[part 2 of 3: package /RB/PT/PCT_TopLvlComposition/SwComponentTypes]
AUTOSAR XML (schema 4-0-3)
package /RB/PT/PCT_TopLvlComposition/SwComponentTypes  (continued)
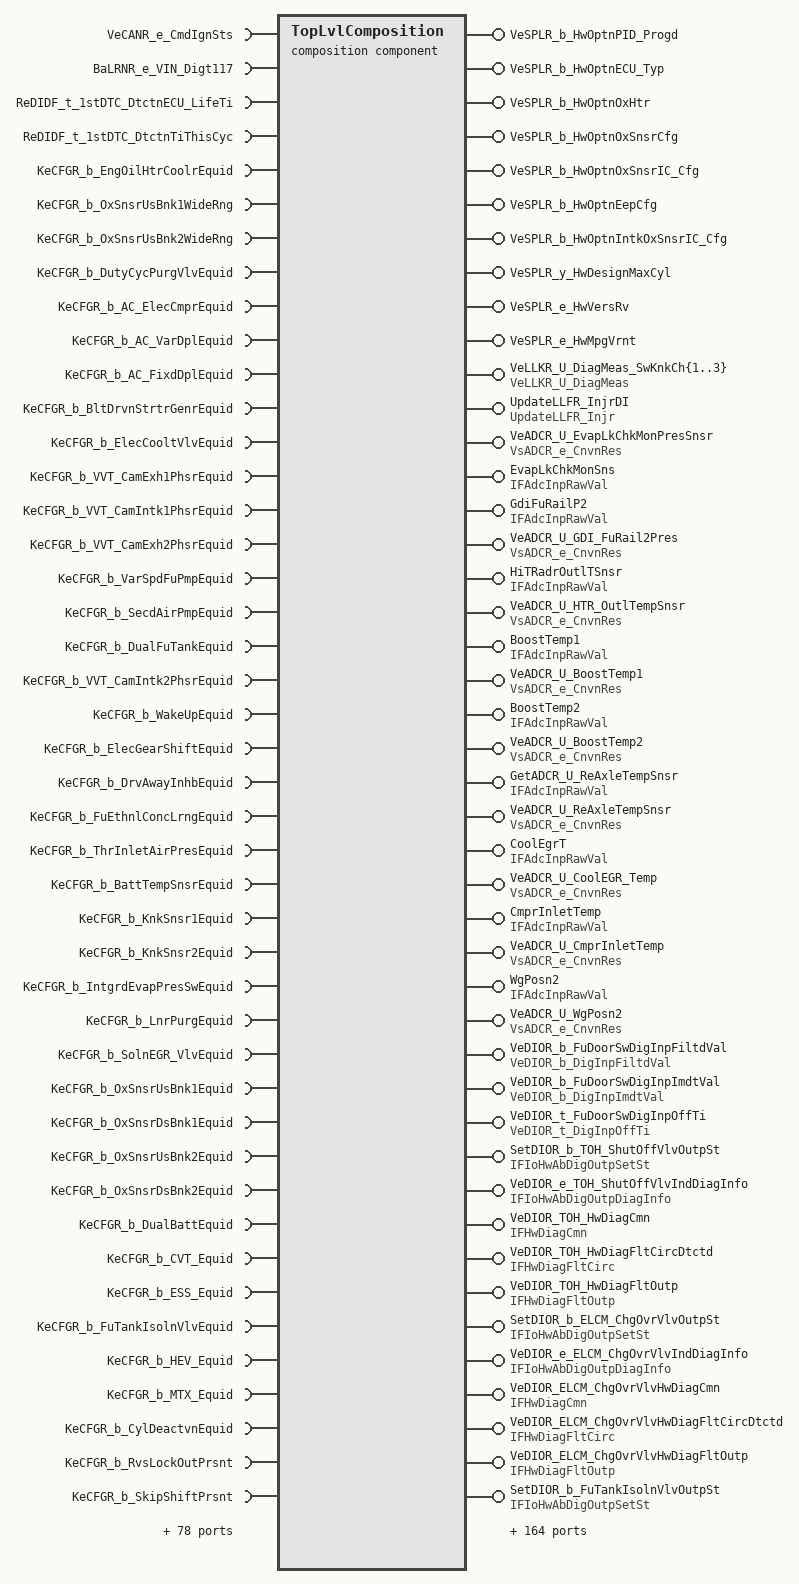
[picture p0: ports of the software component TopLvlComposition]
  composition sw component type TopLvlComposition  (continued)
    66 x require port:
      VeCANR_e_CmdIgnSts: required-interface=VeCANR_e_CmdIgnSts
      BaLRNR_e_VIN_Digt117: required-interface=BaLRNR_e_VIN_Digt117
      ReDIDF_t_1stDTC_DtctnECU_LifeTi: required-interface=ReDIDF_t_1stDTC_DtctnECU_LifeTi
      ReDIDF_t_1stDTC_DtctnTiThisCyc: required-interface=ReDIDF_t_1stDTC_DtctnTiThisCyc
      KeCFGR_b_EngOilHtrCoolrEquid: required-interface=KeCFGR_b_EngOilHtrCoolrEquid
      KeCFGR_b_OxSnsrUsBnk1WideRng: required-interface=KeCFGR_b_OxSnsrUsBnk1WideRng
      KeCFGR_b_OxSnsrUsBnk2WideRng: required-interface=KeCFGR_b_OxSnsrUsBnk2WideRng
      KeCFGR_b_DutyCycPurgVlvEquid: required-interface=KeCFGR_b_DutyCycPurgVlvEquid
      KeCFGR_b_AC_ElecCmprEquid: required-interface=KeCFGR_b_AC_ElecCmprEquid
      KeCFGR_b_AC_VarDplEquid: required-interface=KeCFGR_b_AC_VarDplEquid
      KeCFGR_b_AC_FixdDplEquid: required-interface=KeCFGR_b_AC_FixdDplEquid
      KeCFGR_b_BltDrvnStrtrGenrEquid: required-interface=KeCFGR_b_BltDrvnStrtrGenrEquid
      KeCFGR_b_ElecCooltVlvEquid: required-interface=KeCFGR_b_ElecCooltVlvEquid
      KeCFGR_b_VVT_CamExh1PhsrEquid: required-interface=KeCFGR_b_VVT_CamExh1PhsrEquid
      KeCFGR_b_VVT_CamIntk1PhsrEquid: required-interface=KeCFGR_b_VVT_CamIntk1PhsrEquid
      KeCFGR_b_VVT_CamExh2PhsrEquid: required-interface=KeCFGR_b_VVT_CamExh2PhsrEquid
      KeCFGR_b_VarSpdFuPmpEquid: required-interface=KeCFGR_b_VarSpdFuPmpEquid
      KeCFGR_b_SecdAirPmpEquid: required-interface=KeCFGR_b_SecdAirPmpEquid
      KeCFGR_b_DualFuTankEquid: required-interface=KeCFGR_b_DualFuTankEquid
      KeCFGR_b_VVT_CamIntk2PhsrEquid: required-interface=KeCFGR_b_VVT_CamIntk2PhsrEquid
      KeCFGR_b_WakeUpEquid: required-interface=KeCFGR_b_WakeUpEquid
      KeCFGR_b_ElecGearShiftEquid: required-interface=KeCFGR_b_ElecGearShiftEquid
      KeCFGR_b_DrvAwayInhbEquid: required-interface=KeCFGR_b_DrvAwayInhbEquid
      KeCFGR_b_FuEthnlConcLrngEquid: required-interface=KeCFGR_b_FuEthnlConcLrngEquid
      KeCFGR_b_ThrInletAirPresEquid: required-interface=KeCFGR_b_ThrInletAirPresEquid
      KeCFGR_b_BattTempSnsrEquid: required-interface=KeCFGR_b_BattTempSnsrEquid
      KeCFGR_b_KnkSnsr1Equid: required-interface=KeCFGR_b_KnkSnsr1Equid
      KeCFGR_b_KnkSnsr2Equid: required-interface=KeCFGR_b_KnkSnsr2Equid
      KeCFGR_b_IntgrdEvapPresSwEquid: required-interface=KeCFGR_b_IntgrdEvapPresSwEquid
      KeCFGR_b_LnrPurgEquid: required-interface=KeCFGR_b_LnrPurgEquid
      KeCFGR_b_SolnEGR_VlvEquid: required-interface=KeCFGR_b_SolnEGR_VlvEquid
      KeCFGR_b_OxSnsrUsBnk1Equid: required-interface=KeCFGR_b_OxSnsrUsBnk1Equid
      KeCFGR_b_OxSnsrDsBnk1Equid: required-interface=KeCFGR_b_OxSnsrDsBnk1Equid
      KeCFGR_b_OxSnsrUsBnk2Equid: required-interface=KeCFGR_b_OxSnsrUsBnk2Equid
      KeCFGR_b_OxSnsrDsBnk2Equid: required-interface=KeCFGR_b_OxSnsrDsBnk2Equid
      KeCFGR_b_DualBattEquid: required-interface=KeCFGR_b_DualBattEquid
      KeCFGR_b_CVT_Equid: required-interface=KeCFGR_b_CVT_Equid
      KeCFGR_b_ESS_Equid: required-interface=KeCFGR_b_ESS_Equid
      KeCFGR_b_FuTankIsolnVlvEquid: required-interface=KeCFGR_b_FuTankIsolnVlvEquid
      KeCFGR_b_HEV_Equid: required-interface=KeCFGR_b_HEV_Equid
      KeCFGR_b_MTX_Equid: required-interface=KeCFGR_b_MTX_Equid
      KeCFGR_b_CylDeactvnEquid: required-interface=KeCFGR_b_CylDeactvnEquid
      KeCFGR_b_RvsLockOutPrsnt: required-interface=KeCFGR_b_RvsLockOutPrsnt
      KeCFGR_b_SkipShiftPrsnt: required-interface=KeCFGR_b_SkipShiftPrsnt
      KeCFGR_b_DualLiftEquid: required-interface=KeCFGR_b_DualLiftEquid
      KeCFGR_b_VVT_Equid: required-interface=KeCFGR_b_VVT_Equid
      KeCFGR_b_ImobEquid: required-interface=KeCFGR_b_ImobEquid
      KeCFGR_b_ImobKeyLock: required-interface=KeCFGR_b_ImobKeyLock
      KeCFGR_b_ElecVacPmpEquid: required-interface=KeCFGR_b_ElecVacPmpEquid
      KeCFGR_b_DualVarSpdFuPmpEquid: required-interface=KeCFGR_b_DualVarSpdFuPmpEquid
      KeCFGR_b_CNG_Equid: required-interface=KeCFGR_b_CNG_Equid
      KeCFGR_b_DirectInjSysEquid: required-interface=KeCFGR_b_DirectInjSysEquid
      KeCFGR_b_ElectcATX_Equid: required-interface=KeCFGR_b_ElectcATX_Equid
      KeCFGR_e_FanTypEquid: required-interface=KeCFGR_e_FanTypEquid
      KeCFGR_b_FuTankHiPresSnsrEquid: required-interface=KeCFGR_b_FuTankHiPresSnsrEquid
      KeCFGR_b_HTR_MeclCooltPmpEquid: required-interface=KeCFGR_b_HTR_MeclCooltPmpEquid
      KeCFGR_b_IBS_Equid: required-interface=KeCFGR_b_IBS_Equid
      KeCFGR_b_IBS_3Equid: required-interface=KeCFGR_b_IBS_3Equid
      KeCFGR_b_VVA_Equid: required-interface=KeCFGR_b_VVA_Equid
      KeCFGR_e_EngOilPmpEquid: required-interface=KeCFGR_e_EngOilPmpEquid
      KeCFGR_b_EngOilPresSnsrAnEquid: required-interface=KeCFGR_b_EngOilPresSnsrAnEquid
      KeCFGR_b_ShoRunrVlvEquid: required-interface=KeCFGR_b_ShoRunrVlvEquid
      KeCFGR_b_SupChrgrEquid: required-interface=KeCFGR_b_SupChrgrEquid
      KeCFGR_b_TrboChrgrEquid: required-interface=KeCFGR_b_TrboChrgrEquid
      KeCFGR_e_VehCAN_CfgArch: required-interface=KeCFGR_e_VehCAN_CfgArch
      KeECFR_Cnt_NrOfCyl: required-interface=KeECFR_Cnt_NrOfCyl
    10 x provide port:
      VeSPLR_b_HwOptnPID_Progd: provided-interface=VeSPLR_b_HwOptnPID_Progd
      VeSPLR_b_HwOptnECU_Typ: provided-interface=VeSPLR_b_HwOptnECU_Typ
      VeSPLR_b_HwOptnOxHtr: provided-interface=VeSPLR_b_HwOptnOxHtr
      VeSPLR_b_HwOptnOxSnsrCfg: provided-interface=VeSPLR_b_HwOptnOxSnsrCfg
      VeSPLR_b_HwOptnOxSnsrIC_Cfg: provided-interface=VeSPLR_b_HwOptnOxSnsrIC_Cfg
      VeSPLR_b_HwOptnEepCfg: provided-interface=VeSPLR_b_HwOptnEepCfg
      VeSPLR_b_HwOptnIntkOxSnsrIC_Cfg: provided-interface=VeSPLR_b_HwOptnIntkOxSnsrIC_Cfg
      VeSPLR_y_HwDesignMaxCyl: provided-interface=VeSPLR_y_HwDesignMaxCyl
      VeSPLR_e_HwVersRv: provided-interface=VeSPLR_e_HwVersRv
      VeSPLR_e_HwMpgVrnt: provided-interface=VeSPLR_e_HwMpgVrnt
    require port VsSSKR_h_MIL_Req: required-interface=VsSSKR_h_MIL_Req
    provide port VeLLKR_U_DiagMeas_SwKnkCh{1..3}: provided-interface=VeLLKR_U_DiagMeas
    require port VeCLUR_b_UsPID_EnbldBnk1: required-interface=VeCLUR_b_UsPID_EnbldBnk1
    require port VeFPCR_b_InjrLrnLimpFlg: required-interface=VeFPCR_b_InjrLrnLimpFlg
    provide port UpdateLLFR_InjrDI: provided-interface=UpdateLLFR_Injr
    provide port VeADCR_U_EvapLkChkMonPresSnsr: provided-interface=VsADCR_e_CnvnRes
    provide port EvapLkChkMonSns: provided-interface=IFAdcInpRawVal
    require port KeCFGR_b_EvapLkChkMonSnsAdcInpEquid: required-interface=IO_ChEquid
    require port KeCFGR_b_GdiFuRailP2AdcInpEquid: required-interface=IO_ChEquid
    4 x provide port:
      GdiFuRailP2: provided-interface=IFAdcInpRawVal
      VeADCR_U_GDI_FuRail2Pres: provided-interface=VsADCR_e_CnvnRes
      HiTRadrOutlTSnsr: provided-interface=IFAdcInpRawVal
      VeADCR_U_HTR_OutlTempSnsr: provided-interface=VsADCR_e_CnvnRes
    require port KeCFGR_b_HiTRadrOutlTSnsrAdcInpEquid: required-interface=IO_ChEquid
    require port KeCFGR_b_BoostTemp1AdcInpEquid: required-interface=IO_ChEquid
    provide port BoostTemp1: provided-interface=IFAdcInpRawVal
    provide port VeADCR_U_BoostTemp1: provided-interface=VsADCR_e_CnvnRes
    require port KeCFGR_b_BoostTemp2AdcInpEquid: required-interface=IO_ChEquid
    4 x provide port:
      BoostTemp2: provided-interface=IFAdcInpRawVal
      VeADCR_U_BoostTemp2: provided-interface=VsADCR_e_CnvnRes
      GetADCR_U_ReAxleTempSnsr: provided-interface=IFAdcInpRawVal
      VeADCR_U_ReAxleTempSnsr: provided-interface=VsADCR_e_CnvnRes
    require port KeCFGR_b_ReAxleTempSnsrAdcInpEquid: required-interface=IO_ChEquid
    provide port CoolEgrT: provided-interface=IFAdcInpRawVal
    provide port VeADCR_U_CoolEGR_Temp: provided-interface=VsADCR_e_CnvnRes
    require port KeCFGR_b_CoolEgrTAdcInpEquid: required-interface=IO_ChEquid
    provide port CmprInletTemp: provided-interface=IFAdcInpRawVal
    provide port VeADCR_U_CmprInletTemp: provided-interface=VsADCR_e_CnvnRes
    require port KeCFGR_b_CmprInletTempAdcInpEquid: required-interface=IO_ChEquid
    provide port WgPosn2: provided-interface=IFAdcInpRawVal
    provide port VeADCR_U_WgPosn2: provided-interface=VsADCR_e_CnvnRes
    require port KeCFGR_b_WgPosn2AdcInpEquid: required-interface=IO_ChEquid
    provide port VeDIOR_b_FuDoorSwDigInpFiltdVal: provided-interface=VeDIOR_b_DigInpFiltdVal
    provide port VeDIOR_b_FuDoorSwDigInpImdtVal: provided-interface=VeDIOR_b_DigInpImdtVal
    provide port VeDIOR_t_FuDoorSwDigInpOffTi: provided-interface=VeDIOR_t_DigInpOffTi
    require port KeCFGR_b_FuDoorDigInpEquid: required-interface=IO_ChEquid
    5 x provide port:
      SetDIOR_b_TOH_ShutOffVlvOutpSt: provided-interface=IFIoHwAbDigOutpSetSt
      VeDIOR_e_TOH_ShutOffVlvIndDiagInfo: provided-interface=IFIoHwAbDigOutpDiagInfo
      VeDIOR_TOH_HwDiagCmn: provided-interface=IFHwDiagCmn
      VeDIOR_TOH_HwDiagFltCircDtctd: provided-interface=IFHwDiagFltCirc
      VeDIOR_TOH_HwDiagFltOutp: provided-interface=IFHwDiagFltOutp
    require port KeCFGR_b_TOH_ChEquid: required-interface=IO_ChEquid
    5 x provide port:
      SetDIOR_b_ELCM_ChgOvrVlvOutpSt: provided-interface=IFIoHwAbDigOutpSetSt
      VeDIOR_e_ELCM_ChgOvrVlvIndDiagInfo: provided-interface=IFIoHwAbDigOutpDiagInfo
      VeDIOR_ELCM_ChgOvrVlvHwDiagCmn: provided-interface=IFHwDiagCmn
      VeDIOR_ELCM_ChgOvrVlvHwDiagFltCircDtctd: provided-interface=IFHwDiagFltCirc
      VeDIOR_ELCM_ChgOvrVlvHwDiagFltOutp: provided-interface=IFHwDiagFltOutp
    require port KeCFGR_b_ELCM_ChgOvrVlv_ChEquid: required-interface=IO_ChEquid
    5 x provide port:
      SetDIOR_b_FuTankIsolnVlvOutpSt: provided-interface=IFIoHwAbDigOutpSetSt
      VeDIOR_e_FuTankIsolnVlvIndDiagInfo: provided-interface=IFIoHwAbDigOutpDiagInfo
      VeDIOR_FuTankIsolnVlvHwDiagCmn: provided-interface=IFHwDiagCmn
      VeDIOR_FuTankIsolnVlvHwDiagFltCircDtctd: provided-interface=IFHwDiagFltCirc
      VeDIOR_FuTankIsolnVlvHwDiagFltOutp: provided-interface=IFHwDiagFltOutp
    require port KeCFGR_b_FuTankIsolnVlv_ChEquid: required-interface=IO_ChEquid
    5 x provide port:
      SetDIOR_b_FuDoorOutpSt: provided-interface=IFIoHwAbDigOutpSetSt
      VeDIOR_e_FuDoorIndDiagInfo: provided-interface=IFIoHwAbDigOutpDiagInfo
      VeDIOR_FuDoor_HwDiagCmn: provided-interface=IFHwDiagCmn
      VeDIOR_FuDoor_HwDiagFltCircDtctd: provided-interface=IFHwDiagFltCirc
      VeDIOR_FuDoor_HwDiagFltOutp: provided-interface=IFHwDiagFltOutp
    require port KeCFGR_b_FuDoor_ChEquid: required-interface=IO_ChEquid
    5 x provide port:
      SetDIOR_b_SrgSoln2OutpSt: provided-interface=IFIoHwAbDigOutpSetSt
      VeDIOR_e_SrgSoln2IndDiagInfo: provided-interface=IFIoHwAbDigOutpDiagInfo
      VeDIOR_SrgSoln2_HwDiagCmn: provided-interface=IFHwDiagCmn
      VeDIOR_SrgSoln2_HwDiagFltCircDtctd: provided-interface=IFHwDiagFltCirc
      VeDIOR_SrgSoln2_HwDiagFltOutp: provided-interface=IFHwDiagFltOutp
    require port KeCFGR_b_SrgSoln2_ChEquid: required-interface=IO_ChEquid
    5 x provide port:
      SetDIOR_b_DualFuTankEnblRlyOutpSt: provided-interface=IFIoHwAbDigOutpSetSt
      VeDIOR_e_DualFuTankEnblRlyIndDiagInfo: provided-interface=IFIoHwAbDigOutpDiagInfo
      VeDIOR_DualFuTankEnblRly_HwDiagCmn: provided-interface=IFHwDiagCmn
      VeDIOR_DualFuTankEnblRly_HwDiagFltCircDtctd: provided-interface=IFHwDiagFltCirc
      VeDIOR_DualFuTankEnblRly_HwDiagFltOutp: provided-interface=IFHwDiagFltOutp
    require port KeCFGR_b_DualFuTankEnblRly_ChEquid: required-interface=IO_ChEquid
    provide port GetSNTR_e_CEGR_PosnSns: provided-interface=GetSNTR_MsgData
    provide port GetSNTR_e_GPF_DeltAbsPresSnsr1: provided-interface=GetSNTR_MsgData
    provide port GetSNTR_e_GPF_DeltAbsPresSnsr2: provided-interface=GetSNTR_MsgData
    6 x require port:
      KeCFGR_b_CEGR_PosnSnsChEquid: required-interface=IO_ChEquid
      KsSNTR_h_DeltAbsPresSnsr1_SENTCfg: required-interface=SENTIfCfg
      KsSNTR_h_DeltAbsPresSnsr2_SENTCfg: required-interface=SENTIfCfg
      KeCFGR_b_GPF_DeltAbsPresSnsr2Equid: required-interface=IO_ChEquid
      KeCFGR_b_GPF_DeltAbsPresSnsr1Equid: required-interface=IO_ChEquid
      KsSNTR_h_CEGR_PosnSns_SENTCfg: required-interface=SENTIfCfg
    25 x provide port:
      SetDIOR_e_PurgSoln2_OutpOps: provided-interface=IFIoHwAbPWMOutpSet
      VeDIOR_e_PurgSoln2_IndDiagInfo: provided-interface=IFIoHwAbPwmOutpDiagInfo
      SetDIOR_e_ELCM_VacPmpOutpOps: provided-interface=IFIoHwAbPWMOutpSet
      SetDIOR_e_WgSolnOutpOps: provided-interface=IFIoHwAbPWMOutpSet
      SetDIOR_e_FuPmpCtlMdul2CmdOutpOps: provided-interface=IFIoHwAbPWMOutpSet
      SetDIOR_e_HTR_TempCtrlVlvSolnOutpOps: provided-interface=IFIoHwAbPWMOutpSet
      VeDIOR_e_ELCM_VacPmpIndDiagInfo: provided-interface=IFIoHwAbPwmOutpDiagInfo
      VeDIOR_e_WgSolnIndDiagInfo: provided-interface=IFIoHwAbPwmOutpDiagInfo
      VeDIOR_e_FuPmpCtlMdul2CmdIndDiagInfo: provided-interface=IFIoHwAbPwmOutpDiagInfo
      VeDIOR_e_HTR_TempCtrlVlvSolnIndDiagInfo: provided-interface=IFIoHwAbPwmOutpDiagInfo
      VeDIOR_PurgSoln2_HwDiagFltOutp: provided-interface=IFHwDiagFltOutp
      VeDIOR_ELCM_VacPmp_HwDiagFltOutp: provided-interface=IFHwDiagFltOutp
      VeDIOR_WgSoln_HwDiagFltOutp: provided-interface=IFHwDiagFltOutp
      VeDIOR_FuPmpCtlMdul2Cmd_HwDiagFltOutp: provided-interface=IFHwDiagFltOutp
      VeDIOR_HTR_TempCtrlVlvSoln_HwDiagFltOutp: provided-interface=IFHwDiagFltOutp
      VeDIOR_PurgSoln2_HwDiagCmn: provided-interface=IFHwDiagCmn
      VeDIOR_ELCM_VacPmp_HwDiagCmn: provided-interface=IFHwDiagCmn
      VeDIOR_WgSoln_HwDiagCmn: provided-interface=IFHwDiagCmn
      VeDIOR_FuPmpCtlMdul2Cmd_HwDiagCmn: provided-interface=IFHwDiagCmn
      VeDIOR_HTR_TempCtrlVlvSoln_HwDiagCmn: provided-interface=IFHwDiagCmn
      VeDIOR_PurgSoln2_HwDiagFltCircDtctd: provided-interface=IFHwDiagFltCirc
      VeDIOR_ELCM_VacPmp_HwDiagFltCircDtctd: provided-interface=IFHwDiagFltCirc
      VeDIOR_WgSoln_HwDiagFltCircDtctd: provided-interface=IFHwDiagFltCirc
      VeDIOR_FuPmpCtlMdul2Cmd_HwDiagFltCircDtctd: provided-interface=IFHwDiagFltCirc
      VeDIOR_HTR_TempCtrlVlvSoln_HwDiagFltCircDtctd: provided-interface=IFHwDiagFltCirc
    5 x require port, all with required-interface=IO_ChEquid:
      KeCFGR_b_PurgSoln2_ChEquid
      KeCFGR_b_ELCM_VacPmp_ChEquid
      KeCFGR_b_WgSoln_ChEquid
      KeCFGR_b_FuPmpCtlMdul2Cmd_ChEquid
      KeCFGR_b_HTR_TempCtrlVlvSoln_ChEquid
    provide port VeEVIR_t_EvapSysPresSwExclPrd: provided-interface=VeEVIR_t_EvapSysPresSwExclPrd
    provide port VeLLTR_t_ShutDwnTmr: provided-interface=VeLLTR_t_ShutDwnTmr
    4 x require port:
      RP_MilHndlr_InPlaModeActvSts: required-interface=VeIPMR_b_EOL_InPlaMode
      RP_MilHndlr_InPlaModeMILReqSts: required-interface=VeIPMR_b_EOL_MIL_Req
      RP_MilHndlr_ExternalMilReq: required-interface=VsSSKR_h_MIL_Req
      RP_MilHndlr_CatDmgingMilReq: required-interface=VeMFDR_b_CatFls_MIL
    6 x provide port:
      VeLINR_b_LTR_RespErrLTR_Pmp: provided-interface=VeLINR_b_LTR_RespErrLTR_Pmp
      SendLINR_LCVM_CalRqrd: provided-interface=SendLINR_LCVM_CalRqrd
      VeLINR_Pct_LCVM_PosnActr: provided-interface=VeLINR_Pct_LCVM_PosnActr
      VeLINR_e_PCPM_DryRunErr: provided-interface=VeLINR_e_PCPM_DryRunErr
      VeLINR_e_LTR_PmpDryRunErr: provided-interface=VeLINR_e_LTR_PmpDryRunErr
      SendLINR_PLA_ReqData: provided-interface=SendLINR_PLA_ReqData
    6 x require port:
      SendCANR_HoursOilLifeRst_FD3Vld: required-interface=SendCANR_HoursOilLifeRst_FD3Vld
      VeSSFR_b_LvlInitMdulRstReq: required-interface=IF_VeSSFR_b_LvlInitMdulRstReq
      VeSSRR_b_L2_MdulRstReqEngSpdLimChk: required-interface=IF_VeSSRR_b_L2_MdulRstReqEngSpdLimChk
      VeSSRR_b_L2_MdulRstReqFailClrChk: required-interface=IF_VeSSRR_b_L2_MdulRstReqFailClrChk
      VeSSRR_b_L2_MdulRstReqInjrMtrTest: required-interface=IF_VeSSRR_b_L2_MdulRstReqInjrMtrTest
      VeSSRR_b_L2_MdulRstReqPFChk: required-interface=IF_VeSSRR_b_L2_MdulRstReqPFChk
    80 x provide port:
      VaLLSR_b_DisPthTstRslt: provided-interface=IF_VaLLSR_b_DisPthTstRslt
      SendLINR_PLA_RgtrPrm: provided-interface=SendLINR_PLA_RgtrPrm
      SendLINR_PLA_RmpCutOffSpd: provided-interface=SendLINR_PLA_RmpCutOffSpd
      SendLINR_PLA_ThermProtn: provided-interface=SendLINR_PLA_ThermProtn
      VeLINR_Pct_PLA_ExctDC: provided-interface=VeLINR_Pct_PLA_ExctDC
      VeLINR_b_PLA_FltHt: provided-interface=VeLINR_b_PLA_FltHt
      VeLINR_b_PLA_FltElec: provided-interface=VeLINR_b_PLA_FltElec
      VeLINR_b_PLA_FltMec: provided-interface=VeLINR_b_PLA_FltMec
      VeLINR_y_PLA_ReqdRespData: provided-interface=VeLINR_y_PLA_ReqdRespData
      VeLINR_e_PLA_ReqDataResp: provided-interface=VeLINR_e_PLA_ReqDataResp
      SendLINR_PLA_SetVolt: provided-interface=SendLINR_PLA_SetVolt
      SendLINR_PLA_ExctLim: provided-interface=SendLINR_PLA_ExctLim
      SendLINR_PLA_RmpTi: provided-interface=SendLINR_PLA_RmpTi
      VeLINR_b_PLA_RespErr: provided-interface=VeLINR_b_PLA_RespErr
      VeLINR_b_PLA_FltTO: provided-interface=VeLINR_b_PLA_FltTO
      VeLINR_y_AGS_ErrLIN: provided-interface=VeLINR_y_AGS_ErrLIN
      VeLINR_U_LTR_PmpVolt: provided-interface=VeLINR_U_LTR_PmpVolt
      VeLINR_b_PCPM_RespErr: provided-interface=VeLINR_b_PCPM_RespErr
      VeLINR_e_PCPM_OvrCurrErr: provided-interface=VeLINR_e_PCPM_OvrCurrErr
      VeLINR_e_PCPM_UnblkgActv: provided-interface=VeLINR_e_PCPM_UnblkgActv
      VeLINR_Pct_LTR_PmpRPM_Act: provided-interface=VeLINR_Pct_LTR_PmpRPM_Act
      SendLINR_LTR_PmpRPM_Req: provided-interface=SendLINR_LTR_PmpRPM_Req
      SendLINR_PCPM_RPM_Req: provided-interface=SendLINR_PCPM_RPM_Req
      SendLINR_HAPM_RPM_Req: provided-interface=SendLINR_HAPM_RPM_Req
      VeLINR_Pct_PCPM_RPM_Act: provided-interface=VeLINR_Pct_PCPM_RPM_Act
      VeLINR_Pct_HAPM_RPM_Act: provided-interface=VeLINR_Pct_HAPM_RPM_Act
      VeLINR_e_HAPM_UnblkgActv: provided-interface=VeLINR_e_HAPM_UnblkgActv
      VeLINR_e_HAPM_DryRunErr: provided-interface=VeLINR_e_HAPM_DryRunErr
      VeLINR_b_HAPM_RespErr: provided-interface=VeLINR_b_HAPM_RespErr
      VeLINR_e_HAPM_OvrCurrErr: provided-interface=VeLINR_e_HAPM_OvrCurrErr
      VeLINR_b_AGS_CalActv: provided-interface=VeLINR_b_AGS_CalActv
      VeLINR_b_AGS_CalSts: provided-interface=VeLINR_b_AGS_CalSts
      VeLINR_e_AGS_CurrentPosn: provided-interface=VeLINR_e_AGS_CurrentPosn
      VeLINR_b_AGS_ErrMeclBreakDtctd: provided-interface=VeLINR_b_AGS_ErrMeclBreakDtctd
      VeLINR_b_AGS_ErrMeclStkDtctd: provided-interface=VeLINR_b_AGS_ErrMeclStkDtctd
      VeLINR_b_AGS_ErrOvrTemp: provided-interface=VeLINR_b_AGS_ErrOvrTemp
      VeLINR_b_AGS_ErrOvrVolt: provided-interface=VeLINR_b_AGS_ErrOvrVolt
      VeLINR_b_AGS_ErrUndrVolt: provided-interface=VeLINR_b_AGS_ErrUndrVolt
      VeLINR_b_AGS_RespErr: provided-interface=VeLINR_b_AGS_RespErr
      SendLINR_AGS_CalReq: provided-interface=SendLINR_AGS_CalReq
      SendLINR_AGS_PosnReq: provided-interface=SendLINR_AGS_PosnReq
      SendLINR_LTR_PmpPostRunReq: provided-interface=SendLINR_LTR_PmpPostRunReq
      VeLINR_e_LTR_PmpNodErr: provided-interface=VeLINR_e_LTR_PmpNodErr
      VeLINR_e_LTR_PmpOvrCurrErr: provided-interface=VeLINR_e_LTR_PmpOvrCurrErr
      VeLINR_e_LTR_PmpOvrTempErr: provided-interface=VeLINR_e_LTR_PmpOvrTempErr
      VeLINR_e_LTR_PmpPostRunSts: provided-interface=VeLINR_e_LTR_PmpPostRunSts
      VeLINR_Pct_LTR_PmpRPM_Tar: provided-interface=VeLINR_Pct_LTR_PmpRPM_Tar
      VeLINR_y_LCVM_CalSts: provided-interface=VeLINR_y_LCVM_CalSts
      SendLINR_LCVM_PosnReq: provided-interface=SendLINR_LCVM_PosnReq
      VeLINR_b_LCVM_RespErr: provided-interface=VeLINR_b_LCVM_RespErr
      VeLINR_e_LCVM_Err: provided-interface=VeLINR_e_LCVM_Err
      SendLINR_AGS_BoostReq: provided-interface=SendLINR_AGS_BoostReq
      VeLINR_Pct_HAPM_RPM_Tar: provided-interface=VeLINR_Pct_HAPM_RPM_Tar
      SendLINR_HAPM_PostRunReq: provided-interface=SendLINR_HAPM_PostRunReq
      VeLINR_e_HAPM_PostRunSts: provided-interface=VeLINR_e_HAPM_PostRunSts
      VeLINR_e_HAPM_OvrTempErr: provided-interface=VeLINR_e_HAPM_OvrTempErr
      VeLINR_e_HAPM_NodErr: provided-interface=VeLINR_e_HAPM_NodErr
      VeLINR_e_LTR_PmpAirPresErr: provided-interface=VeLINR_e_LTR_PmpAirPresErr
      SendLINR_PCPM_PostRunReq: provided-interface=SendLINR_PCPM_PostRunReq
      VeLINR_e_PCPM_PostRunSts: provided-interface=VeLINR_e_PCPM_PostRunSts
      VeLINR_e_PCPM_OvrTempErr: provided-interface=VeLINR_e_PCPM_OvrTempErr
      VeLINR_e_PCPM_NodErr: provided-interface=VeLINR_e_PCPM_NodErr
      VeLINR_e_LTR_PmpVoltErr: provided-interface=VeLINR_e_LTR_PmpVoltErr
      SendLINR_LCVM_PosnSaved: provided-interface=SendLINR_LCVM_PosnSaved
      SendLINR_AGS2_BoostReq: provided-interface=SendLINR_AGS2_BoostReq
      SendLINR_AGS2_CalReq: provided-interface=SendLINR_AGS2_CalReq
      SendLINR_AGS2_PosnReq: provided-interface=SendLINR_AGS2_PosnReq
      VeLINR_b_AGS2_CalActv: provided-interface=VeLINR_b_AGS2_CalActv
      VeLINR_b_AGS2_CalSts: provided-interface=VeLINR_b_AGS2_CalSts
      VeLINR_b_AGS2_ErrMeclBreakDtctd: provided-interface=VeLINR_b_AGS2_ErrMeclBreakDtctd
      VeLINR_b_AGS2_ErrMeclStkDtctd: provided-interface=VeLINR_b_AGS2_ErrMeclStkDtctd
      VeLINR_b_AGS2_ErrOvrTemp: provided-interface=VeLINR_b_AGS2_ErrOvrTemp
      VeLINR_b_AGS2_ErrOvrVolt: provided-interface=VeLINR_b_AGS2_ErrOvrVolt
      VeLINR_b_AGS2_ErrUndrVolt: provided-interface=VeLINR_b_AGS2_ErrUndrVolt
      VeLINR_b_AGS2_RespErr: provided-interface=VeLINR_b_AGS2_RespErr
      VeLINR_e_AGS2_CurrentPosn: provided-interface=VeLINR_e_AGS2_CurrentPosn
      VeLINR_y_AGS2_ErrLIN: provided-interface=VeLINR_y_AGS2_ErrLIN
      VeLINR_e_PCPM_VoltErr: provided-interface=VeLINR_e_PCPM_VoltErr
      VeLINR_e_HAPM_VoltErr: provided-interface=VeLINR_e_HAPM_VoltErr
      VeLINR_Pct_PCPM_RPM_Tar: provided-interface=VeLINR_Pct_PCPM_RPM_Tar
    15 x require port:
      SignalLINR_AAD_RdyForSleep: required-interface=SignalLINR_AAD_RdyForSleep
      SignalLINR_AGS_RdyForSleep: required-interface=SignalLINR_AGS_RdyForSleep
      SignalLINR_AGS2_RdyForSleep: required-interface=SignalLINR_AGS2_RdyForSleep
      SignalLINR_EEV1_RdyForSleep: required-interface=SignalLINR_EEV1_RdyForSleep
      SignalLINR_EEV2_RdyForSleep: required-interface=SignalLINR_EEV2_RdyForSleep
      SignalLINR_GEN1_RdyForSleep: required-interface=SignalLINR_GEN1_RdyForSleep
      SignalLINR_HAPM_RdyForSleep: required-interface=SignalLINR_HAPM_RdyForSleep
      SignalLINR_LCVM_RdyForSleep: required-interface=SignalLINR_LCVM_RdyForSleep
      SignalLINR_LCVM2_RdyForSleep: required-interface=SignalLINR_LCVM2_RdyForSleep
      SignalLINR_LTR_RdyForSleep: required-interface=SignalLINR_LTR_RdyForSleep
      SignalLINR_PCPM_RdyForSleep: required-interface=SignalLINR_PCPM_RdyForSleep
      SignalLINR_PLA_RdyForSleep: required-interface=SignalLINR_PLA_RdyForSleep
      SignalLINR_RATVM_RdyForSleep: required-interface=SignalLINR_RATVM_RdyForSleep
      SendCANR_ImobCodReq: required-interface=SendCANR_ImobCodReq
      SendCANR_ImobCodReqVld: required-interface=SendCANR_ImobCodReqVld
    29 x provide port:
      VeRbBSW_b_AC_CluRlyPwrDwnRqrdMaiRly: provided-interface=IFIoHwPwrDwnRqrdMaiRly
      VeRbBSW_b_DMTLLkPmpPwrDwnRqrdMaiRly: provided-interface=IFIoHwPwrDwnRqrdMaiRly
      VeRbBSW_b_InrushCircRlyPwrDwnRqrdMaiRly: provided-interface=IFIoHwPwrDwnRqrdMaiRly
      VeRbBSW_b_LoPresFuPmpRlyPwrDwnRqrdMaiRly: provided-interface=IFIoHwPwrDwnRqrdMaiRly
      VeRbBSW_b_MakeUpAirVlvPwrDwnRqrdMaiRly: provided-interface=IFIoHwPwrDwnRqrdMaiRly
      VeRbBSW_b_OBD_PurgVentVlvPwrDwnRqrdMaiRly: provided-interface=IFIoHwPwrDwnRqrdMaiRly
      VeRbBSW_b_TOH_ShutOffVlvPwrDwnRqrdMaiRly: provided-interface=IFIoHwPwrDwnRqrdMaiRly
      VeRbBSW_b_RadrFanRlyHiSpdPwrDwnRqrdMaiRly: provided-interface=IFIoHwPwrDwnRqrdMaiRly
      VeRbBSW_b_SrgSoln1PwrDwnRqrdMaiRly: provided-interface=IFIoHwPwrDwnRqrdMaiRly
      VeRbBSW_b_StrtrRlyPwrDwnRqrdMaiRly: provided-interface=IFIoHwPwrDwnRqrdMaiRly
      VeRbBSW_b_SwilEngMnt1PwrDwnRqrdMaiRly: provided-interface=IFIoHwPwrDwnRqrdMaiRly
      VeRbBSW_b_SwilEngMnt2PwrDwnRqrdMaiRly: provided-interface=IFIoHwPwrDwnRqrdMaiRly
      VeRbBSW_b_OilShutOffVlvPwrDwnRqrdMaiRly: provided-interface=IFIoHwPwrDwnRqrdMaiRly
      VeRbBSW_b_SecdAirShutOffSoln1PwrDwnRqrdMaiRly: provided-interface=IFIoHwPwrDwnRqrdMaiRly
      VeRbBSW_b_SecdAirPmpRlyPwrDwnRqrdMaiRly: provided-interface=IFIoHwPwrDwnRqrdMaiRly
      VeRbBSW_b_VapBlockingVlvPwrDwnRqrdMaiRly: provided-interface=IFIoHwPwrDwnRqrdMaiRly
      VeRbBSW_b_ElectcVacPmpRlyPwrDwnRqrdMaiRly: provided-interface=IFIoHwPwrDwnRqrdMaiRly
      VeRbBSW_b_MaiRlyPwrDwnRqrdMaiRly: provided-interface=IFIoHwPwrDwnRqrdMaiRly
      VeRbBSW_b_ELCM_ChgOvrVlvPwrDwnRqrdMaiRly: provided-interface=IFIoHwPwrDwnRqrdMaiRly
      VeRbBSW_b_FuTankIsolnVlvPwrDwnRqrdMaiRly: provided-interface=IFIoHwPwrDwnRqrdMaiRly
      VeRbBSW_b_FuDoorPwrDwnRqrdMaiRly: provided-interface=IFIoHwPwrDwnRqrdMaiRly
      VeRbBSW_b_SrgSoln2PwrDwnRqrdMaiRly: provided-interface=IFIoHwPwrDwnRqrdMaiRly
      VeRbBSW_b_DualFuTankEnblRlyPwrDwnRqrdMaiRly: provided-interface=IFIoHwPwrDwnRqrdMaiRly
      VeDIOR_e_MaiRlyIndDiagInfo: provided-interface=IFIoHwAbDigOutpDiagInfo
      VeDIOR_VvtIntk1_HwDiagFltOutp: provided-interface=IFHwDiagFltOutp
      VeDIOR_VvtIntk1_HwDiagCmn: provided-interface=IFHwDiagCmn
      SetDIOR_e_VvtIntk1OutpOps: provided-interface=IFIoHwAbPWMOutpSet
      VeDIOR_e_VvtIntk1IndDiagInfo: provided-interface=IFIoHwAbPwmOutpDiagInfo
      VeDIOR_VvtIntk1_HwDiagFltCircDtctd: provided-interface=IFHwDiagFltCirc
    require port KeCFGR_b_VvtIntk1_ChEquid: required-interface=IO_ChEquid
    66 x component:
      CPT_BswM: type=BswM
      CPT_Dem: type=Dem
      CPT_FiM: type=FiM
      CPT_rba_SyC_States: type=rba_SyC_States
      CPT_EcuM: type=EcuM
      CPT_NvM: type=NvM
      CPT_rba_IoSigDio: type=rba_IoSigDio
      CPT_rba_IoSigAdc: type=rba_IoSigAdc
      CPT_rba_IoSigPwm: type=rba_IoSigPwm
      CPT_rba_IoSigPwr: type=rba_IoSigPwr
      CPT_rba_IoSigRtc: type=rba_IoSigRtc
      CPT_rba_IoDiagPwr: type=rba_IoDiagPwr
      CPT_rba_IoSigObs: type=rba_IoSigObs
      CPT_WdgM: type=WdgM
      CPT_rba_IoSigIcu: type=rba_IoSigIcu
      CPT_rba_IoDiagPs: type=rba_IoDiagPs
      CPT_Dcm: type=Dcm
      CPT_ComDia_Dcm_Rte_Adapter: type=ComDia_Dcm_Rte_Adapter
      CPT_ComM: type=ComM
      CPT_Det: type=Det
      CPT_Csm: type=Csm
      CPT_SecOC: type=SecOC
      CPT_rba_IoSigHlfBr: type=rba_IoSigHlfBr
      CPT_rba_IoDiagHlfBr: type=rba_IoDiagHlfBr
      CPT_rba_IoDiagHbr: type=rba_IoDiagHbr
      CPT_rba_DiagLib: type=rba_DiagLib
      CPT_rba_OsArSchedExtn_OS: type=rba_OsArSchedExtn_OS
      CPT_rba_OsShell: type=rba_OsShell
      CPT_SysC_Ladp: type=SysC_Ladp
      CPT_esc_stack: type=esc_stack
      CPT_Epm_Ladp: type=Epm_Ladp
      CPT_ESC_Ladp: type=ESC_Ladp
      CPT_esc_tasklink: type=esc_tasklink
      CPT_KeyM: type=KeyM
      CPT_ESC_HwIntrptEveGen: type=ESC_HwIntrptEveGen
      CPT_ESC_OsTskActvnHndlr: type=ESC_OsTskActvnHndlr
      CPT_ESC_EveCfg: type=ESC_EveCfg
      CPT_ComVeh: type=ComVeh
      CPT_ComCIL_Adapt: type=SWC_ComCIL_Adapt
      CPT_Cdd_Composition: type=Cdd_Composition
      CPT_IoSigAdc_SwSStellantisCmpstn: type=IoSigAdc_SwSStellantisCmpstn
      CPT_IoSigAdc_SwSStellantisParm: type=IoSigAdc_SwSStellantisParm
      CPT_IoSigDioInp_SwSStellantisParam: type=IoSigDioInp_SwSStellantisParam
      CPT_IoSigDioInp_SwSStellantisCmpstn: type=IoSigDioInp_SwSStellantisCmpstn
      CPT_IoSigDioOutp_SwSStellantisCmpstn: type=IoSigDioOutp_SwSStellantisCmpstn
      CPT_IoSigDioOutp_SwSStellantisParam: type=IoSigDioOutp_SwSStellantisParam
      CPT_IoSigHbrdg_SwSStellantisCmpstn: type=IoSigHbrdg_SwSStellantisCmpstn
      CPT_IoSigIfAdapt_SwSStellantisCmpstn: type=IoSigIfAdapt_SwSStellantisCmpstn
      CPT_IoSigPwmInp_SwSStellantisCmpstn: type=IoSigPwmInp_SwSStellantisCmpstn
      CPT_IoSigPwmInp_SwSStellantisParm: type=IoSigPwmInp_SwSStellantisParm
      CPT_IoSigPwmOutp_SwSStellantisCmpstn: type=IoSigPwmOutp_SwSStellantisCmpstn
      CPT_IoSigPwmOutp_SwSStellantisParm: type=IoSigPwmOutp_SwSStellantisParm
      CPT_IoSigPwr_SwSStellantisCmpstn: type=IoSigPwr_SwSStellantisCmpstn
      CPT_SentStack_SwSStellantisCmpstn: type=SentStack_SwSStellantisCmpstn
      CPT_SentStack_SwSStellantisParm: type=SentStack_SwSStellantisParm
      CPT_SWC_VcodProxi: type=SWC_VcodProxi
      CPT_rbm_DSM_Conf: type=rbm_DSM_Conf
      CPT_rba_SyC_States_Cfg_2_Q_1: type=rba_SyC_States_Cfg_2_Q_1
      CPT_rba_SyC_States_Cfg_0_Q_1: type=rba_SyC_States_Cfg_0_Q_1
      CPT_rba_SyC_States_Cfg_3_Q_1: type=rba_SyC_States_Cfg_3_Q_1
      CPT_rba_SyC_States_Cfg_1_B_1: type=rba_SyC_States_Cfg_1_B_1
      CPT_rba_SyC_States_Cfg_1_Q_1: type=rba_SyC_States_Cfg_1_Q_1
      CPT_rbf_SftyHw_ErrMngtModl: type=rbf_SftyHw_ErrMngtModl
      CPT_rbf_SftyHw_ShtOffPahPwrStg: type=rbf_SftyHw_ShtOffPahPwrStg
      CPT_rbf_SftyHw_ProgFlowChk: type=rbf_SftyHw_ProgFlowChk
      CPT_rbm_MilHndlr: type=rbm_MilHndlr
    connect CPT_ComDia_Dcm_Rte_Adapter.PP_CallbackDCMRequestServices -> CPT_Dcm.CallbackDCMRequestServices_Rq0
    connect CPT_esc_stack.PP_ESC_PushSampTime -> CPT_esc_stack.RP_ESC_PushSampTime, variation-point={short-label=VP_ASC_CPT_esc_stack_PP_ESC_PushSampTime_CPT_esc_stack_RP_ESC_PushSampTime, sw-syscond=( ( /RB/PT/Common/SwSystemconsts/Adjustables/ESC_SYNCTASK_SC != 1) )&&( ( /RB/PT/Common/SwSystemconsts/Adjustables/ESC_SYNCTASK_SC != 1) )}
    connect CPT_Epm_Ladp.PP_EpmSeq_numInt -> CPT_esc_tasklink.RP_EpmSeq_numInt
    connect CPT_esc_tasklink.PP_ESC_Tasklink_SyncS1_TRIGSRC -> CPT_esc_stack.RP_ESC_Tasklink_SyncS1_TRIGSRC, variation-point={short-label=VP_ASC_CPT_esc_tasklink_PP_ESC_Tasklink_SyncS1_TRIGSRC_CPT_esc_stack_RP_ESC_Tasklink_SyncS1_TRIGSRC, sw-syscond=( ( /RB/PT/Common/SwSystemconsts/Adjustables/ESC_SYNCTASK_SC != 1) )}
    connect CPT_esc_tasklink.PP_ESC_Tasklink_EpmNoSync_TRIGSRC -> CPT_esc_tasklink.RP_ESC_Tasklink_EpmNoSync_TRIGSRC
    connect CPT_SysC_Ladp.PP_SyC_tiDrv -> CPT_esc_tasklink.RP_SyC_tiDrv
    connect CPT_esc_stack.PP_rbm_ESC_tiSampling_s -> CPT_ESC_Ladp.RP_rbm_ESC_tiSampling_s
    connect CPT_esc_tasklink.PP_ESC_Tasklink_Mo_SyncS0_TRIGSRC -> CPT_esc_tasklink.RP_ESC_Tasklink_Mo_SyncS0_TRIGSRC
    connect CPT_Epm_Ladp.PP_EpmCrS_tiSegCurr -> CPT_esc_stack.RP_EpmCrS_tiSegCurr, variation-point={short-label=VP_ASC_CPT_Epm_Ladp_PP_EpmCrS_tiSegCurr_CPT_esc_stack_RP_EpmCrS_tiSegCurr, sw-syscond=( ( /RB/PT/Common/SwSystemconsts/Adjustables/ESC_SYNCTASK_SC != 1) )&&( ( /RB/PT/Common/SwSystemconsts/Adjustables/ESC_SYNCTASK_SC != 1) )}
    connect CPT_esc_tasklink.PP_ESC_Tasklink_Mo_SyncS1_TRIGSRC -> CPT_esc_tasklink.RP_ESC_Tasklink_Mo_SyncS1_TRIGSRC
    connect CPT_esc_tasklink.PP_ESC_Tasklink_SyncIni_TRIGSRC -> CPT_esc_tasklink.RP_ESC_Tasklink_SyncIni_TRIGSRC
    connect CPT_esc_tasklink.PP_ESC_Tasklink_Mo_SyncFirst_TRIGSRC -> CPT_esc_tasklink.RP_ESC_Tasklink_Mo_SyncFirst_TRIGSRC
    connect CPT_esc_tasklink.PP_ESC_Tasklink_SyncS0H_TRIGSRC -> CPT_esc_stack.RP_ESC_Tasklink_SyncS0H_TRIGSRC, variation-point={short-label=VP_ASC_CPT_esc_tasklink_PP_ESC_Tasklink_SyncS0H_TRIGSRC_CPT_esc_stack_RP_ESC_Tasklink_SyncS0H_TRIGSRC, sw-syscond=( (( /RB/PT/Common/SwSystemconsts/Adjustables/ESC_SAMPLETICALCN_SC ==1) && ( /RB/PT/Common/SwSystemconsts/Adjustables/ESC_SYNCTASK_SC != 1)) )}
    connect CPT_SysC_Ladp.PP_SyC_stSub -> CPT_esc_tasklink.RP_SyC_stSub
    connect CPT_ESC_Ladp.PP_Eep_EnvRamInvld -> CPT_esc_tasklink.RP_Eep_EnvRamInvld, variation-point={short-label=VP_ASC_CPT_ESC_Ladp_PP_Eep_EnvRamInvld_CPT_esc_tasklink_RP_Eep_EnvRamInvld, sw-syscond=( ( /RB/PT/Common/SwSystemconsts/Adjustables/ESC_SWTSYNRTMEASMT_SC ==1) )&&( ( /RB/PT/Common/SwSystemconsts/Adjustables/ESC_SWTSYNRTMEASMT_SC ==1) )}
    connect CPT_esc_tasklink.PP_ESC_Tasklink_SyncS0_TRIGSRC -> CPT_esc_tasklink.RP_ESC_Tasklink_SyncS0_TRIGSRC
    connect CPT_esc_tasklink.PP_ESC_Tasklink_Mo_SyncIni_TRIGSRC -> CPT_esc_tasklink.RP_ESC_Tasklink_Mo_SyncIni_TRIGSRC
    connect CPT_esc_stack.PP_ESC_Stack -> CPT_esc_stack.RP_ESC_Stack, variation-point={short-label=VP_ASC_CPT_esc_stack_PP_ESC_Stack_CPT_esc_stack_RP_ESC_Stack, sw-syscond=( ( /RB/PT/Common/SwSystemconsts/Adjustables/ESC_SYNCTASK_SC != 1) )&&( ( /RB/PT/Common/SwSystemconsts/Adjustables/ESC_SYNCTASK_SC != 1) )}
    connect CPT_esc_tasklink.PP_ESC_Tasklink_SyncS0H_TRIGSRC -> CPT_esc_tasklink.RP_ESC_Tasklink_SyncS0H_TRIGSRC, variation-point={short-label=VP_ASC_CPT_esc_tasklink_PP_ESC_Tasklink_SyncS0H_TRIGSRC_CPT_esc_tasklink_RP_ESC_Tasklink_SyncS0H_TRIGSRC, sw-syscond=( ( /RB/PT/Common/SwSystemconsts/Adjustables/EPM_TDCDSTCLB_SC ==1) )}
    connect CPT_esc_tasklink.PP_ESC_Tasklink_SyncPre_TRIGSRC -> CPT_esc_tasklink.RP_ESC_Tasklink_SyncPre_TRIGSRC
    connect CPT_esc_tasklink.PP_ESC_Tasklink_SyncPre_TRIGSRC -> CPT_Epm_Ladp.RP_ESC_Tasklink_SyncPre_TRIGSRC
    connect CPT_esc_stack.PP_rbm_ESC_tiSampling -> CPT_ESC_Ladp.RP_rbm_ESC_tiSampling
    connect CPT_esc_tasklink.PP_ESC_Tasklink_SyncS1_TRIGSRC -> CPT_esc_tasklink.RP_ESC_Tasklink_SyncS1_TRIGSRC
    connect CPT_esc_tasklink.PP_ESC_Tasklink -> CPT_esc_tasklink.RP_ESC_Tasklink, variation-point={short-label=VP_ASC_CPT_esc_tasklink_PP_ESC_Tasklink_CPT_esc_tasklink_RP_ESC_Tasklink, sw-syscond=( ( /RB/PT/Common/SwSystemconsts/Adjustables/ESC_SWTSYNRTMEASMT_SC ==1) )&&( ( /RB/PT/Common/SwSystemconsts/Adjustables/ESC_SWTSYNRTMEASMT_SC ==1) )}
    connect CPT_esc_tasklink.PP_ESC_Tasklink_SyncIni_TRIGSRC -> CPT_esc_stack.RP_ESC_Tasklink_SyncIni_TRIGSRC, variation-point={short-label=VP_ASC_CPT_esc_tasklink_PP_ESC_Tasklink_SyncIni_TRIGSRC_CPT_esc_stack_RP_ESC_Tasklink_SyncIni_TRIGSRC, sw-syscond=( ( /RB/PT/Common/SwSystemconsts/Adjustables/ESC_SYNCTASK_SC != 1) )}
    connect CPT_esc_tasklink.PP_ESC_Tasklink_SyncIni_TRIGSRC -> CPT_Epm_Ladp.RP_ESC_Tasklink_SyncIni_TRIGSRC
    connect CPT_esc_tasklink.PP_ESC_Tasklink_SyncFirst_TRIGSRC -> CPT_Epm_Ladp.RP_ESC_Tasklink_SyncFirst_TRIGSRC
    connect CPT_esc_tasklink.PP_ESC_Tasklink_SyncPre_TRIGSRC -> CPT_SysC_Ladp.RP_ESC_Tasklink_SyncPre_TRIGSRC
    connect CPT_Epm_Ladp.PP_EpmSyn_phiInt -> CPT_esc_tasklink.RP_EpmSyn_phiInt, variation-point={short-label=VP_ASC_CPT_Epm_Ladp_PP_EpmSyn_phiInt_CPT_esc_tasklink_RP_EpmSyn_phiInt, sw-syscond=( ( /RB/PT/Common/SwSystemconsts/Adjustables/ESC_SWTSYNRTMEASMT_SC ==1) )&&( ( /RB/PT/Common/SwSystemconsts/Adjustables/ESC_SWTSYNRTMEASMT_SC ==1) )}
    connect CPT_Epm_Ladp.PP_Epm_phiCyl -> CPT_esc_tasklink.RP_Epm_phiCyl, variation-point={short-label=VP_ASC_CPT_Epm_Ladp_PP_Epm_phiCyl_CPT_esc_tasklink_RP_Epm_phiCyl, sw-syscond=( ( /RB/PT/Common/SwSystemconsts/Adjustables/ESC_SWTSYNRTMEASMT_SC ==1) )&&( (( /RB/PT/Common/SwSystemconsts/Adjustables/ESC_SWTSYNRTMEASMT_SC ==1) && ( /RB/PT/Common/SwSystemconsts/Adjustables/CMBTYP_SY == /RB/PT/esc_tasklink/SwSystemconsts/CMBTYP_DS )) )}
    connect CPT_esc_tasklink.PP_ESC_Tasklink_SyncPre_TRIGSRC -> CPT_esc_stack.RP_ESC_Tasklink_SyncPre_TRIGSRC, variation-point={short-label=VP_ASC_CPT_esc_tasklink_PP_ESC_Tasklink_SyncPre_TRIGSRC_CPT_esc_stack_RP_ESC_Tasklink_SyncPre_TRIGSRC, sw-syscond=( ( /RB/PT/Common/SwSystemconsts/Adjustables/ESC_SYNCTASK_SC != 1) )}
    connect CPT_esc_tasklink.PP_ESC_Tasklink_SyncFirst_TRIGSRC -> CPT_esc_tasklink.RP_ESC_Tasklink_SyncFirst_TRIGSRC
    connect CPT_esc_tasklink.PP_ESC_Tasklink_SyncS0_TRIGSRC -> CPT_Epm_Ladp.RP_ESC_Tasklink_SyncS0_TRIGSRC, variation-point={short-label=VP_ASC_CPT_esc_tasklink_PP_ESC_Tasklink_SyncS0_TRIGSRC_CPT_Epm_Ladp_RP_ESC_Tasklink_SyncS0_TRIGSRC, sw-syscond=( (( /RB/PT/Common/SwSystemconsts/Adjustables/ESC_SWTSYNRTMEASMT_SC ==1) && ( /RB/PT/Common/SwSystemconsts/Adjustables/CMBTYP_SY == /RB/PT/esc_tasklink/SwSystemconsts/CMBTYP_DS )) )}
    connect CPT_Epm_Ladp.PP_EpmCrS_tiSeg -> CPT_esc_stack.RP_EpmCrS_tiSeg, variation-point={short-label=VP_ASC_CPT_Epm_Ladp_PP_EpmCrS_tiSeg_CPT_esc_stack_RP_EpmCrS_tiSeg, sw-syscond=( ( /RB/PT/Common/SwSystemconsts/Adjustables/ESC_SYNCTASK_SC != 1) )&&( ( /RB/PT/Common/SwSystemconsts/Adjustables/ESC_SYNCTASK_SC != 1) )}
    connect CPT_esc_tasklink.PP_ESC_Tasklink_SyncS0_TRIGSRC -> CPT_esc_stack.RP_ESC_Tasklink_SyncS0_TRIGSRC, variation-point={short-label=VP_ASC_CPT_esc_tasklink_PP_ESC_Tasklink_SyncS0_TRIGSRC_CPT_esc_stack_RP_ESC_Tasklink_SyncS0_TRIGSRC, sw-syscond=( ( /RB/PT/Common/SwSystemconsts/Adjustables/ESC_SYNCTASK_SC != 1) )}
    connect CPT_ESC_EveCfg.PP_ESC_EveCfg -> CPT_ESC_EveCfg.RP_ESC_EveCfg
    connect CPT_ESC_EveCfg.PP_stMinSyncAgEveGen -> CPT_ESC_OsTskActvnHndlr.RP_stMinSyncAgEveGen, variation-point={short-label=VP_AssemblySwConnector, sw-syscond=( /RB/PT/Common/SwSystemconsts/Adjustables/ESC_NRAGEVEWCYC_SC !=0&& /RB/PT/Common/SwSystemconsts/Adjustables/ESC_NRTSKAGEVE_SC !=0 )}
    connect CPT_ESC_HwIntrptEveGen.PP_ESC_HwIntrptEveGen -> CPT_ESC_EveCfg.RP_ESC_HwIntrptEveGen
    connect CPT_ESC_OsTskActvnHndlr.PP_ESC_OsTskActvnHndlr -> CPT_ESC_EveCfg.RP_ESC_OsTskActvnHndlr
    connect CPT_ESC_OsTskActvnHndlr.PP_ESC_OsTskActvnHndlr -> CPT_ESC_OsTskActvnHndlr.RP_ESC_OsTskActvnHndlr
    connect CPT_ESC_OsTskActvnHndlr.PP_ESC_OsTskActvnHndlr_AgEveE0_TRIGSRC -> CPT_ESC_OsTskActvnHndlr.RP_ESC_OsTskActvnHndlr_AgEveE0_TRIGSRC, variation-point={short-label=VP_AssemblySwConnector, sw-syscond=( /RB/PT/Common/SwSystemconsts/Adjustables/ESC_NRAGEVEWCYC_SC !=0&& /RB/PT/Common/SwSystemconsts/Adjustables/ESC_NRTSKAGEVE_SC !=0 )&&( /RB/PT/Common/SwSystemconsts/Adjustables/ESC_NRAGEVEWCYC_SC !=0&& /RB/PT/Common/SwSystemconsts/Adjustables/ESC_NRTSKAGEVE_SC !=0 )}
    connect CPT_ESC_OsTskActvnHndlr.PP_ESC_OsTskActvnHndlr_AgEveE1_TRIGSRC -> CPT_ESC_OsTskActvnHndlr.RP_ESC_OsTskActvnHndlr_AgEveE1_TRIGSRC, variation-point={short-label=VP_AssemblySwConnector, sw-syscond=( /RB/PT/Common/SwSystemconsts/Adjustables/ESC_NRAGEVEWCYC_SC !=0&& /RB/PT/Common/SwSystemconsts/Adjustables/ESC_NRTSKAGEVE_SC >=2 )&&( /RB/PT/Common/SwSystemconsts/Adjustables/ESC_NRAGEVEWCYC_SC !=0&& /RB/PT/Common/SwSystemconsts/Adjustables/ESC_NRTSKAGEVE_SC >=2 )}
    connect CPT_Epm_Ladp.PP_EpmCaS_numSegSerLst -> CPT_ESC_OsTskActvnHndlr.RP_EpmCaS_numSegSerLst, variation-point={short-label=VP_AssemblySwConnector, sw-syscond=( /RB/PT/Common/SwSystemconsts/Adjustables/ESC_SELNCAMSFTTSKACTVN_SC ==1&& /RB/PT/Common/SwSystemconsts/Adjustables/ESC_SELNCAMSFTSYNCN_SC !=255 )}
    connect CPT_Epm_Ladp.PP_Epm_nEng -> CPT_ESC_OsTskActvnHndlr.RP_Epm_nEng, variation-point={short-label=VP_AssemblySwConnector, sw-syscond=( ((( /RB/PT/Common/SwSystemconsts/Adjustables/ESC_SELNCAMSFTTSKACTVN_SC ==1) && ( /RB/PT/Common/SwSystemconsts/Adjustables/ESC_SELNCAMSFTSYNCN_SC != 255))||( /RB/PT/Common/SwSystemconsts/Adjustables/ESC_NRTSKAGEVE_SC !=0)) )&&( /RB/PT/Common/SwSystemconsts/Adjustables/ESC_SELNCAMSFTTSKACTVN_SC ==1&& /RB/PT/Common/SwSystemconsts/Adjustables/ESC_SELNCAMSFTSYNCN_SC !=255 )}
    connect CPT_Epm_Ladp.PP_Epm_nEng -> CPT_ESC_EveCfg.RP_Epm_nEng, variation-point={short-label=VP_AssemblySwConnector, sw-syscond=( ((( /RB/PT/Common/SwSystemconsts/Adjustables/ESC_SELNCAMSFTTSKACTVN_SC ==1) && ( /RB/PT/Common/SwSystemconsts/Adjustables/ESC_SELNCAMSFTSYNCN_SC != 255))||( /RB/PT/Common/SwSystemconsts/Adjustables/ESC_NRTSKAGEVE_SC !=0)) )}
    connect CPT_Epm_Ladp.PP_EpmSeq_numInt -> CPT_ESC_EveCfg.RP_EpmSeq_numInt
    connect CPT_Epm_Ladp.PP_Epm_stSync -> CPT_ESC_EveCfg.RP_Epm_stSync, variation-point={short-label=VP_AssemblySwConnector, sw-syscond=( (( /RB/PT/Common/SwSystemconsts/Adjustables/ESC_SELNCAMSFTTSKACTVN_SC ==1)||( /RB/PT/Common/SwSystemconsts/Adjustables/ESC_NRTSKAGEVE_SC !=0)) )}
    connect CPT_Epm_Ladp.PP_EpmSyn_phiInt -> CPT_ESC_EveCfg.RP_EpmSyn_phiInt, variation-point={short-label=VP_AssemblySwConnector, sw-syscond=( /RB/PT/Common/SwSystemconsts/Adjustables/ESC_SWTSYNRTMEASMT_SC ==1|| /RB/PT/Common/SwSystemconsts/Adjustables/ESC_NRTSKAGEVE_SC !=0 )}
    connect CPT_esc_tasklink.PP_ESC_Tasklink_SyncPre_TRIGSRC -> CPT_ESC_EveCfg.RP_ESC_Tasklink_SyncPre_TRIGSRC
    connect CPT_esc_tasklink.PP_ESC_Tasklink_SyncIni_TRIGSRC -> CPT_ESC_EveCfg.RP_ESC_Tasklink_SyncIni_TRIGSRC
    connect CPT_esc_tasklink.PP_ESC_Tasklink_SyncIni_TRIGSRC -> CPT_ESC_OsTskActvnHndlr.RP_ESC_Tasklink_SyncIni_TRIGSRC
    connect CPT_esc_stack.PP_ESC_tiAgEveE0TskStrt -> CPT_ESC_OsTskActvnHndlr.RP_tiAgEveE0TskStrt, mapping=PIM_IF_tiAgEveE0TskStrt_IF_ESC_tiAgEveE0TskStrt, variation-point={short-label=VP_AssemblySwConnector, sw-syscond=( (( /RB/PT/Common/SwSystemconsts/Adjustables/ESC_NRAGEVEWCYC_SC !=0) && ( /RB/PT/Common/SwSystemconsts/Adjustables/ESC_NRTSKAGEVE_SC !=0)) )&&( /RB/PT/Common/SwSystemconsts/Adjustables/ESC_NRAGEVEWCYC_SC !=0&& /RB/PT/Common/SwSystemconsts/Adjustables/ESC_NRTSKAGEVE_SC !=0 )}
    connect CPT_esc_stack.PP_ESC_tiAgEveE1TskStrt -> CPT_ESC_OsTskActvnHndlr.RP_tiAgEveE1TskStrt, mapping=PIM_IF_tiAgEveE1TskStrt_IF_ESC_tiAgEveE1TskStrt, variation-point={short-label=VP_AssemblySwConnector, sw-syscond=( (( /RB/PT/Common/SwSystemconsts/Adjustables/ESC_NRAGEVEWCYC_SC !=0) && ( /RB/PT/Common/SwSystemconsts/Adjustables/ESC_NRTSKAGEVE_SC >=2)) )&&( /RB/PT/Common/SwSystemconsts/Adjustables/ESC_NRAGEVEWCYC_SC !=0&& /RB/PT/Common/SwSystemconsts/Adjustables/ESC_NRTSKAGEVE_SC >=2 )}
    connect CPT_esc_stack.PP_ESC_agEveE1TskStrt -> CPT_ESC_OsTskActvnHndlr.RP_agEveE1TskStrt, mapping=PIM_IF_agEveE1TskStrt_IF_ESC_agEveE1TskStrt, variation-point={short-label=VP_AssemblySwConnector, sw-syscond=( (( /RB/PT/Common/SwSystemconsts/Adjustables/ESC_NRAGEVEWCYC_SC !=0) && ( /RB/PT/Common/SwSystemconsts/Adjustables/ESC_NRTSKAGEVE_SC >=2)) )&&( /RB/PT/Common/SwSystemconsts/Adjustables/ESC_NRAGEVEWCYC_SC !=0&& /RB/PT/Common/SwSystemconsts/Adjustables/ESC_NRTSKAGEVE_SC >=2 )}
    connect CPT_esc_stack.PP_ESC_agEveE0TskStrt -> CPT_ESC_OsTskActvnHndlr.RP_agEveE0TskStrt, mapping=PIM_IF_agEveE0TskStrt_IF_ESC_agEveE0TskStrt, variation-point={short-label=VP_AssemblySwConnector, sw-syscond=( (( /RB/PT/Common/SwSystemconsts/Adjustables/ESC_NRAGEVEWCYC_SC !=0) && ( /RB/PT/Common/SwSystemconsts/Adjustables/ESC_NRTSKAGEVE_SC !=0)) )&&( /RB/PT/Common/SwSystemconsts/Adjustables/ESC_NRAGEVEWCYC_SC !=0&& /RB/PT/Common/SwSystemconsts/Adjustables/ESC_NRTSKAGEVE_SC !=0 )}
    connect CPT_esc_stack.PP_ESC_idCurrRunngAgEveTsk -> CPT_ESC_OsTskActvnHndlr.RP_idCurrRunngAgEveTsk, mapping=PIM_IF_idCurrRunngAgEveTsk_IF_ESC_idCurrRunngAgEveTsk, variation-point={short-label=VP_AssemblySwConnector, sw-syscond=( (( /RB/PT/Common/SwSystemconsts/Adjustables/ESC_NRAGEVEWCYC_SC !=0) && ( /RB/PT/Common/SwSystemconsts/Adjustables/ESC_NRTSKAGEVE_SC !=0)) )&&( /RB/PT/Common/SwSystemconsts/Adjustables/ESC_NRAGEVEWCYC_SC !=0&& /RB/PT/Common/SwSystemconsts/Adjustables/ESC_NRTSKAGEVE_SC !=0 )}
    connect CPT_esc_stack.PP_ESC_agEveE2TskStrt -> CPT_ESC_OsTskActvnHndlr.RP_agEveE2TskStrt, mapping=PIM_IF_agEveE2TskStrt_IF_ESC_agEveE2TskStrt, variation-point={short-label=VP_AssemblySwConnector, sw-syscond=( (( /RB/PT/Common/SwSystemconsts/Adjustables/ESC_NRAGEVEWCYC_SC !=0) && ( /RB/PT/Common/SwSystemconsts/Adjustables/ESC_NRTSKAGEVE_SC ==3)) )&&( /RB/PT/Common/SwSystemconsts/Adjustables/ESC_NRAGEVEWCYC_SC !=0&& /RB/PT/Common/SwSystemconsts/Adjustables/ESC_NRTSKAGEVE_SC ==3 )}
    connect CPT_esc_stack.PP_ESC_tiAgEveE2TskStrt -> CPT_ESC_OsTskActvnHndlr.RP_tiAgEveE2TskStrt, mapping=PIM_IF_tiAgEveE2TskStrt_IF_ESC_tiAgEveE2TskStrt, variation-point={short-label=VP_AssemblySwConnector, sw-syscond=( (( /RB/PT/Common/SwSystemconsts/Adjustables/ESC_NRAGEVEWCYC_SC !=0) && ( /RB/PT/Common/SwSystemconsts/Adjustables/ESC_NRTSKAGEVE_SC ==3)) )&&( /RB/PT/Common/SwSystemconsts/Adjustables/ESC_NRAGEVEWCYC_SC !=0&& /RB/PT/Common/SwSystemconsts/Adjustables/ESC_NRTSKAGEVE_SC ==3 )}
    connect CPT_ESC_OsTskActvnHndlr.PP_ESC_OsTskActvnHndlr_AgEveE2_TRIGSRC -> CPT_ESC_OsTskActvnHndlr.RP_ESC_OsTskActvnHndlr_AgEveE2_TRIGSRC, variation-point={short-label=VP_AssemblySwConnector, sw-syscond=( /RB/PT/Common/SwSystemconsts/Adjustables/ESC_NRAGEVEWCYC_SC !=0&& /RB/PT/Common/SwSystemconsts/Adjustables/ESC_NRTSKAGEVE_SC ==3 )&&( /RB/PT/Common/SwSystemconsts/Adjustables/ESC_NRAGEVEWCYC_SC !=0&& /RB/PT/Common/SwSystemconsts/Adjustables/ESC_NRTSKAGEVE_SC ==3 )}
    delegate CPT_Cdd_Composition.VeLBPR_p_BaroPress <-> outer port VeLBPR_p_BaroPress
    delegate CPT_Cdd_Composition.GetEPSR_i_BDCC_FgSeqAtAng <-> outer port GetEPSR_i_BDCC_FgSeqAtAng
    delegate CPT_Cdd_Composition.VeCAMR_phi_Exh1CCLPosn <-> outer port VeCAMR_phi_Exh1CCLPosn
    delegate CPT_Cdd_Composition.VeCAMR_phi_Intk1CCLPosn <-> outer port VeCAMR_phi_Intk1CCLPosn
    delegate CPT_Cdd_Composition.VeEPSR_b_EngRvsRotActv <-> outer port VeEPSR_b_EngRvsRotActv
    delegate CPT_Cdd_Composition.VeRPMR_n_EngSpdFastRate <-> outer port VeRPMR_n_EngSpdFastRate
    delegate CPT_Cdd_Composition.VeEPSR_t_MisfWin1_EngRotPrd <-> outer port VeEPSR_t_MisfWin1_EngRotPrd
    delegate CPT_Cdd_Composition.VeRPMR_dn_EngAcceltn <-> outer port VeRPMR_dn_EngAcceltn
    delegate CPT_Cdd_Composition.VeCRKR_b_CrksftUnlckdInRun <-> outer port VeCRKR_b_CrksftUnlckdInRun
    delegate CPT_Cdd_Composition.GetEPSR_i_CylInFgSeq <-> outer port GetEPSR_i_CylInFgSeq
    delegate CPT_Cdd_Composition.GetEPSR_i_TDCP_CylAtAng <-> outer port GetEPSR_i_TDCP_CylAtAng
    delegate CPT_Cdd_Composition.VeRPMR_dn_EngAcceltnNotFiltd <-> outer port VeRPMR_dn_EngAcceltnNotFiltd
    delegate CPT_Cdd_Composition.GetEPSR_phi_BDCE_AngOfCyl <-> outer port GetEPSR_phi_BDCE_AngOfCyl
    delegate CPT_Cdd_Composition.VeVVTR_b_Intk1CamDrvnToLockPin <-> outer port VeVVTR_b_Intk1CamDrvnToLockPin
    delegate CPT_Cdd_Composition.VeEPSR_Cnt_TDCP_Eve <-> outer port VeEPSR_Cnt_TDCP_Eve
    delegate CPT_Cdd_Composition.VeCRKR_t_EPP_Prd <-> outer port VeCRKR_t_EPP_Prd
    delegate CPT_Cdd_Composition.VeEPSR_Cnt_TDCI_Eve <-> outer port VeEPSR_Cnt_TDCI_Eve
    delegate CPT_Cdd_Composition.GetEPSR_phi_BDCC_AngOfCyl <-> outer port GetEPSR_phi_BDCC_AngOfCyl
    delegate CPT_Cdd_Composition.GetCRKR_t_EPP_Prd <-> outer port GetCRKR_t_EPP_Prd
    delegate CPT_Cdd_Composition.GetEPSR_i_BDCE_FgSeqAtAng <-> outer port GetEPSR_i_BDCE_FgSeqAtAng
    delegate CPT_Cdd_Composition.VeCAMR_phi_Exh1CCLAdjdLkpn <-> outer port VeCAMR_phi_Exh1CCLAdjdLkpn
    delegate CPT_Cdd_Composition.GetCRKR_Cnt_CrksftToothCnt <-> outer port GetCRKR_Cnt_CrksftToothCnt
    delegate CPT_Cdd_Composition.VeRPMR_n_EngSpdResl1 <-> outer port VeRPMR_n_EngSpdResl1
    delegate CPT_Cdd_Composition.VeEPSR_t_EngPwrPlsPrd <-> outer port VeEPSR_t_EngPwrPlsPrd
    delegate CPT_Cdd_Composition.GetCRKR_b_CrksftFltPrsnt <-> outer port GetCRKR_b_CrksftFltPrsnt
    delegate CPT_Cdd_Composition.VeEPSR_Cnt_BDCE_Eve <-> outer port VeEPSR_Cnt_BDCE_Eve
    delegate CPT_Cdd_Composition.GetCRKR_b_CrksftIntmLimpIn <-> outer port GetCRKR_b_CrksftIntmLimpIn
    delegate CPT_Cdd_Composition.VeEPSR_Cnt_FastPahTrqCalcn_Eve <-> outer port VeEPSR_Cnt_FastPahTrqCalcn_Eve
    delegate CPT_Cdd_Composition.VeEPSR_Cnt_EngStopdEve <-> outer port VeEPSR_Cnt_EngStopdEve
    delegate CPT_Cdd_Composition.VeCAMR_b_IsExh1CamLockd <-> outer port VeCAMR_b_IsExh1CamLockd
    delegate CPT_Cdd_Composition.VeEPSR_Cnt_TDCP_1_Eve <-> outer port VeEPSR_Cnt_TDCP_1_Eve
    delegate CPT_Cdd_Composition.GetEPSR_i_FgSeqAtAng <-> outer port GetEPSR_i_FgSeqAtAng
    delegate CPT_Cdd_Composition.VeEPSR_b_ESS_SyncStopNotAllwd <-> outer port VeEPSR_b_ESS_SyncStopNotAllwd
    delegate CPT_Cdd_Composition.GetEPSR_b_EngPosnIsFullySyncd <-> outer port GetEPSR_b_EngPosnIsFullySyncd
    delegate CPT_Cdd_Composition.GetEPSR_i_NextCyl <-> outer port GetEPSR_i_NextCyl
    delegate CPT_Cdd_Composition.VeEPSR_Cnt_AirPrdtnFuCalcn_Eve <-> outer port VeEPSR_Cnt_AirPrdtnFuCalcn_Eve
    delegate CPT_Cdd_Composition.GetCAMR_b_IsExh1CamLockd <-> outer port GetCAMR_b_IsExh1CamLockd
    delegate CPT_Cdd_Composition.WrCamCrksftDifIntk1 <-> outer port WrCamCrksftDifIntk1
    delegate CPT_Cdd_Composition.GetEPSR_phi_FastPahTrqCalcn_AngOfCyl <-> outer port GetEPSR_phi_FastPahTrqCalcn_AngOfCyl
    delegate CPT_Cdd_Composition.WrCamCrksftDifExh1 <-> outer port WrCamCrksftDifExh1
    delegate CPT_Cdd_Composition.VeEPSR_Cnt_SyncnEve <-> outer port VeEPSR_Cnt_SyncnEve
    delegate CPT_Cdd_Composition.CamCrksftDifCmnCS <-> outer port CamCrksftDifCmnCS
    delegate CPT_Cdd_Composition.GetEPSR_i_PrevInFgSeq <-> outer port GetEPSR_i_PrevInFgSeq
    delegate CPT_Cdd_Composition.VeCAMR_b_Intk1CamInLimpIn <-> outer port VeCAMR_b_Intk1CamInLimpIn
    delegate CPT_Cdd_Composition.GetEPSR_t_EngPwrPlsPrd <-> outer port GetEPSR_t_EngPwrPlsPrd
    delegate CPT_Cdd_Composition.VeCRKR_b_IsCrksftLockd <-> outer port VeCRKR_b_IsCrksftLockd
    delegate CPT_Cdd_Composition.GetEPSR_i_TDCP_FgSeqAtAng <-> outer port GetEPSR_i_TDCP_FgSeqAtAng
    delegate CPT_Cdd_Composition.VeEPSR_Cnt_FwdRotDtctdEve <-> outer port VeEPSR_Cnt_FwdRotDtctdEve
    delegate CPT_Cdd_Composition.GetEPSR_i_NextInFgSeq <-> outer port GetEPSR_i_NextInFgSeq
    delegate CPT_Cdd_Composition.VeEPSR_t_DynFuCtrlWin_EngRotPrd <-> outer port VeEPSR_t_DynFuCtrlWin_EngRotPrd
    delegate CPT_Cdd_Composition.GetCAMR_b_Exh1CamInLimpIn <-> outer port GetCAMR_b_Exh1CamInLimpIn
    delegate CPT_Cdd_Composition.VeEPSR_Cnt_MidEngPwrPlsEve <-> outer port VeEPSR_Cnt_MidEngPwrPlsEve
    delegate CPT_Cdd_Composition.VeRPMR_n_EngSpd <-> outer port VeRPMR_n_EngSpd
    delegate CPT_Cdd_Composition.VeCAMR_phi_Intk1CCLAdjdLkpn <-> outer port VeCAMR_phi_Intk1CCLAdjdLkpn
    delegate CPT_Cdd_Composition.GetCAMR_i_Exh1CamEdgeIdx <-> outer port GetCAMR_i_Exh1CamEdgeIdx
    delegate CPT_Cdd_Composition.VeEPSR_Cnt_BDCC_Eve <-> outer port VeEPSR_Cnt_BDCC_Eve
    delegate CPT_Cdd_Composition.KeCRKR_b_BidrnlPosnSnsrEquid <-> outer port KeCRKR_b_BidrnlPosnSnsrEquid
    delegate CPT_Cdd_Composition.VeCAMR_b_IsIntk1CamLockd <-> outer port VeCAMR_b_IsIntk1CamLockd
    delegate CPT_Cdd_Composition.VeVVTR_b_Exh1CamDrvnToLockPin <-> outer port VeVVTR_b_Exh1CamDrvnToLockPin
    delegate CPT_Cdd_Composition.GetEPSR_phi_EngPosn <-> outer port GetEPSR_phi_EngPosn
    delegate CPT_Cdd_Composition.VeEPSR_t_MisfWin3_EngRotPrd <-> outer port VeEPSR_t_MisfWin3_EngRotPrd
    delegate CPT_Cdd_Composition.GetCAMR_b_IsIntk1CamLockd <-> outer port GetCAMR_b_IsIntk1CamLockd
    delegate CPT_Cdd_Composition.GetEPSR_b_EngSynchronousEveEnbld <-> outer port GetEPSR_b_EngSynchronousEveEnbld
    delegate CPT_Cdd_Composition.VeEPSR_t_MisfWin2_EngRotPrd <-> outer port VeEPSR_t_MisfWin2_EngRotPrd
    delegate CPT_Cdd_Composition.VeCAMR_b_Exh1CamInLimpIn <-> outer port VeCAMR_b_Exh1CamInLimpIn
    delegate CPT_Cdd_Composition.VeEPSR_b_EngPosnIsFullySyncd <-> outer port VeEPSR_b_EngPosnIsFullySyncd
    delegate CPT_Cdd_Composition.GetCRKR_b_IsCrksftMtnDtctd <-> outer port GetCRKR_b_IsCrksftMtnDtctd
    delegate CPT_Cdd_Composition.GetCRKR_b_IsCrksftFwdRotDtctd <-> outer port GetCRKR_b_IsCrksftFwdRotDtctd
    delegate CPT_Cdd_Composition.GetLLSR_t_IgnMaxDwell <-> outer port GetLLSR_t_IgnMaxDwell
    delegate CPT_Cdd_Composition.VeLTAR_b_EngAtIdle <-> outer port VeLTAR_b_EngAtIdle
    delegate CPT_Cdd_Composition.SetLLFR_InjAngDelt <-> outer port SetLLFR_InjAngDelt
    delegate CPT_Cdd_Composition.GetLLFR_b_FuDlvdCylDI <-> outer port GetLLFR_b_FuDlvdCylDI
    delegate CPT_Cdd_Composition.SetLLFR_ImdtDsblAllInjr <-> outer port SetLLFR_ImdtDsblAllInjr
    delegate CPT_Cdd_Composition.SetLLFR_ImdtEnblInjrDI <-> outer port SetLLFR_ImdtEnblInjrDI
    delegate CPT_Cdd_Composition.GetLLFR_b_InjrConjRstrDoNotApply <-> outer port GetLLFR_b_InjrConjRstrDoNotApply
    delegate CPT_Cdd_Composition.GetLLFR_b_InjrConjRstrApply <-> outer port GetLLFR_b_InjrConjRstrApply
    delegate CPT_Cdd_Composition.SetLLFR_InjAngEndCfg <-> outer port SetLLFR_InjAngEndCfg
    delegate CPT_Cdd_Composition.SetLLFR_InjrDsblDI <-> outer port SetLLFR_InjrDsblDI
    delegate CPT_Cdd_Composition.VeSSCR_t_EngRunngTmr <-> outer port VeSSCR_t_EngRunngTmr
    delegate CPT_Cdd_Composition.SetLLFR_InjrDsbl <-> outer port SetLLFR_InjrDsbl
    delegate CPT_Cdd_Composition.SetLLFR_InjrAllw0PlsWidthCmd <-> outer port SetLLFR_InjrAllw0PlsWidthCmd
    delegate CPT_Cdd_Composition.GetLLFR_phi_InjAngDI <-> outer port GetLLFR_phi_InjAngDI
    delegate CPT_Cdd_Composition.SetLLFR_InjrDeltLimCfg <-> outer port SetLLFR_InjrDeltLimCfg
    delegate CPT_Cdd_Composition.SetLLFR_InjrMinAng <-> outer port SetLLFR_InjrMinAng
    delegate CPT_Cdd_Composition.GetLLFR_b_InjrDsbld <-> outer port GetLLFR_b_InjrDsbld
    delegate CPT_Cdd_Composition.GetLLFR_b_InjrEnbldDI <-> outer port GetLLFR_b_InjrEnbldDI
    delegate CPT_Cdd_Composition.VeIATR_T_IAT <-> outer port VeIATR_T_IAT
    delegate CPT_Cdd_Composition.VeTAFR_Pct_FanSpdCmd <-> outer port VeTAFR_Pct_FanSpdCmd
    delegate CPT_Cdd_Composition.VeHCTR_T_ECT_ShtDwn <-> outer port VeHCTR_T_ECT_ShtDwn
    delegate CPT_Cdd_Composition.VeFPCR_b_IBM_DesPressInRng <-> outer port VeFPCR_b_IBM_DesPressInRng
    delegate CPT_Cdd_Composition.VeINJR_t_EngRunngTmr <-> outer port VeINJR_t_EngRunngTmr
    delegate CPT_Cdd_Composition.VeIBMR_p_FuRailPresSetPt <-> outer port VeIBMR_p_FuRailPresSetPt
    delegate CPT_Cdd_Composition.VeINJR_b_CatHeatgReq <-> outer port VeINJR_b_CatHeatgReq
    delegate CPT_Cdd_Composition.SetLLSR_IgnMultiStrike <-> outer port SetLLSR_IgnMultiStrike
    delegate CPT_Cdd_Composition.SetLLFR_InjAng <-> outer port SetLLFR_InjAng
    delegate CPT_Cdd_Composition.VaINJR_p_Pres <-> outer port VaINJR_p_Pres
    delegate CPT_Cdd_Composition.GetLLFR_b_InjAngEndCfgDI <-> outer port GetLLFR_b_InjAngEndCfgDI
    delegate CPT_Cdd_Composition.SetLLFR_InjrPlsWidth <-> outer port SetLLFR_InjrPlsWidth
    delegate CPT_Cdd_Composition.VeHCTR_T_ECT <-> outer port VeHCTR_T_ECT
    delegate CPT_Cdd_Composition.GetLLFR_phi_InjrHardMinAng <-> outer port GetLLFR_phi_InjrHardMinAng
    delegate CPT_Cdd_Composition.VeFENR_y_StsReg <-> outer port VeFENR_y_StsReg
    delegate CPT_Cdd_Composition.SetLLFR_ImdtEnblInjr <-> outer port SetLLFR_ImdtEnblInjr
    delegate CPT_Cdd_Composition.GetLLFR_b_InjrEnbld <-> outer port GetLLFR_b_InjrEnbld
    delegate CPT_Cdd_Composition.SetLLFR_InjAngEndCfgDI <-> outer port SetLLFR_InjAngEndCfgDI
    delegate CPT_Cdd_Composition.GetVCMR_b_VVA_ActWrkgModCod <-> outer port GetVCMR_b_VVA_ActWrkgModCod
    delegate CPT_Cdd_Composition.SetLLFR_InjrPlsSeprnDly <-> outer port SetLLFR_InjrPlsSeprnDly
    delegate CPT_Cdd_Composition.SetLLFR_InjrMaxAngDI <-> outer port SetLLFR_InjrMaxAngDI
    delegate CPT_Cdd_Composition.VeFUTR_b_FuTempValVld <-> outer port VeFUTR_b_FuTempValVld
    delegate CPT_Cdd_Composition.VeINJR_e_DI_NrOfPulsesDes <-> outer port VeINJR_e_DI_NrOfPulsesDes
    delegate CPT_Cdd_Composition.GetLLFR_b_FuDlvdCyl <-> outer port GetLLFR_b_FuDlvdCyl
    delegate CPT_Cdd_Composition.GetLLFR_phi_InjrHardMaxAng <-> outer port GetLLFR_phi_InjrHardMaxAng
    delegate CPT_Cdd_Composition.VeINJR_dm_DI_InjrMassFlowFiltd <-> outer port VeINJR_dm_DI_InjrMassFlowFiltd
    delegate CPT_Cdd_Composition.GetLLFR_Cnt_InjrMaxNumPulses <-> outer port GetLLFR_Cnt_InjrMaxNumPulses
    delegate CPT_Cdd_Composition.VeATSR_T_AmbTemp <-> outer port VeATSR_T_AmbTemp
    delegate CPT_Cdd_Composition.GetLLFR_phi_InjAng <-> outer port GetLLFR_phi_InjAng
    delegate CPT_Cdd_Composition.GetLLFR_b_AreAnyInjrEnbld <-> outer port GetLLFR_b_AreAnyInjrEnbld
    delegate CPT_Cdd_Composition.VeINJR_K_2ndPlsFrac <-> outer port VeINJR_K_2ndPlsFrac
    delegate CPT_Cdd_Composition.GetLLFR_t_InjrPlsWidthDlvdDI <-> outer port GetLLFR_t_InjrPlsWidthDlvdDI
    delegate CPT_Cdd_Composition.GetLLFR_b_InjrEnblReqdForCylDI <-> outer port GetLLFR_b_InjrEnblReqdForCylDI
    delegate CPT_Cdd_Composition.SetLLFR_InjrPlsOffs <-> outer port SetLLFR_InjrPlsOffs
    delegate CPT_Cdd_Composition.SetLLFR_InjrMinAngDI <-> outer port SetLLFR_InjrMinAngDI
    delegate CPT_Cdd_Composition.VeINJR_b_EngStrt <-> outer port VeINJR_b_EngStrt
    delegate CPT_Cdd_Composition.VeIBMR_b_CVO_RailSpReqEnbl <-> outer port VeIBMR_b_CVO_RailSpReqEnbl
    delegate CPT_Cdd_Composition.GetLLFR_b_AreAnyInjrOn <-> outer port GetLLFR_b_AreAnyInjrOn
    delegate CPT_Cdd_Composition.SetLLSR_IgnAng <-> outer port SetLLSR_IgnAng
    delegate CPT_Cdd_Composition.GetLLFR_phi_InjrHardMaxAngDI <-> outer port GetLLFR_phi_InjrHardMaxAngDI
    delegate CPT_Cdd_Composition.SetLLFR_InjrMinPlsWidth <-> outer port SetLLFR_InjrMinPlsWidth
    delegate CPT_Cdd_Composition.GetLLFR_b_AllInjrEnbld <-> outer port GetLLFR_b_AllInjrEnbld
    delegate CPT_Cdd_Composition.VeFPCR_p_FuRailPres <-> outer port VeFPCR_p_FuRailPres
    delegate CPT_Cdd_Composition.VeFUTR_T_Temp <-> outer port VeFUTR_T_Temp
    delegate CPT_Cdd_Composition.VeVVTR_phi_IntkVlvClsAngBnk1 <-> outer port VeVVTR_phi_IntkVlvClsAngBnk1
    delegate CPT_Cdd_Composition.VeFUTR_T_DI_Temp <-> outer port VeFUTR_T_DI_Temp
    delegate CPT_Cdd_Composition.GetLLFR_phi_InjrHardMinAngDI <-> outer port GetLLFR_phi_InjrHardMinAngDI
    delegate CPT_Cdd_Composition.VeINJR_K_1stPlsFrac <-> outer port VeINJR_K_1stPlsFrac
    delegate CPT_Cdd_Composition.SetLLFR_InjrMinTiBtwnPls <-> outer port SetLLFR_InjrMinTiBtwnPls
    delegate CPT_Cdd_Composition.GetLLFR_b_InjrEnblReqdForCyl <-> outer port GetLLFR_b_InjrEnblReqdForCyl
    delegate CPT_Cdd_Composition.VaFUMR_m_DI_InjrFuTar <-> outer port VaFUMR_m_DI_InjrFuTar
    delegate CPT_Cdd_Composition.SetLLFR_InjrSubPlsCmd <-> outer port SetLLFR_InjrSubPlsCmd
    delegate CPT_Cdd_Composition.ActuateLLFR_InjrAsyncPls <-> outer port ActuateLLFR_InjrAsyncPls
    delegate CPT_Cdd_Composition.SetLLSR_IgnDwell <-> outer port SetLLSR_IgnDwell
    delegate CPT_Cdd_Composition.SetLLFR_InjrMaxAng <-> outer port SetLLFR_InjrMaxAng
    delegate CPT_Cdd_Composition.GetLLFR_t_InjrPlsWidthDlvd <-> outer port GetLLFR_t_InjrPlsWidthDlvd
    delegate CPT_Cdd_Composition.VeINJR_i_EngRstrt <-> outer port VeINJR_i_EngRstrt
    delegate CPT_Cdd_Composition.SetLLFR_InjAngDI <-> outer port SetLLFR_InjAngDI
    delegate CPT_Cdd_Composition.SetLLFR_InjrPlsMd <-> outer port SetLLFR_InjrPlsMd
    delegate CPT_Cdd_Composition.VeINJR_b_EndOfEngStrt <-> outer port VeINJR_b_EndOfEngStrt
    delegate CPT_Cdd_Composition.GetLLFR_b_InjAngEndCfg <-> outer port GetLLFR_b_InjAngEndCfg
    delegate CPT_IoSigAdc_SwSStellantisCmpstn.VeADCR_U_ThrIntkPresSns <-> outer port VeADCR_U_ThrIntkPresSns
    delegate CPT_IoSigAdc_SwSStellantisCmpstn.PedlValSnsr1 <-> outer port PedlValSnsr1
    delegate CPT_IoSigAdc_SwSStellantisCmpstn.VeADCR_U_PdlValSnsr2Aux <-> outer port VeADCR_U_PdlValSnsr2Aux
    delegate CPT_IoSigAdc_SwSStellantisCmpstn.VeADCR_U_WgPosn1 <-> outer port VeADCR_U_WgPosn1
    delegate CPT_IoSigAdc_SwSStellantisCmpstn.VeADCR_U_OilShutOffValveFb <-> outer port VeADCR_U_OilShutOffValveFb
    delegate CPT_IoSigAdc_SwSStellantisCmpstn.VeADCR_U_BrkPdlPosnSnsr <-> outer port VeADCR_U_BrkPdlPosnSnsr
    delegate CPT_IoSigAdc_SwSStellantisCmpstn.OilPSnsr <-> outer port OilPSnsr
    delegate CPT_IoSigAdc_SwSStellantisCmpstn.VeADCR_U_EngSwtBatt <-> outer port VeADCR_U_EngSwtBatt
    delegate CPT_IoSigAdc_SwSStellantisCmpstn.ColdCrkCasePSnsr <-> outer port ColdCrkCasePSnsr
    delegate CPT_IoSigAdc_SwSStellantisCmpstn.VeADCR_U_TPS1 <-> outer port VeADCR_U_TPS1
    delegate CPT_IoSigAdc_SwSStellantisCmpstn.ThrIntkGasT <-> outer port ThrIntkGasT
    delegate CPT_IoSigAdc_SwSStellantisCmpstn.VeADCR_U_LTR_TempSnsr <-> outer port VeADCR_U_LTR_TempSnsr
    delegate CPT_IoSigAdc_SwSStellantisCmpstn.ThrPosnSnsr2 <-> outer port ThrPosnSnsr2
    delegate CPT_IoSigAdc_SwSStellantisCmpstn.VeADCR_U_CluSns <-> outer port VeADCR_U_CluSns
    delegate CPT_IoSigAdc_SwSStellantisCmpstn.PedlValSnsr2Aux <-> outer port PedlValSnsr2Aux
    delegate CPT_IoSigAdc_SwSStellantisCmpstn.CooltInletTemp <-> outer port CooltInletTemp
    delegate CPT_IoSigAdc_SwSStellantisCmpstn.VeADCR_U_OilPresSnsr <-> outer port VeADCR_U_OilPresSnsr
    delegate CPT_IoSigAdc_SwSStellantisCmpstn.PedlValSnsr2 <-> outer port PedlValSnsr2
    delegate CPT_IoSigAdc_SwSStellantisCmpstn.GetADCR_U_PFIFuRailTempAdcInp <-> outer port GetADCR_U_PFIFuRailTempAdcInp
    delegate CPT_IoSigAdc_SwSStellantisCmpstn.AirCdngPSnsr <-> outer port AirCdngPSnsr
    delegate CPT_IoSigAdc_SwSStellantisCmpstn.LoPFuSnsr <-> outer port LoPFuSnsr
    delegate CPT_IoSigAdc_SwSStellantisCmpstn.VeADCR_U_CldCrkCasePresSnsr <-> outer port VeADCR_U_CldCrkCasePresSnsr
    delegate CPT_IoSigAdc_SwSStellantisCmpstn.VeADCR_U_GDI_FuRail1Pres <-> outer port VeADCR_U_GDI_FuRail1Pres
    delegate CPT_IoSigAdc_SwSStellantisCmpstn.GdiFuRailP1 <-> outer port GdiFuRailP1
    delegate CPT_IoSigAdc_SwSStellantisCmpstn.EngCooltT <-> outer port EngCooltT
    delegate CPT_IoSigAdc_SwSStellantisCmpstn.VeADCR_U_IntkAirTemp <-> outer port VeADCR_U_IntkAirTemp
    delegate CPT_IoSigAdc_SwSStellantisCmpstn.VeADCR_U_EngCooltTemp <-> outer port VeADCR_U_EngCooltTemp
    delegate CPT_IoSigAdc_SwSStellantisCmpstn.CalInp2 <-> outer port CalInp2
    delegate CPT_IoSigAdc_SwSStellantisCmpstn.VeADCR_U_MnfdAirPres <-> outer port VeADCR_U_MnfdAirPres
    delegate CPT_IoSigAdc_SwSStellantisCmpstn.VeADCR_U_ThrIntkGasTempSns <-> outer port VeADCR_U_ThrIntkGasTempSns
    delegate CPT_IoSigAdc_SwSStellantisCmpstn.VeADCR_U_TPS2 <-> outer port VeADCR_U_TPS2
    delegate CPT_IoSigAdc_SwSStellantisCmpstn.VsADCR_U_CalInp1 <-> outer port VsADCR_U_CalInp1
    delegate CPT_IoSigAdc_SwSStellantisCmpstn.MnfldAirP <-> outer port MnfldAirP
    delegate CPT_IoSigAdc_SwSStellantisCmpstn.CalInp1 <-> outer port CalInp1
    delegate CPT_IoSigAdc_SwSStellantisCmpstn.HoodAjar <-> outer port HoodAjar
    delegate CPT_IoSigAdc_SwSStellantisCmpstn.VeADCR_U_C3WV <-> outer port VeADCR_U_C3WV
    delegate CPT_IoSigAdc_SwSStellantisCmpstn.GetADCR_U_OilShutOffValveFbAdcInp <-> outer port GetADCR_U_OilShutOffValveFbAdcInp
    delegate CPT_IoSigAdc_SwSStellantisCmpstn.VeADCR_U_PFIFuRailPress <-> outer port VeADCR_U_PFIFuRailPress
    delegate CPT_IoSigAdc_SwSStellantisCmpstn.CrkBattMonr <-> outer port CrkBattMonr
    delegate CPT_IoSigAdc_SwSStellantisCmpstn.FuTankPSnsr <-> outer port FuTankPSnsr
    delegate CPT_IoSigAdc_SwSStellantisCmpstn.VeADCR_U_PFIFuRailTemp <-> outer port VeADCR_U_PFIFuRailTemp
    delegate CPT_IoSigAdc_SwSStellantisCmpstn.IntkAirT <-> outer port IntkAirT
    delegate CPT_IoSigAdc_SwSStellantisCmpstn.VeADCR_U_PdlValSnsr1 <-> outer port VeADCR_U_PdlValSnsr1
    delegate CPT_IoSigAdc_SwSStellantisCmpstn.VeADCR_U_PdlValSnsr2 <-> outer port VeADCR_U_PdlValSnsr2
    delegate CPT_IoSigAdc_SwSStellantisCmpstn.SysU12Volt <-> outer port SysU12Volt
    delegate CPT_IoSigAdc_SwSStellantisCmpstn.ThrIntkP <-> outer port ThrIntkP
    delegate CPT_IoSigAdc_SwSStellantisCmpstn.VeADCR_U_MnfdGasTemp <-> outer port VeADCR_U_MnfdGasTemp
    delegate CPT_IoSigAdc_SwSStellantisCmpstn.VeADCR_U_OilTempSnsr <-> outer port VeADCR_U_OilTempSnsr
    delegate CPT_IoSigAdc_SwSStellantisCmpstn.VeADCR_U_AirCdngPresSnsr <-> outer port VeADCR_U_AirCdngPresSnsr
    delegate CPT_IoSigAdc_SwSStellantisCmpstn.ThrPosnSnsr1 <-> outer port ThrPosnSnsr1
    delegate CPT_IoSigAdc_SwSStellantisCmpstn.VeADCR_U_SysVolt12Volt <-> outer port VeADCR_U_SysVolt12Volt
    delegate CPT_IoSigAdc_SwSStellantisCmpstn.MnfldGasT <-> outer port MnfldGasT
    delegate CPT_IoSigAdc_SwSStellantisCmpstn.GetADCR_U_PFIFuRailPressAdcInp <-> outer port GetADCR_U_PFIFuRailPressAdcInp
    delegate CPT_IoSigAdc_SwSStellantisCmpstn.Coolt3WayVlv <-> outer port Coolt3WayVlv
    delegate CPT_IoSigAdc_SwSStellantisCmpstn.WgPosn1 <-> outer port WgPosn1
    delegate CPT_IoSigAdc_SwSStellantisCmpstn.VeADCR_U_LoPresFuSnsr <-> outer port VeADCR_U_LoPresFuSnsr
    delegate CPT_IoSigAdc_SwSStellantisCmpstn.BrkPdlPosnSnsr <-> outer port BrkPdlPosnSnsr
    delegate CPT_IoSigAdc_SwSStellantisCmpstn.GetADCR_U_CluSnsAdcInp <-> outer port GetADCR_U_CluSnsAdcInp
    delegate CPT_IoSigAdc_SwSStellantisCmpstn.VsADCR_U_CalInp2 <-> outer port VsADCR_U_CalInp2
    delegate CPT_IoSigAdc_SwSStellantisCmpstn.VeADCR_U_CrkBattMonr <-> outer port VeADCR_U_CrkBattMonr
    delegate CPT_IoSigAdc_SwSStellantisCmpstn.OilTSnsr <-> outer port OilTSnsr
    delegate CPT_IoSigAdc_SwSStellantisCmpstn.VeADCR_U_HoodAjar <-> outer port VeADCR_U_HoodAjar
    delegate CPT_IoSigAdc_SwSStellantisCmpstn.VeADCR_U_FuTankPresSnsr <-> outer port VeADCR_U_FuTankPresSnsr
    delegate CPT_IoSigAdc_SwSStellantisCmpstn.EngSwtBatt <-> outer port EngSwtBatt
    delegate CPT_Cdd_Composition.VeLWRR_I_PmpCellUsMidEPP_Bnk1 <-> outer port VeLWRR_I_PmpCellUsMidEPP_Bnk1
    delegate CPT_Cdd_Composition.VeFPCR_t_IfLowrCurrPullInTi <-> outer port VeFPCR_t_IfLowrCurrPullInTi
    delegate CPT_Cdd_Composition.VeLWRR_I_PmpCellUsTDC_Bnk1 <-> outer port VeLWRR_I_PmpCellUsTDC_Bnk1
    delegate CPT_Cdd_Composition.VeFPCR_I_IfLowrCurrHysPullIn <-> outer port VeFPCR_I_IfLowrCurrHysPullIn
    delegate CPT_Cdd_Composition.VeFPCR_b_RglnActv <-> outer port VeFPCR_b_RglnActv
    delegate CPT_Cdd_Composition.VeFPCR_I_IfLowrCurrHysHld <-> outer port VeFPCR_I_IfLowrCurrHysHld
    delegate CPT_Cdd_Composition.UpdateLLKR_FiltCoeff_SwKnkCh1 <-> outer port UpdateLLKR_FiltCoeff_SwKnkCh1
    delegate CPT_Cdd_Composition.VeLWRR_I_PmpCellUs10MsBnk2 <-> outer port VeLWRR_I_PmpCellUs10MsBnk2
    delegate CPT_Cdd_Composition.VeFPCR_I_IfLowrCurrHld <-> outer port VeFPCR_I_IfLowrCurrHld
    delegate CPT_Cdd_Composition.VeFPCR_I_IfLowrCurrPullIn <-> outer port VeFPCR_I_IfLowrCurrPullIn
    delegate CPT_Cdd_Composition.VeLLKR_Cnt_MeasmtWin1_SwKnkCh2 <-> outer port VeLLKR_Cnt_MeasmtWin1_SwKnkCh2
    delegate CPT_Cdd_Composition.UpdateLLKR_MeasmtWinData_SwKnkCh2 <-> outer port UpdateLLKR_MeasmtWinData_SwKnkCh2
    delegate CPT_Cdd_Composition.VeLWRR_I_PmpCellUs10MsBnk1 <-> outer port VeLWRR_I_PmpCellUs10MsBnk1
    delegate CPT_Cdd_Composition.UpdateLLKR_MeasmtWinData_SwKnkCh3 <-> outer port UpdateLLKR_MeasmtWinData_SwKnkCh3
    delegate CPT_Cdd_Composition.VeLLKR_Cnt_MeasmtWin1_SwKnkCh3 <-> outer port VeLLKR_Cnt_MeasmtWin1_SwKnkCh3
    delegate CPT_Cdd_Composition.UpdateLLKR_MeasmtWinData_SwKnkCh1 <-> outer port UpdateLLKR_MeasmtWinData_SwKnkCh1
    delegate CPT_Cdd_Composition.VeLWRR_R_WRO2_CellResistUsBnk2 <-> outer port VeLWRR_R_WRO2_CellResistUsBnk2
    delegate CPT_Cdd_Composition.VeLLKR_Cnt_MeasmtWin2_SwKnkCh2 <-> outer port VeLLKR_Cnt_MeasmtWin2_SwKnkCh2
    delegate CPT_Cdd_Composition.VeLLKR_Cnt_MeasmtWin2_SwKnkCh3 <-> outer port VeLLKR_Cnt_MeasmtWin2_SwKnkCh3
    delegate CPT_Cdd_Composition.VeFPCR_Cnt_HiPresPmpDrvCamLobe <-> outer port VeFPCR_Cnt_HiPresPmpDrvCamLobe
    delegate CPT_Cdd_Composition.VeFPCR_phi_IfHldCrkAng <-> outer port VeFPCR_phi_IfHldCrkAng
    delegate CPT_Cdd_Composition.RequestLLKR_Measmt_SwKnkCh2 <-> outer port RequestLLKR_Measmt_SwKnkCh2
    delegate CPT_Cdd_Composition.UpdateLLKR_FiltCoeff_SwKnkCh3 <-> outer port UpdateLLKR_FiltCoeff_SwKnkCh3
    delegate CPT_Cdd_Composition.VeFPCR_phi_IfCrkAng <-> outer port VeFPCR_phi_IfCrkAng
    delegate CPT_Cdd_Composition.UpdateLLKR_FiltCoeff_SwKnkCh2 <-> outer port UpdateLLKR_FiltCoeff_SwKnkCh2
    delegate CPT_Cdd_Composition.VeLWRR_R_WRO2_CellResistUsBnk1 <-> outer port VeLWRR_R_WRO2_CellResistUsBnk1
    delegate CPT_Cdd_Composition.VeFPCR_phi_IfCrkAngOffs <-> outer port VeFPCR_phi_IfCrkAngOffs
    delegate CPT_Cdd_Composition.VeLLKR_Cnt_MeasmtWin2_SwKnkCh1 <-> outer port VeLLKR_Cnt_MeasmtWin2_SwKnkCh1
    delegate CPT_Cdd_Composition.VeLWRR_I_PmpCellUsTDC_Bnk2 <-> outer port VeLWRR_I_PmpCellUsTDC_Bnk2
    delegate CPT_Cdd_Composition.VeLLKR_Cnt_MeasmtWin1_SwKnkCh1 <-> outer port VeLLKR_Cnt_MeasmtWin1_SwKnkCh1
    delegate CPT_Cdd_Composition.VeFPCR_b_CrkAngOvrdActv <-> outer port VeFPCR_b_CrkAngOvrdActv
    delegate CPT_Cdd_Composition.RequestLLKR_Measmt_SwKnkCh3 <-> outer port RequestLLKR_Measmt_SwKnkCh3
    delegate CPT_Cdd_Composition.RequestLLKR_Measmt_SwKnkCh1 <-> outer port RequestLLKR_Measmt_SwKnkCh1
    delegate CPT_IoSigDioOutp_SwSStellantisCmpstn.VeDIOR_OBD_PurgVentVlvHwDiagCmn <-> outer port VeDIOR_OBD_PurgVentVlvHwDiagCmn
    delegate CPT_IoSigIfAdapt_SwSStellantisCmpstn.VeDEVR_b_DevlpmtToolEnbld <-> outer port VeDEVR_b_DevlpmtToolEnbld
    delegate CPT_IoSigDioOutp_SwSStellantisCmpstn.VeDIOR_InrushCircRlyHwDiagFltOutp <-> outer port VeDIOR_InrushCircRlyHwDiagFltOutp
    delegate CPT_rbm_DSM_Conf.PP_rbm_Dsm_Conf_FcmClrCntr <-> outer port VeDIDR_Cnt_Mode4Rst
    delegate CPT_IoSigDioOutp_SwSStellantisCmpstn.VeDIOR_LoPresFuPmpRlyHwDiagCmn <-> outer port VeDIOR_LoPresFuPmpRlyHwDiagCmn
    delegate CPT_IoSigDioOutp_SwSStellantisCmpstn.VeDIOR_AC_CluRlyHwDiagFltCircDtctd <-> outer port VeDIOR_AC_CluRlyHwDiagFltCircDtctd
    delegate CPT_IoSigIfAdapt_SwSStellantisCmpstn.VeSPLR_b_BattBackedRAM_Init <-> outer port VeSPLR_b_BattBackedRAM_Init
    delegate CPT_IoSigPwmOutp_SwSStellantisCmpstn.SetDIOR_e_VvtExh1OutpOps <-> outer port SetDIOR_e_VvtExh1OutpOps
    delegate CPT_IoSigHbrdg_SwSStellantisCmpstn.VeDIOR_b_Hbrdg_Coold_EGR_DiagFltCircDtctd <-> outer port VeDIOR_b_Hbrdg_Coold_EGR_DiagFltCircDtctd
    delegate CPT_IoSigPwmOutp_SwSStellantisCmpstn.VeDIOR_VvtExh1_HwDiagFltCircDtctd <-> outer port VeDIOR_VvtExh1_HwDiagFltCircDtctd
    delegate CPT_IoSigDioOutp_SwSStellantisCmpstn.SetDIOR_b_DMTLLkPmpOutpSt <-> outer port SetDIOR_b_DMTLLkPmpOutpSt
    delegate CPT_IoSigDioOutp_SwSStellantisCmpstn.VeDIOR_e_RadrFanRlyHiSpdIndDiagInfo <-> outer port VeDIOR_e_RadrFanRlyHiSpdIndDiagInfo
    delegate CPT_IoSigPwmOutp_SwSStellantisCmpstn.VeDIOR_e_ElecPhsrMtrCmdOutpIndDiagInfo <-> outer port VeDIOR_e_ElecPhsrMtrCmdOutpIndDiagInfo
    delegate CPT_IoSigDioOutp_SwSStellantisCmpstn.VeDIOR_e_SrgSoln1IndDiagInfo <-> outer port VeDIOR_e_SrgSoln1IndDiagInfo
    delegate CPT_IoSigDioOutp_SwSStellantisCmpstn.VeDIOR_AC_CluRlyHwDiagFltOutp <-> outer port VeDIOR_AC_CluRlyHwDiagFltOutp
    delegate CPT_IoSigHbrdg_SwSStellantisCmpstn.VeDIOR_h_Hbrdg_ETC_Motor_Sts <-> outer port VeDIOR_h_Hbrdg_ETC_Motor_Sts
    delegate CPT_IoSigPwmOutp_SwSStellantisCmpstn.VeDIOR_VarOilSoln_HwDiagFltCircDtctd <-> outer port VeDIOR_VarOilSoln_HwDiagFltCircDtctd
    delegate CPT_IoSigDioOutp_SwSStellantisCmpstn.VeDIOR_LoPresFuPmpRlyHwDiagFltOutp <-> outer port VeDIOR_LoPresFuPmpRlyHwDiagFltOutp
    delegate CPT_IoSigDioOutp_SwSStellantisCmpstn.VeDIOR_e_SwilEngMnt1IndDiagInfo <-> outer port VeDIOR_e_SwilEngMnt1IndDiagInfo
    delegate CPT_IoSigDioInp_SwSStellantisCmpstn.VeDIOR_b_ECM_WakeUpDigInpImdtVal <-> outer port VeDIOR_b_ECM_WakeUpDigInpImdtVal
    delegate CPT_IoSigDioOutp_SwSStellantisCmpstn.VeDIOR_e_LoPresFuPmpRlyIndDiagInfo <-> outer port VeDIOR_e_LoPresFuPmpRlyIndDiagInfo
    delegate CPT_IoSigDioOutp_SwSStellantisCmpstn.SetDIOR_b_SwilEngMnt2OutpSt <-> outer port SetDIOR_b_SwilEngMnt2OutpSt
    delegate CPT_IoSigPwmOutp_SwSStellantisCmpstn.VeDIOR_VarOilSoln_HwDiagCmn <-> outer port VeDIOR_VarOilSoln_HwDiagCmn
    delegate CPT_IoSigHbrdg_SwSStellantisCmpstn.ServDIOR_Hbrdg_DP <-> outer port ServDIOR_Hbrdg_DP
    delegate CPT_IoSigHbrdg_SwSStellantisCmpstn.VeDIOR_h_Hbrdg_Coold_EGR_Sts <-> outer port VeDIOR_h_Hbrdg_Coold_EGR_Sts
    delegate CPT_IoSigPwr_SwSStellantisCmpstn.VeSPLR_g_PwrSplyInfo <-> outer port VeSPLR_g_PwrSplyInfo
    delegate CPT_IoSigPwmOutp_SwSStellantisCmpstn.VeDIOR_VarOilSoln_HwDiagFltOutp <-> outer port VeDIOR_VarOilSoln_HwDiagFltOutp
    delegate CPT_IoSigDioOutp_SwSStellantisCmpstn.VeDIOR_e_OBD_PurgVentVlvIndDiagInfo <-> outer port VeDIOR_e_OBD_PurgVentVlvIndDiagInfo
    delegate CPT_IoSigDioInp_SwSStellantisCmpstn.VeDIOR_b_BrkSwDigInpImdtVal <-> outer port VeDIOR_b_BrkSwDigInpImdtVal
    delegate CPT_IoSigDioOutp_SwSStellantisCmpstn.VeDIOR_StrtrRlyHwDiagFltOutp <-> outer port VeDIOR_StrtrRlyHwDiagFltOutp
    delegate CPT_IoSigDioOutp_SwSStellantisCmpstn.VeDIOR_InrushCircRlyHwDiagCmn <-> outer port VeDIOR_InrushCircRlyHwDiagCmn
    delegate CPT_IoSigPwmOutp_SwSStellantisCmpstn.SetDIOR_e_PurgSolnOutpOps <-> outer port SetDIOR_e_PurgSolnOutpOps
    delegate CPT_IoSigPwmOutp_SwSStellantisCmpstn.VeDIOR_ElecPhsrMtrCmd_HwDiagFltOutp <-> outer port VeDIOR_ElecPhsrMtrCmd_HwDiagFltOutp
    delegate CPT_IoSigPwmOutp_SwSStellantisCmpstn.SetDIOR_e_FuPmpCtlMdulCmdOutpOps <-> outer port SetDIOR_e_FuPmpCtlMdulCmdOutpOps
    delegate CPT_IoSigDioOutp_SwSStellantisCmpstn.VeDIOR_OBD_PurgVentVlvHwDiagFltCircDtctd <-> outer port VeDIOR_OBD_PurgVentVlvHwDiagFltCircDtctd
    delegate CPT_IoSigDioOutp_SwSStellantisCmpstn.SetDIOR_b_LoPresFuPmpRlyOutpSt <-> outer port SetDIOR_b_LoPresFuPmpRlyOutpSt
    delegate CPT_IoSigHbrdg_SwSStellantisCmpstn.VeDIOR_b_Hbrdg_DP_DiagFltCircDtctd <-> outer port VeDIOR_b_Hbrdg_DP_DiagFltCircDtctd
    delegate CPT_IoSigPwr_SwSStellantisCmpstn.VeSPLR_b_PwrSplyDiagInfo <-> outer port VeSPLR_b_PwrSplyDiagInfo
    delegate CPT_IoSigPwmOutp_SwSStellantisCmpstn.VeDIOR_FuPmpCtlMdulCmd_HwDiagFltCircDtctd <-> outer port VeDIOR_FuPmpCtlMdulCmd_HwDiagFltCircDtctd
    delegate CPT_IoSigDioOutp_SwSStellantisCmpstn.VeDIOR_AC_CluRlyHwDiagCmn <-> outer port VeDIOR_AC_CluRlyHwDiagCmn
    delegate CPT_IoSigDioOutp_SwSStellantisCmpstn.VeDIOR_RadrFanRlyHiSpdHwDiagCmn <-> outer port VeDIOR_RadrFanRlyHiSpdHwDiagCmn
    delegate CPT_IoSigHbrdg_SwSStellantisCmpstn.VeDIOR_b_Hbrdg_Wg1_DiagFltCircDtctd <-> outer port VeDIOR_b_Hbrdg_Wg1_DiagFltCircDtctd
    delegate CPT_IoSigPwmOutp_SwSStellantisCmpstn.SetDIOR_e_VarOilSolnOutpOps <-> outer port SetDIOR_e_VarOilSolnOutpOps
    delegate CPT_IoSigHbrdg_SwSStellantisCmpstn.ServDIOR_Hbrdg_Coold_EGR <-> outer port ServDIOR_Hbrdg_Coold_EGR
    delegate CPT_IoSigPwmInp_SwSStellantisCmpstn.VeDIOR_Pct_FPCM_Fb1_PWM_Inp_DC <-> outer port VeDIOR_Pct_FPCM_Fb1_PWM_Inp_DC
    delegate CPT_IoSigDioOutp_SwSStellantisCmpstn.SetDIOR_b_SwilEngMnt1OutpSt <-> outer port SetDIOR_b_SwilEngMnt1OutpSt
    delegate CPT_IoSigHbrdg_SwSStellantisCmpstn.VeDIOR_h_Hbrdg_Wg1_Sts <-> outer port VeDIOR_h_Hbrdg_Wg1_Sts
    delegate CPT_IoSigHbrdg_SwSStellantisCmpstn.VeDIOR_b_Hbrdg_ETC_Motor_DiagFltCircDtctd <-> outer port VeDIOR_b_Hbrdg_ETC_Motor_DiagFltCircDtctd
    delegate CPT_IoSigDioInp_SwSStellantisCmpstn.VeDIOR_b_NVLD_SwDigInpFiltdVal <-> outer port VeDIOR_b_NVLD_SwDigInpFiltdVal
    delegate CPT_IoSigHbrdg_SwSStellantisCmpstn.ServDIOR_Hbrdg_ETC_Motor <-> outer port ServDIOR_Hbrdg_ETC_Motor
    delegate CPT_IoSigPwmOutp_SwSStellantisCmpstn.VeDIOR_e_VarOilSolnIndDiagInfo <-> outer port VeDIOR_e_VarOilSolnIndDiagInfo
    delegate CPT_IoSigDioInp_SwSStellantisCmpstn.VeDIOR_b_DynoFuDsblReqSwDigInpFiltdVal <-> outer port VeDIOR_b_DynoFuDsblReqSwDigInpFiltdVal
    delegate CPT_IoSigDioOutp_SwSStellantisCmpstn.VeDIOR_e_MakeUpAirVlvIndDiagInfo <-> outer port VeDIOR_e_MakeUpAirVlvIndDiagInfo
    delegate CPT_IoSigPwmOutp_SwSStellantisCmpstn.VeDIOR_ElecPhsrMtrCmd_HwDiagCmn <-> outer port VeDIOR_ElecPhsrMtrCmd_HwDiagCmn
    delegate CPT_IoSigPwr_SwSStellantisCmpstn.VeSPLR_b_BattDiscnctSts <-> outer port VeSPLR_b_BattDiscnctSts
    delegate CPT_IoSigDioOutp_SwSStellantisCmpstn.VeDIOR_SrgSoln1HwDiagCmn <-> outer port VeDIOR_SrgSoln1HwDiagCmn
    delegate CPT_IoSigDioOutp_SwSStellantisCmpstn.VeDIOR_e_StrtrRlyIndDiagInfo <-> outer port VeDIOR_e_StrtrRlyIndDiagInfo
    delegate CPT_IoSigPwmOutp_SwSStellantisCmpstn.VeDIOR_VvtExh1_HwDiagCmn <-> outer port VeDIOR_VvtExh1_HwDiagCmn
    delegate CPT_IoSigDioOutp_SwSStellantisCmpstn.SetDIOR_b_SrgSoln1OutpSt <-> outer port SetDIOR_b_SrgSoln1OutpSt
    delegate CPT_IoSigPwmOutp_SwSStellantisCmpstn.VeDIOR_RadrFanCtrlPwm_HwDiagCmn <-> outer port VeDIOR_RadrFanCtrlPwm_HwDiagCmn
    delegate CPT_IoSigPwmOutp_SwSStellantisCmpstn.VeDIOR_e_FuPmpCtlMdulCmdIndDiagInfo <-> outer port VeDIOR_e_FuPmpCtlMdulCmdIndDiagInfo
    delegate CPT_IoSigDioOutp_SwSStellantisCmpstn.VeDIOR_StrtrRlyHwDiagFltCircDtctd <-> outer port VeDIOR_StrtrRlyHwDiagFltCircDtctd
    delegate CPT_IoSigDioOutp_SwSStellantisCmpstn.SetDIOR_b_AC_CluRlyOutpSt <-> outer port SetDIOR_b_AC_CluRlyOutpSt
    delegate CPT_IoSigPwmOutp_SwSStellantisCmpstn.VeDIOR_ElecPhsrMtrCmd_HwDiagFltCircDtctd <-> outer port VeDIOR_ElecPhsrMtrCmd_HwDiagFltCircDtctd
    delegate CPT_IoSigDioOutp_SwSStellantisCmpstn.VeDIOR_StrtrRlyHwDiagCmn <-> outer port VeDIOR_StrtrRlyHwDiagCmn
    delegate CPT_IoSigPwmOutp_SwSStellantisCmpstn.SetDIOR_e_ElecPhsrMtrCmdOutpOutpOps <-> outer port SetDIOR_e_ElecPhsrMtrCmdOutpOutpOps
    delegate CPT_IoSigDioOutp_SwSStellantisCmpstn.VeDIOR_LoPresFuPmpRlyHwDiagFltCircDtctd <-> outer port VeDIOR_LoPresFuPmpRlyHwDiagFltCircDtctd
    delegate CPT_IoSigHbrdg_SwSStellantisCmpstn.VeDIOR_h_Hbrdg_DP_Sts <-> outer port VeDIOR_h_Hbrdg_DP_Sts
    delegate CPT_IoSigPwmOutp_SwSStellantisCmpstn.SetDIOR_e_RadrFanCtrlPwmOutpOps <-> outer port SetDIOR_e_RadrFanCtrlPwmOutpOps
    delegate CPT_IoSigPwmOutp_SwSStellantisCmpstn.VeDIOR_PurgSoln_HwDiagCmn <-> outer port VeDIOR_PurgSoln_HwDiagCmn
    delegate CPT_IoSigDioOutp_SwSStellantisCmpstn.VeDIOR_SwilEngMnt1HwDiagFltOutp <-> outer port VeDIOR_SwilEngMnt1HwDiagFltOutp
    delegate CPT_IoSigDioInp_SwSStellantisCmpstn.VeDIOR_b_ECM_WakeUpDigInpFiltdVal <-> outer port VeDIOR_b_ECM_WakeUpDigInpFiltdVal
    delegate CPT_IoSigPwmInp_SwSStellantisCmpstn.VeDIOR_b_FPCM_Fb1_PWM_Inp_TO_Sts <-> outer port VeDIOR_b_FPCM_Fb1_PWM_Inp_TO_Sts
    delegate CPT_IoSigDioOutp_SwSStellantisCmpstn.VeDIOR_SrgSoln1HwDiagFltOutp <-> outer port VeDIOR_SrgSoln1HwDiagFltOutp
    delegate CPT_IoSigPwmOutp_SwSStellantisCmpstn.VeDIOR_RadrFanCtrlPwm_HwDiagFltOutp <-> outer port VeDIOR_RadrFanCtrlPwm_HwDiagFltOutp
    delegate CPT_IoSigPwmOutp_SwSStellantisCmpstn.VeDIOR_e_PurgSolnIndDiagInfo <-> outer port VeDIOR_e_PurgSolnIndDiagInfo
    delegate CPT_IoSigPwmInp_SwSStellantisCmpstn.VeDIOR_h_FPCMFb1_PwmInp <-> outer port VeDIOR_h_FPCMFb1_PwmInp
    delegate CPT_IoSigPwr_SwSStellantisCmpstn.PwrSplyOps <-> outer port PwrSplyOps
    delegate CPT_IoSigDioOutp_SwSStellantisCmpstn.VeDIOR_e_InrushCircRlyIndDiagInfo <-> outer port VeDIOR_e_InrushCircRlyIndDiagInfo
    delegate CPT_IoSigPwmOutp_SwSStellantisCmpstn.VeDIOR_PurgSoln_HwDiagFltCircDtctd <-> outer port VeDIOR_PurgSoln_HwDiagFltCircDtctd
    delegate CPT_IoSigDioInp_SwSStellantisCmpstn.VeDIOR_b_StrtrRlyFbDigInpFiltdVal <-> outer port VeDIOR_b_StrtrRlyFbDigInpFiltdVal
    delegate CPT_IoSigPwmOutp_SwSStellantisCmpstn.VeDIOR_e_VvtExh1IndDiagInfo <-> outer port VeDIOR_e_VvtExh1IndDiagInfo
    delegate CPT_IoSigPwmOutp_SwSStellantisCmpstn.VeDIOR_PurgSoln_HwDiagFltOutp <-> outer port VeDIOR_PurgSoln_HwDiagFltOutp
    delegate CPT_IoSigDioOutp_SwSStellantisCmpstn.VeDIOR_InrushCircRlyHwDiagFltCircDtctd <-> outer port VeDIOR_InrushCircRlyHwDiagFltCircDtctd
    delegate CPT_IoSigDioOutp_SwSStellantisCmpstn.SetDIOR_b_InrushCircRlyOutpSt <-> outer port SetDIOR_b_InrushCircRlyOutpSt
    delegate CPT_IoSigDioOutp_SwSStellantisCmpstn.VeDIOR_RadrFanRlyHiSpdHwDiagFltCircDtctd <-> outer port VeDIOR_RadrFanRlyHiSpdHwDiagFltCircDtctd
    delegate CPT_IoSigDioOutp_SwSStellantisCmpstn.SetDIOR_b_OBD_PurgVentVlvOutpSt <-> outer port SetDIOR_b_OBD_PurgVentVlvOutpSt
    delegate CPT_IoSigDioOutp_SwSStellantisCmpstn.VeDIOR_RadrFanRlyHiSpdHwDiagFltOutp <-> outer port VeDIOR_RadrFanRlyHiSpdHwDiagFltOutp
    delegate CPT_IoSigPwmOutp_SwSStellantisCmpstn.VeDIOR_FuPmpCtlMdulCmd_HwDiagFltOutp <-> outer port VeDIOR_FuPmpCtlMdulCmd_HwDiagFltOutp
    delegate CPT_IoSigDioInp_SwSStellantisCmpstn.VeDIOR_b_IgnRunStrtSwDigInpImdtVal <-> outer port VeDIOR_b_IgnRunStrtSwDigInpImdtVal
    delegate CPT_IoSigHbrdg_SwSStellantisCmpstn.ServDIOR_Hbrdg_Wg1 <-> outer port ServDIOR_Hbrdg_Wg1
    delegate CPT_IoSigDioOutp_SwSStellantisCmpstn.SetDIOR_b_MakeUpAirVlvOutpSt <-> outer port SetDIOR_b_MakeUpAirVlvOutpSt
    delegate CPT_IoSigDioInp_SwSStellantisCmpstn.VeDIOR_b_BrkSwDigInpFiltdVal <-> outer port VeDIOR_b_BrkSwDigInpFiltdVal
    delegate CPT_IoSigDioInp_SwSStellantisCmpstn.VeDIOR_b_IgnRunStrtSwDigInpFiltdVal <-> outer port VeDIOR_b_IgnRunStrtSwDigInpFiltdVal
    delegate CPT_IoSigDioOutp_SwSStellantisCmpstn.VeDIOR_SwilEngMnt1HwDiagCmn <-> outer port VeDIOR_SwilEngMnt1HwDiagCmn
    delegate CPT_IoSigDioOutp_SwSStellantisCmpstn.VeDIOR_e_AC_CluRlyIndDiagInfo <-> outer port VeDIOR_e_AC_CluRlyIndDiagInfo
    delegate CPT_IoSigIfAdapt_SwSStellantisCmpstn.VeMAPR_p_IntkMnfdPres <-> outer port VeMAPR_p_IntkMnfdPres
    delegate CPT_IoSigPwmOutp_SwSStellantisCmpstn.VeDIOR_e_RadrFanCtrlPwmIndDiagInfo <-> outer port VeDIOR_e_RadrFanCtrlPwmIndDiagInfo
    delegate CPT_IoSigPwmOutp_SwSStellantisCmpstn.VeDIOR_FuPmpCtlMdulCmd_HwDiagCmn <-> outer port VeDIOR_FuPmpCtlMdulCmd_HwDiagCmn
    delegate CPT_IoSigDioOutp_SwSStellantisCmpstn.SetDIOR_b_StrtrRlyOutpSt <-> outer port SetDIOR_b_StrtrRlyOutpSt
    delegate CPT_IoSigPwmOutp_SwSStellantisCmpstn.VeDIOR_RadrFanCtrlPwm_HwDiagFltCircDtctd <-> outer port VeDIOR_RadrFanCtrlPwm_HwDiagFltCircDtctd
    delegate CPT_IoSigDioInp_SwSStellantisCmpstn.VeDIOR_b_StrtrRlyFbDigInpImdtVal <-> outer port VeDIOR_b_StrtrRlyFbDigInpImdtVal
    delegate CPT_IoSigDioOutp_SwSStellantisCmpstn.VeDIOR_OBD_PurgVentVlvHwDiagFltOutp <-> outer port VeDIOR_OBD_PurgVentVlvHwDiagFltOutp
    delegate CPT_IoSigDioOutp_SwSStellantisCmpstn.VeDIOR_SwilEngMnt1HwDiagFltCircDtctd <-> outer port VeDIOR_SwilEngMnt1HwDiagFltCircDtctd
    delegate CPT_IoSigDioOutp_SwSStellantisCmpstn.SetDIOR_b_RadrFanRlyHiSpdOutpSt <-> outer port SetDIOR_b_RadrFanRlyHiSpdOutpSt
    delegate CPT_IoSigIfAdapt_SwSStellantisCmpstn.VeFPCR_p_AbsValFiltd <-> outer port VeFPCR_p_AbsValFiltd
    delegate CPT_IoSigPwmOutp_SwSStellantisCmpstn.VeDIOR_VvtExh1_HwDiagFltOutp <-> outer port VeDIOR_VvtExh1_HwDiagFltOutp
    delegate CPT_IoSigDioInp_SwSStellantisCmpstn.VeDIOR_b_DynoFuDsblReqSwDigInpImdtVal <-> outer port VeDIOR_b_DynoFuDsblReqSwDigInpImdtVal
    delegate CPT_IoSigDioInp_SwSStellantisCmpstn.VeDIOR_b_NVLD_SwDigInpImdtVal <-> outer port VeDIOR_b_NVLD_SwDigInpImdtVal
    delegate CPT_IoSigDioOutp_SwSStellantisCmpstn.VeDIOR_SrgSoln1HwDiagFltCircDtctd <-> outer port VeDIOR_SrgSoln1HwDiagFltCircDtctd
    delegate CPT_SentStack_SwSStellantisCmpstn.GetSNTR_e_MAF_Hum_Snsr <-> outer port GetSNTR_e_MAF_Hum_Snsr
    delegate CPT_SentStack_SwSStellantisCmpstn.KeCFGR_b_DP_VlvPosnSnsChEquid <-> outer port KeCFGR_b_DP_VlvPosnSnsChEquid
    delegate CPT_SentStack_SwSStellantisCmpstn.KeCFGR_b_EGRCoolr_DeltAbsPresSnsrEquid <-> outer port KeCFGR_b_EGRCoolr_DeltAbsPresSnsrEquid
    delegate CPT_SentStack_SwSStellantisCmpstn.GetSNTR_e_DP_VlvPosnSns <-> outer port GetSNTR_e_DP_VlvPosnSns
    delegate CPT_SentStack_SwSStellantisCmpstn.KeCFGR_b_MAF_Hum_SnsrEquid <-> outer port KeCFGR_b_MAF_Hum_SnsrEquid
    delegate CPT_SentStack_SwSStellantisCmpstn.GetSNTR_e_EGRCoolr_DeltAbsPresSnsr <-> outer port GetSNTR_e_EGRCoolr_DeltAbsPresSnsr
    delegate CPT_IoSigDioInp_SwSStellantisCmpstn.KeCFGR_b_ECM_WakeUpDigInpEquid <-> outer port KeCFGR_b_ECM_WakeUpDigInpEquid
    delegate CPT_Cdd_Composition.VeWRSR_b_ResistCalcnVldUsBnk2 <-> outer port VeWRSR_b_ResistCalcnVldUsBnk2
    delegate CPT_IoSigAdc_SwSStellantisCmpstn.KeCFGR_b_ThrIntkPAdcInpEquid <-> outer port KeCFGR_b_ThrIntkPAdcInpEquid
    delegate CPT_IoSigDioInp_SwSStellantisCmpstn.VeDIOR_b_CluInterLockSwDigInpFiltdVal <-> outer port VeDIOR_b_CluInterLockSwDigInpFiltdVal
    delegate CPT_IoSigPwmOutp_SwSStellantisCmpstn.VeDIOR_e_AlterFieCtrlIndDiagInfo <-> outer port VeDIOR_e_AlterFieCtrlIndDiagInfo
    delegate CPT_IoSigAdc_SwSStellantisCmpstn.KeCFGR_b_WgPosn1AdcInpEquid <-> outer port KeCFGR_b_WgPosn1AdcInpEquid
    delegate CPT_IoSigHbrdg_SwSStellantisCmpstn.KeDIOR_b_ETC_Equid <-> outer port KeDIOR_b_ETC_Equid
    delegate CPT_IoSigDioInp_SwSStellantisCmpstn.KeCFGR_b_DynoFuDsblReqDigInpEquid <-> outer port KeCFGR_b_DynoFuDsblReqDigInpEquid
    delegate CPT_Cdd_Composition.VeSPDR_b_EngSpdCtrlIsActv <-> outer port VeSPDR_b_EngSpdCtrlIsActv
    delegate CPT_Cdd_Composition.VeEXHR_dm_UsCatMassFlowBnk2 <-> outer port VeEXHR_dm_UsCatMassFlowBnk2
    delegate CPT_IoSigAdc_SwSStellantisCmpstn.KeCFGR_b_EngSwtBattAdcInpEquid <-> outer port KeCFGR_b_EngSwtBattAdcInpEquid
    delegate CPT_IoSigPwmInp_SwSStellantisCmpstn.VeDIOR_Pct_AllGrPosnSnsr2_PWM_Inp_DC <-> outer port VeDIOR_Pct_AllGrPosnSnsr2_PWM_Inp_DC
    delegate CPT_IoSigAdc_SwSStellantisCmpstn.KeCFGR_b_ThrIntkGasTAdcInpEquid <-> outer port KeCFGR_b_ThrIntkGasTAdcInpEquid
    delegate CPT_IoSigAdc_SwSStellantisCmpstn.KeCFGR_b_BrkPdlPosnSnsrAdcInpEquid <-> outer port KeCFGR_b_BrkPdlPosnSnsrAdcInpEquid
    delegate CPT_Cdd_Composition.EngMtnMod <-> outer port EngMtnMod
    delegate CPT_IoSigAdc_SwSStellantisCmpstn.KeCFGR_b_Coolt3WayVlvAdcInpEquid <-> outer port KeCFGR_b_Coolt3WayVlvAdcInpEquid
    delegate CPT_IoSigAdc_SwSStellantisCmpstn.KeCFGR_b_FuTankPSnsrAdcInpEquid <-> outer port KeCFGR_b_FuTankPSnsrAdcInpEquid
    delegate CPT_Cdd_Composition.VeRPMR_b_EngStopd <-> outer port VeRPMR_b_EngStopd
    delegate CPT_Cdd_Composition.VeCAMR_t_CamTiInSpdWinExh1 <-> outer port VeCAMR_t_CamTiInSpdWinExh1
    delegate CPT_Cdd_Composition.VeRPMR_b_PrimSpdSnsrFailr <-> outer port VeRPMR_b_PrimSpdSnsrFailr
    delegate CPT_Cdd_Composition.VeRPMR_b_SecdSpdSnsrFailr <-> outer port VeRPMR_b_SecdSpdSnsrFailr
    delegate CPT_Cdd_Composition.VeOXTR_T_UsBnk1Temp <-> outer port VeOXTR_T_UsBnk1Temp
    delegate CPT_IoSigAdc_SwSStellantisCmpstn.KeCFGR_b_MnfldAirPAdcInpEquid <-> outer port KeCFGR_b_MnfldAirPAdcInpEquid
    delegate CPT_Cdd_Composition.VeEPSR_Cnt_NewBurstAvailEve <-> outer port VeEPSR_Cnt_NewBurstAvailEve
    delegate CPT_Cdd_Composition.VeBATR_U_12VoltSys <-> outer port VeBATR_U_12VoltSys
    delegate CPT_IoSigAdc_SwSStellantisCmpstn.KeCFGR_b_SysU12VoltAdcInpEquid <-> outer port KeCFGR_b_SysU12VoltAdcInpEquid
    delegate CPT_Cdd_Composition.GetEPSR_i_FgSeqOfCyl <-> outer port GetEPSR_i_FgSeqOfCyl
    delegate CPT_Cdd_Composition.VeRPMR_b_CrksftSpdSnsrCohrncy <-> outer port VeRPMR_b_CrksftSpdSnsrCohrncy
    delegate CPT_Cdd_Composition.VeSSCR_e_EngState <-> outer port VeSSCR_e_EngState
    delegate CPT_IoSigAdc_SwSStellantisCmpstn.KeCFGR_b_PedlValSnsr2AdcInpEquid <-> outer port KeCFGR_b_PedlValSnsr2AdcInpEquid
    delegate CPT_Cdd_Composition.VeRPMR_e_PrimSecdSpdSnsrSts <-> outer port VeRPMR_e_PrimSecdSpdSnsrSts
    delegate CPT_IoSigPwmInp_SwSStellantisCmpstn.VeDIOR_b_AllGrPosnSnsr1_PWM_Inp_TO_Sts <-> outer port VeDIOR_b_AllGrPosnSnsr1_PWM_Inp_TO_Sts
    delegate CPT_IoSigAdc_SwSStellantisCmpstn.KeCFGR_b_HoodAjarAdcInpEquid <-> outer port KeCFGR_b_HoodAjarAdcInpEquid
    delegate CPT_IoSigAdc_SwSStellantisCmpstn.KeCFGR_b_CcoldCrkCasePSnsrAdcInpEquid <-> outer port KeCFGR_b_CcoldCrkCasePSnsrAdcInpEquid
    delegate CPT_IoSigAdc_SwSStellantisCmpstn.KeCFGR_b_IntkAirTAdcInpEquid <-> outer port KeCFGR_b_IntkAirTAdcInpEquid
    delegate CPT_Cdd_Composition.GetCAMR_e_Exh1CamSt <-> outer port GetCAMR_e_Exh1CamSt
    delegate CPT_Cdd_Composition.VeEXHR_dm_UsCatMassFlowBnk1 <-> outer port VeEXHR_dm_UsCatMassFlowBnk1
    delegate CPT_IoSigAdc_SwSStellantisCmpstn.KeCFGR_b_CluSnsAdcInpEquid <-> outer port KeCFGR_b_CluSnsAdcInpEquid
    delegate CPT_Cdd_Composition.VeRPMR_e_EngSpdChkSts <-> outer port VeRPMR_e_EngSpdChkSts
    delegate CPT_IoSigAdc_SwSStellantisCmpstn.KeCFGR_b_CrkBattMonrAdcInpEquid <-> outer port KeCFGR_b_CrkBattMonrAdcInpEquid
    delegate CPT_IoSigAdc_SwSStellantisCmpstn.KeCFGR_b_OilPSnsrAdcInpEquid <-> outer port KeCFGR_b_OilPSnsrAdcInpEquid
    delegate CPT_IoSigDioInp_SwSStellantisCmpstn.KeCFGR_b_IgnRunStrtDigInpEquid <-> outer port KeCFGR_b_IgnRunStrtDigInpEquid
    delegate CPT_IoSigAdc_SwSStellantisCmpstn.KeCFGR_b_VarGeomTrbFbAdcInpEquid <-> outer port KeCFGR_b_VarGeomTrbFbAdcInpEquid
    delegate CPT_Cdd_Composition.GetEPSR_i_PrevCyl <-> outer port GetEPSR_i_PrevCyl
    delegate CPT_Cdd_Composition.VeOXSR_U_FiltdOutpVoltDsBnk1 <-> outer port VeOXSR_U_FiltdOutpVoltDsBnk1
    delegate CPT_IoSigPwmOutp_SwSStellantisCmpstn.KeCFGR_b_HTR_MeclWtrPmpActr_ChEquid <-> outer port KeCFGR_b_HTR_MeclWtrPmpActr_ChEquid
    delegate CPT_Cdd_Composition.VeWRSR_b_ResistCalcnVldUsBnk1 <-> outer port VeWRSR_b_ResistCalcnVldUsBnk1
    delegate CPT_IoSigPwmOutp_SwSStellantisCmpstn.KeCFGR_b_AlterFieCtrl_ChEquid <-> outer port KeCFGR_b_AlterFieCtrl_ChEquid
    delegate CPT_Cdd_Composition.GetLLSR_phi_IgnAng <-> outer port GetLLSR_phi_IgnAng
    delegate CPT_IoSigPwmOutp_SwSStellantisCmpstn.KeCFGR_b_FuPmpCtlMdulCmd_ChEquid <-> outer port KeCFGR_b_FuPmpCtlMdulCmd_ChEquid
    delegate CPT_IoSigDioInp_SwSStellantisCmpstn.KeCFGR_b_CluInterLockDigInpEquid <-> outer port KeCFGR_b_CluInterLockDigInpEquid
    delegate CPT_Cdd_Composition.VeBARR_p_Baro <-> outer port VeBARR_p_Baro
    delegate CPT_Cdd_Composition.VeEXHR_dm_ExhMassFlowBnk1 <-> outer port VeEXHR_dm_ExhMassFlowBnk1
    delegate CPT_IoSigPwmOutp_SwSStellantisCmpstn.KeCFGR_b_ElecPhsrMtrCmd_ChEquid <-> outer port KeCFGR_b_ElecPhsrMtrCmd_ChEquid
    delegate CPT_Cdd_Composition.VeRPMR_b_Exh1CamSpdSnsrCohrncy <-> outer port VeRPMR_b_Exh1CamSpdSnsrCohrncy
    delegate CPT_SentStack_SwSStellantisCmpstn.KsSNTR_h_DP_VlvPosnSns_SENTCfg <-> outer port KsSNTR_h_DP_VlvPosnSns_SENTCfg
    delegate CPT_Cdd_Composition.VeCAMR_t_ElecPhsrFbMeasFrqIntk1 <-> outer port VeCAMR_t_ElecPhsrFbMeasFrqIntk1
    delegate CPT_Cdd_Composition.GetRPMR_b_EngStrtThdExcdd <-> outer port GetRPMR_b_EngStrtThdExcdd
    delegate CPT_IoSigAdc_SwSStellantisCmpstn.KeCFGR_b_EngCooltTAdcInpEquid <-> outer port KeCFGR_b_EngCooltTAdcInpEquid
    delegate CPT_Cdd_Composition.VeEPSR_Cnt_PreMidEPP_Eve <-> outer port VeEPSR_Cnt_PreMidEPP_Eve
    delegate CPT_IoSigPwmInp_SwSStellantisCmpstn.VeDIOR_h_AllGrPosnSnsr2_PwmInp <-> outer port VeDIOR_h_AllGrPosnSnsr2_PwmInp
    delegate CPT_IoSigPwmOutp_SwSStellantisCmpstn.KeCFGR_b_VvtExh1_ChEquid <-> outer port KeCFGR_b_VvtExh1_ChEquid
    delegate CPT_Cdd_Composition.VeRPMR_b_Intk1CamSpdSnsrCohrncy <-> outer port VeRPMR_b_Intk1CamSpdSnsrCohrncy
    delegate CPT_Cdd_Composition.VeLWRR_b_WRO2_RdyUsBnk2 <-> outer port VeLWRR_b_WRO2_RdyUsBnk2
    delegate CPT_IoSigDioInp_SwSStellantisCmpstn.KeCFGR_b_BrkSwDigInpEquid <-> outer port KeCFGR_b_BrkSwDigInpEquid
    delegate CPT_Cdd_Composition.EngSpdMod <-> outer port EngSpdMod
    delegate CPT_IoSigPwmOutp_SwSStellantisCmpstn.VeDIOR_AlterFieCtrl_HwDiagCmn <-> outer port VeDIOR_AlterFieCtrl_HwDiagCmn
    delegate CPT_Cdd_Composition.GetCRKR_Cnt_CamBurstCnt <-> outer port GetCRKR_Cnt_CamBurstCnt
    delegate CPT_IoSigPwmOutp_SwSStellantisCmpstn.SetDIOR_e_HTR_MeclWtrPmpActrOutpOps <-> outer port SetDIOR_e_HTR_MeclWtrPmpActrOutpOps
    delegate CPT_IoSigPwmOutp_SwSStellantisCmpstn.VeDIOR_e_HTR_MeclWtrPmpActrIndDiagInfo <-> outer port VeDIOR_e_HTR_MeclWtrPmpActrIndDiagInfo
    delegate CPT_Cdd_Composition.VeINJR_b_RelsCL_Ctrl <-> outer port VeINJR_b_RelsCL_Ctrl
    delegate CPT_Cdd_Composition.VeCAMR_cnt_ElecPhsrFbTotDstIntk1 <-> outer port VeCAMR_cnt_ElecPhsrFbTotDstIntk1
    delegate CPT_IoSigAdc_SwSStellantisCmpstn.KeCFGR_b_CoolInletTempAdcInpEquid <-> outer port KeCFGR_b_CoolInletTempAdcInpEquid
    delegate CPT_Cdd_Composition.VeINJR_b_RelsCond_CVO_BasAdpn <-> outer port VeINJR_b_RelsCond_CVO_BasAdpn
    delegate CPT_IoSigDioInp_SwSStellantisCmpstn.VeDIOR_t_ECM_WakeUpDigInpOffTi <-> outer port VeDIOR_t_ECM_WakeUpDigInpOffTi
    delegate CPT_SentStack_SwSStellantisCmpstn.KsSNTR_h_MAF_Hum_Snsr_SENTCfg <-> outer port KsSNTR_h_MAF_Hum_Snsr_SENTCfg
    delegate CPT_Cdd_Composition.VeOXTR_T_DsBnk1Temp <-> outer port VeOXTR_T_DsBnk1Temp
    delegate CPT_IoSigAdc_SwSStellantisCmpstn.KeCFGR_b_CalInp2AdcInpEquid <-> outer port KeCFGR_b_CalInp2AdcInpEquid
    delegate CPT_Cdd_Composition.VeOXSR_U_OutpVoltDsBnk1 <-> outer port VeOXSR_U_OutpVoltDsBnk1
    delegate CPT_IoSigPwmOutp_SwSStellantisCmpstn.VeDIOR_HTR_MeclWtrPmpActr_HwDiagFltOutp <-> outer port VeDIOR_HTR_MeclWtrPmpActr_HwDiagFltOutp
    delegate CPT_IoSigAdc_SwSStellantisCmpstn.KeCFGR_b_GdiFuRailP1AdcInpEquid <-> outer port KeCFGR_b_GdiFuRailP1AdcInpEquid
    delegate CPT_Cdd_Composition.VeCAMR_t_CamTiInSpdWinIntk1 <-> outer port VeCAMR_t_CamTiInSpdWinIntk1
    delegate CPT_IoSigPwmOutp_SwSStellantisCmpstn.VeDIOR_AlterFieCtrl_HwDiagFltCircDtctd <-> outer port VeDIOR_AlterFieCtrl_HwDiagFltCircDtctd
    delegate CPT_Cdd_Composition.VeOXTR_T_DsBnk2Temp <-> outer port VeOXTR_T_DsBnk2Temp
    delegate CPT_Cdd_Composition.VeHCTR_T_ECT_AtStrt <-> outer port VeHCTR_T_ECT_AtStrt
    delegate CPT_IoSigAdc_SwSStellantisCmpstn.KeCFGR_b_ThrPosnSnsr2AdcInpEquid <-> outer port KeCFGR_b_ThrPosnSnsr2AdcInpEquid
    delegate CPT_IoSigHbrdg_SwSStellantisCmpstn.KeCFGR_b_VarGeomTrbEquid <-> outer port KeCFGR_b_VarGeomTrbEquid
    delegate CPT_Cdd_Composition.VeINJR_b_Rels_CVO_BasAdpn <-> outer port VeINJR_b_Rels_CVO_BasAdpn
    delegate CPT_Cdd_Composition.VeOXTR_T_UsBnk2Temp <-> outer port VeOXTR_T_UsBnk2Temp
    delegate CPT_Cdd_Composition.GetCRKR_b_CrksftUnlckdInRun <-> outer port GetCRKR_b_CrksftUnlckdInRun
    delegate CPT_IoSigAdc_SwSStellantisCmpstn.KeCFGR_b_PFIFuRailTempAdcInpEquid <-> outer port KeCFGR_b_PFIFuRailTempAdcInpEquid
    delegate CPT_SentStack_SwSStellantisCmpstn.KsSNTR_h_EGRCoolr_DeltAbsPresSnsr_SENTCfg <-> outer port KsSNTR_h_EGRCoolr_DeltAbsPresSnsr_SENTCfg
    delegate CPT_Cdd_Composition.VeOXSR_b_RdngRdyDsBnk2 <-> outer port VeOXSR_b_RdngRdyDsBnk2
    delegate CPT_IoSigPwmOutp_SwSStellantisCmpstn.KeCFGR_b_VarOilSoln_ChEquid <-> outer port KeCFGR_b_VarOilSoln_ChEquid
    delegate CPT_Cdd_Composition.VeOXSR_U_OutpVoltDsBnk2 <-> outer port VeOXSR_U_OutpVoltDsBnk2
    delegate CPT_IoSigHbrdg_SwSStellantisCmpstn.KeCFGR_b_WgHbrdgEquid <-> outer port KeCFGR_b_WgHbrdgEquid
    delegate CPT_Cdd_Composition.VeEEQR_r_ExhPhiTarBnk1 <-> outer port VeEEQR_r_ExhPhiTarBnk1
    delegate CPT_Cdd_Composition.VeCATR_T_CatTempBnk1 <-> outer port VeCATR_T_CatTempBnk1
    delegate CPT_Cdd_Composition.VeEPSR_Cnt_SyncnLostEve <-> outer port VeEPSR_Cnt_SyncnLostEve
    delegate CPT_IoSigAdc_SwSStellantisCmpstn.KeCFGR_b_MnfldGasTAdcInpEquid <-> outer port KeCFGR_b_MnfldGasTAdcInpEquid
    delegate CPT_IoSigPwmOutp_SwSStellantisCmpstn.VeDIOR_AlterFieCtrl_HwDiagFltOutp <-> outer port VeDIOR_AlterFieCtrl_HwDiagFltOutp
    delegate CPT_Cdd_Composition.VeLWRR_b_WRO2_RdyUsBnk1 <-> outer port VeLWRR_b_WRO2_RdyUsBnk1
    delegate CPT_IoSigAdc_SwSStellantisCmpstn.KeCFGR_b_PFIFuRailPressAdcInpEquid <-> outer port KeCFGR_b_PFIFuRailPressAdcInpEquid
    delegate CPT_IoSigDioInp_SwSStellantisCmpstn.KeCFGR_b_NVLDDigInpEquid <-> outer port KeCFGR_b_NVLDDigInpEquid
    delegate CPT_IoSigDioInp_SwSStellantisCmpstn.KeCFGR_b_StrtrRlyFbDigInpEquid <-> outer port KeCFGR_b_StrtrRlyFbDigInpEquid
    delegate CPT_Cdd_Composition.GetRPMR_b_EngStopd <-> outer port GetRPMR_b_EngStopd
    delegate CPT_IoSigHbrdg_SwSStellantisCmpstn.KeDIOR_b_DP_Equid <-> outer port KeDIOR_b_DP_Equid
    delegate CPT_Cdd_Composition.VeEXHR_T_UsCatTempBnk2 <-> outer port VeEXHR_T_UsCatTempBnk2
    delegate CPT_IoSigPwmInp_SwSStellantisCmpstn.VeDIOR_h_AllGrPosnSnsr1_PwmInp <-> outer port VeDIOR_h_AllGrPosnSnsr1_PwmInp
    delegate CPT_Cdd_Composition.VeOXSR_b_RdngRdyDsBnk1 <-> outer port VeOXSR_b_RdngRdyDsBnk1
    delegate CPT_IoSigDioInp_SwSStellantisCmpstn.VeDIOR_b_CluInterLockSwDigInpImdtVal <-> outer port VeDIOR_b_CluInterLockSwDigInpImdtVal
    delegate CPT_IoSigPwmOutp_SwSStellantisCmpstn.VeDIOR_HTR_MeclWtrPmpActr_HwDiagCmn <-> outer port VeDIOR_HTR_MeclWtrPmpActr_HwDiagCmn
    delegate CPT_Cdd_Composition.GetLLSR_b_IgnPinSts <-> outer port GetLLSR_b_IgnPinSts
    delegate CPT_Cdd_Composition.VeCAMR_b_ElecPhsrDirIntk1 <-> outer port VeCAMR_b_ElecPhsrDirIntk1
    delegate CPT_IoSigAdc_SwSStellantisCmpstn.KeCFGR_b_PedlValSnsr1AdcInpEquid <-> outer port KeCFGR_b_PedlValSnsr1AdcInpEquid
    delegate CPT_IoSigPwmInp_SwSStellantisCmpstn.VeDIOR_Pct_AllGrPosnSnsr1_PWM_Inp_DC <-> outer port VeDIOR_Pct_AllGrPosnSnsr1_PWM_Inp_DC
    delegate CPT_Cdd_Composition.VeCATR_T_CatTempBnk2 <-> outer port VeCATR_T_CatTempBnk2
    delegate CPT_IoSigAdc_SwSStellantisCmpstn.KeCFGR_b_AirCdngPSnsrAdcInpEquid <-> outer port KeCFGR_b_AirCdngPSnsrAdcInpEquid
    delegate CPT_IoSigPwmOutp_SwSStellantisCmpstn.KeCFGR_b_PurgSoln_ChEquid <-> outer port KeCFGR_b_PurgSoln_ChEquid
    delegate CPT_Cdd_Composition.VeEXHR_dm_ExhMassFlowBnk2 <-> outer port VeEXHR_dm_ExhMassFlowBnk2
    delegate CPT_IoSigAdc_SwSStellantisCmpstn.KeCFGR_b_OilShutOffValveFbAdcInpEquid <-> outer port KeCFGR_b_OilShutOffValveFbAdcInpEquid
    delegate CPT_Cdd_Composition.VeVSPR_v_VehSpd <-> outer port VeVSPR_v_VehSpd
    delegate CPT_Cdd_Composition.VeEXHR_T_UsCatTempBnk1 <-> outer port VeEXHR_T_UsCatTempBnk1
    delegate CPT_IoSigPwmInp_SwSStellantisCmpstn.VeDIOR_b_AllGrPosnSnsr2_PWM_Inp_TO_Sts <-> outer port VeDIOR_b_AllGrPosnSnsr2_PWM_Inp_TO_Sts
    delegate CPT_IoSigDioInp_SwSStellantisCmpstn.VeDIOR_t_CluInterLockSwDigInpOffTi <-> outer port VeDIOR_t_CluInterLockSwDigInpOffTi
    delegate CPT_Cdd_Composition.VeRPMR_b_SpdSnsrCohrncyFailr <-> outer port VeRPMR_b_SpdSnsrCohrncyFailr
    delegate CPT_IoSigHbrdg_SwSStellantisCmpstn.KeDIOR_b_Coold_EGR_Equid <-> outer port KeDIOR_b_Coold_EGR_Equid
    delegate CPT_IoSigPwmOutp_SwSStellantisCmpstn.VeDIOR_HTR_MeclWtrPmpActr_HwDiagFltCircDtctd <-> outer port VeDIOR_HTR_MeclWtrPmpActr_HwDiagFltCircDtctd
    delegate CPT_IoSigPwmOutp_SwSStellantisCmpstn.KeCFGR_b_RadrFanCtrlPwm_ChEquid <-> outer port KeCFGR_b_RadrFanCtrlPwm_ChEquid
    delegate CPT_Cdd_Composition.VeFSOR_b_EngInFullFSO <-> outer port VeFSOR_b_EngInFullFSO
    delegate CPT_IoSigAdc_SwSStellantisCmpstn.KeCFGR_b_CooltInletTempAdcInpEquid <-> outer port KeCFGR_b_CooltInletTempAdcInpEquid
    delegate CPT_IoSigAdc_SwSStellantisCmpstn.KeCFGR_b_LoPFuSnsrAdcInpEquid <-> outer port KeCFGR_b_LoPFuSnsrAdcInpEquid
    delegate CPT_Cdd_Composition.VeOXSR_U_FiltdOutpVoltDsBnk2 <-> outer port VeOXSR_U_FiltdOutpVoltDsBnk2
    delegate CPT_IoSigAdc_SwSStellantisCmpstn.KeCFGR_b_OilTSnsrAdcInpEquid <-> outer port KeCFGR_b_OilTSnsrAdcInpEquid
    delegate CPT_IoSigPwmOutp_SwSStellantisCmpstn.SetDIOR_e_AlterFieCtrlOutpOps <-> outer port SetDIOR_e_AlterFieCtrlOutpOps
    delegate CPT_IoSigAdc_SwSStellantisCmpstn.KeCFGR_b_ThrPosnSnsr1AdcInpEquid <-> outer port KeCFGR_b_ThrPosnSnsr1AdcInpEquid
    delegate CPT_IoSigAdc_SwSStellantisCmpstn.KeCFGR_b_CalInp1AdcInpEquid <-> outer port KeCFGR_b_CalInp1AdcInpEquid
    delegate CPT_Cdd_Composition.VeSSCR_t_TotEngLifeTiRunngTmr <-> outer port VeSSCR_t_TotEngLifeTiRunngTmr
    delegate CPT_Cdd_Composition.EeODMR_l_Servid_9TotDistLifeTi <-> outer port EeODMR_l_Servid_9TotDistLifeTi
    delegate CPT_Cdd_Composition.VeACRR_Pct_PdlPosn <-> outer port VeACRR_Pct_PdlPosn
    delegate CPT_IoSigHbrdg_SwSStellantisCmpstn.VeDIOR_h_Hbrdg_VarGeomTrb_Sts <-> outer port VeDIOR_h_Hbrdg_VarGeomTrb_Sts
    delegate CPT_IoSigHbrdg_SwSStellantisCmpstn.VeDIOR_b_Hbrdg_VarGeomTrb_DiagFltCircDtctd <-> outer port VeDIOR_b_Hbrdg_VarGeomTrb_DiagFltCircDtctd
    delegate CPT_IoSigHbrdg_SwSStellantisCmpstn.ServDIOR_Hbrdg_VarGeomTrb <-> outer port ServDIOR_Hbrdg_VarGeomTrb
    delegate CPT_IoSigHbrdg_SwSStellantisCmpstn.VeDIOR_b_Hbrdg_VarGeomTrb_DiagCmn <-> outer port VeDIOR_b_Hbrdg_VarGeomTrb_DiagCmn
    delegate CPT_IoSigHbrdg_SwSStellantisCmpstn.VeDIOR_b_Hbrdg_VarGeomTrb_DiagFltOutp <-> outer port VeDIOR_b_Hbrdg_VarGeomTrb_DiagFltOutp
    delegate CPT_IoSigHbrdg_SwSStellantisCmpstn.VeDIOR_b_Hbrdg_VarGeomTrb_DiagFltCircDftlDtctd <-> outer port VeDIOR_b_Hbrdg_VarGeomTrb_DiagFltCircDftlDtctd
    delegate CPT_IoSigDioOutp_SwSStellantisCmpstn.VeDIOR_SwilEngMnt2_HwDiagFltCircDtctd <-> outer port VeDIOR_SwilEngMnt2_HwDiagFltCircDtctd
    delegate CPT_IoSigDioOutp_SwSStellantisCmpstn.VeDIOR_SwilEngMnt2_HwDiagFltOutp <-> outer port VeDIOR_SwilEngMnt2_HwDiagFltOutp
    delegate CPT_IoSigDioOutp_SwSStellantisCmpstn.VeDIOR_SwilEngMnt2_HwDiagCmn <-> outer port VeDIOR_SwilEngMnt2_HwDiagCmn
    delegate CPT_SWC_VcodProxi.Pp_BasSvrAppl_stEOLNode105Pres <-> outer port Pp_BasSvrAppl_stEOLNode105Pres
    delegate CPT_SWC_VcodProxi.Pp_BasSvrAppl_stEOLNode94Pres <-> outer port Pp_BasSvrAppl_stEOLNode94Pres
    delegate CPT_SWC_VcodProxi.Pp_DcmDspUDS_stHillDscntCtrl <-> outer port Pp_DcmDspUDS_stHillDscntCtrl
    delegate CPT_SWC_VcodProxi.Pp_BasSvrAppl_stEOLNode75Pres <-> outer port Pp_BasSvrAppl_stEOLNode75Pres
    delegate CPT_SWC_VcodProxi.Pp_BasSvrAppl_stbsm_fnct_1hdc <-> outer port Pp_BasSvrAppl_stbsm_fnct_1hdc
    delegate CPT_SWC_VcodProxi.Pp_BasSvrAppl_stASCMPrsnt <-> outer port Pp_BasSvrAppl_stASCMPrsnt
    delegate CPT_SWC_VcodProxi.Pp_BasSvrAppl_stDTCMPrsnt <-> outer port Pp_BasSvrAppl_stDTCMPrsnt
    delegate CPT_SWC_VcodProxi.Pp_BasSvrAppl_stCANNode6Pres <-> outer port Pp_BasSvrAppl_stCANNode6Pres
    delegate CPT_SWC_VcodProxi.Pp_BasSvrAppl_stCANNode11Pres <-> outer port Pp_BasSvrAppl_stCANNode11Pres
    delegate CPT_SWC_VcodProxi.Pp_BasSvrAppl_stEOLNode10Pres <-> outer port Pp_BasSvrAppl_stEOLNode10Pres
    delegate CPT_SWC_VcodProxi.Pp_BasSvrAppl_stEngType <-> outer port Pp_BasSvrAppl_stEngType
    delegate CPT_SWC_VcodProxi.Pp_BasSvrAppl_stPAMCfg <-> outer port Pp_BasSvrAppl_stPAMCfg
    delegate CPT_SWC_VcodProxi.Pp_BasSvrAppl_st4LoBtn <-> outer port Pp_BasSvrAppl_st4LoBtn
    delegate CPT_SWC_VcodProxi.Pp_BasSvrAppl_stEOLNode17Pres <-> outer port Pp_BasSvrAppl_stEOLNode17Pres
    delegate CPT_SWC_VcodProxi.Pp_BasSvrAppl_stCANNode65Pres <-> outer port Pp_BasSvrAppl_stCANNode65Pres
    delegate CPT_SWC_VcodProxi.Pp_BasSvrAppl_stVehLineConf <-> outer port Pp_BasSvrAppl_stVehLineConf
    delegate CPT_SWC_VcodProxi.Pp_BasSvrAppl_stEOLNode27Pres <-> outer port Pp_BasSvrAppl_stEOLNode27Pres
    delegate CPT_SWC_VcodProxi.Pp_DcmDspUDS_stTachoFiltgTyp <-> outer port Pp_DcmDspUDS_stTachoFiltgTyp
    delegate CPT_SWC_VcodProxi.Pp_DcmDspUDS_stCANNod24Pres <-> outer port Pp_DcmDspUDS_stCANNod24Pres
    delegate CPT_SWC_VcodProxi.Pp_BasSvrAppl_stNrOfDoor <-> outer port Pp_BasSvrAppl_stNrOfDoor
    delegate CPT_SWC_VcodProxi.Pp_BasSvrAppl_stgGearBox <-> outer port Pp_BasSvrAppl_stgGearBox
    delegate CPT_SWC_VcodProxi.Pp_DcmDspUds_stSelSpdCtrlFeat <-> outer port Pp_DcmDspUds_stSelSpdCtrlFeat
    delegate CPT_SWC_VcodProxi.Pp_BasSvrAppl_stIgnPreStrtLogic <-> outer port Pp_BasSvrAppl_stIgnPreStrtLogic
    delegate CPT_SWC_VcodProxi.Pp_BasSvrAppl_stEOLNode126Pres <-> outer port Pp_BasSvrAppl_stEOLNode126Pres
    delegate CPT_SWC_VcodProxi.Pp_BasSvrAppl_stRemoteStart <-> outer port Pp_BasSvrAppl_stRemoteStart
    delegate CPT_SWC_VcodProxi.Pp_BasSvrAppl_stEOLNode98Pres <-> outer port Pp_BasSvrAppl_stEOLNode98Pres
    delegate CPT_SWC_VcodProxi.Pp_DcmDspUDS_stProxiConfigCodeTstrVal <-> outer port Pp_DcmDspUDS_stProxiConfigCodeTstrVal
    delegate CPT_SWC_VcodProxi.Pp_BasSvrAppl_stDrvStyleSel <-> outer port Pp_BasSvrAppl_stDrvStyleSel
    delegate CPT_SWC_VcodProxi.Pp_BasSvrAppl_stEOLNode95Pres <-> outer port Pp_BasSvrAppl_stEOLNode95Pres
    delegate CPT_SWC_VcodProxi.Pp_BasSvrAppl_stStpStrtlPres <-> outer port Pp_BasSvrAppl_stStpStrtlPres
    delegate CPT_SWC_VcodProxi.Pp_BasSvrAppl_stGearBoxTyp <-> outer port Pp_BasSvrAppl_stGearBoxTyp
    delegate CPT_SWC_VcodProxi.Pp_BasSvrAppl_stCANNode3Pres <-> outer port Pp_BasSvrAppl_stCANNode3Pres
    delegate CPT_SWC_VcodProxi.Pp_BasSvrAppl_stEOLNode74Pres <-> outer port Pp_BasSvrAppl_stEOLNode74Pres
    delegate CPT_SWC_VcodProxi.Pp_BasSvrAppl_stEOLNode70Pres <-> outer port Pp_BasSvrAppl_stEOLNode70Pres
    delegate CPT_SWC_VcodProxi.Pp_BasSvrAppl_stEOLNode63Pres <-> outer port Pp_BasSvrAppl_stEOLNode63Pres
    delegate CPT_SWC_VcodProxi.Pp_BasSvrAppl_stEOLNode79Pres <-> outer port Pp_BasSvrAppl_stEOLNode79Pres
    delegate CPT_SWC_VcodProxi.Pp_BasSvrAppl_stEOLNode29Pres <-> outer port Pp_BasSvrAppl_stEOLNode29Pres
    delegate CPT_SWC_VcodProxi.Pp_BasSvrAppl_stProxiTesterCode <-> outer port Pp_BasSvrAppl_stProxiTesterCode
    delegate CPT_SWC_VcodProxi.Pp_BasSvrAppl_stEOLNode36Pres <-> outer port Pp_BasSvrAppl_stEOLNode36Pres
    delegate CPT_SWC_VcodProxi.Pp_BasSvrAppl_stEOLNode112Pres <-> outer port Pp_BasSvrAppl_stEOLNode112Pres
    delegate CPT_SWC_VcodProxi.Pp_BasSvrAppl_CrsCtlLogic <-> outer port Pp_BasSvrAppl_CrsCtlLogic
    delegate CPT_SWC_VcodProxi.Pp_BasSvrAppl_stEOLNode69Pres <-> outer port Pp_BasSvrAppl_stEOLNode69Pres
    delegate CPT_SWC_VcodProxi.Pp_BasSvrAppl_stAdapCrCtl <-> outer port Pp_BasSvrAppl_stAdapCrCtl
    delegate CPT_SWC_VcodProxi.Pp_BasSvrAppl_stEOLNode84Pres <-> outer port Pp_BasSvrAppl_stEOLNode84Pres
    delegate CPT_SWC_VcodProxi.Pp_DcmDspUDS_stFOTATyp <-> outer port Pp_DcmDspUDS_stFOTATyp
    delegate CPT_SWC_VcodProxi.Pp_BasSvrAppl_stSRT <-> outer port Pp_BasSvrAppl_stSRT
    delegate CPT_SWC_VcodProxi.Pp_BasSvrAppl_stCrCtlPres <-> outer port Pp_BasSvrAppl_stCrCtlPres
    delegate CPT_SWC_VcodProxi.Pp_BasSvrAppl_stCtyCode <-> outer port Pp_BasSvrAppl_stCtyCode
    delegate CPT_SWC_VcodProxi.Pp_BasSvrAppl_stProxiProductionDate <-> outer port Pp_BasSvrAppl_stProxiProductionDate
    delegate CPT_SWC_VcodProxi.Pp_BasSvrAppl_stEOLNode53Pres <-> outer port Pp_BasSvrAppl_stEOLNode53Pres
    delegate CPT_SWC_VcodProxi.Pp_BasSvrAppl_stEOLNode96Pres <-> outer port Pp_BasSvrAppl_stEOLNode96Pres
    delegate CPT_SWC_VcodProxi.Pp_BasSvrAppl_stAntiInclSens <-> outer port Pp_BasSvrAppl_stAntiInclSens
    delegate CPT_SWC_VcodProxi.Pp_BasSvrAppl_stEOLNode31Pres <-> outer port Pp_BasSvrAppl_stEOLNode31Pres
    delegate CPT_SWC_VcodProxi.Pp_BasSvrAppl_lTire <-> outer port Pp_BasSvrAppl_lTire
    delegate CPT_SWC_VcodProxi.Pp_BasSvrAppl_stCANNode53Pres <-> outer port Pp_BasSvrAppl_stCANNode53Pres
    delegate CPT_SWC_VcodProxi.Pp_BasSvrAppl_stCANNode1Pres <-> outer port Pp_BasSvrAppl_stCANNode1Pres
    delegate CPT_SWC_VcodProxi.Pp_BasSvrAppl_stGearBoxVarTyp <-> outer port Pp_BasSvrAppl_stGearBoxVarTyp
    delegate CPT_SWC_VcodProxi.Pp_BasSvrAppl_stEOLNode67Pres <-> outer port Pp_BasSvrAppl_stEOLNode67Pres
    delegate CPT_SWC_VcodProxi.Pp_BasSvrAppl_stEOLNode24Pres <-> outer port Pp_BasSvrAppl_stEOLNode24Pres
    delegate CPT_SWC_VcodProxi.Pp_BasSvrAppl_stEOLNode8Pres <-> outer port Pp_BasSvrAppl_stEOLNode8Pres
    delegate CPT_SWC_VcodProxi.Pp_BasSvrAppl_stEOLNode1Pres <-> outer port Pp_BasSvrAppl_stEOLNode1Pres
    delegate CPT_SWC_VcodProxi.Pp_DcmDspUDS_stTSR <-> outer port Pp_DcmDspUDS_stTSR
    delegate CPT_SWC_VcodProxi.Pp_BasSvrAppl_stShftrTypeVar <-> outer port Pp_BasSvrAppl_stShftrTypeVar
    delegate CPT_SWC_VcodProxi.Pp_BasSvrAppl_stCANNode26Pres <-> outer port Pp_BasSvrAppl_stCANNode26Pres
    delegate CPT_SWC_VcodProxi.Pp_BasSvrAppl_stDriverSide <-> outer port Pp_BasSvrAppl_stDriverSide
    delegate CPT_SWC_VcodProxi.Pp_BasSvrAppl_stEOLNode3Pres <-> outer port Pp_BasSvrAppl_stEOLNode3Pres
    delegate CPT_SWC_VcodProxi.Pp_BasSvrAppl_stCANNod0Pres <-> outer port Pp_BasSvrAppl_stCANNod0Pres
    delegate CPT_SWC_VcodProxi.Pp_BasSvrAppl_stEOLNode119Pres <-> outer port Pp_BasSvrAppl_stEOLNode119Pres
    delegate CPT_SWC_VcodProxi.Pp_BasSvrAppl_stCANNode124Pres <-> outer port Pp_BasSvrAppl_stCANNode124Pres
    delegate CPT_SWC_VcodProxi.Pp_BasSvrAppl_stEOLNode127Pres <-> outer port Pp_BasSvrAppl_stEOLNode127Pres
    delegate CPT_SWC_VcodProxi.Pp_BasSvrAppl_stPtlAutPrkgSys <-> outer port Pp_BasSvrAppl_stPtlAutPrkgSys
    delegate CPT_SWC_VcodProxi.Pp_BasSvrAppl_stCANNode22Pres <-> outer port Pp_BasSvrAppl_stCANNode22Pres
    delegate CPT_SWC_VcodProxi.Pp_DcmDspUDS_stTrlrRvsSteerPres <-> outer port Pp_DcmDspUDS_stTrlrRvsSteerPres
    delegate CPT_SWC_VcodProxi.Pp_BasSvrAppl_stEOLNode26Pres <-> outer port Pp_BasSvrAppl_stEOLNode26Pres
    delegate CPT_SWC_VcodProxi.Pp_DcmDspUDS_stIncrSpdConst <-> outer port Pp_DcmDspUDS_stIncrSpdConst
    delegate CPT_SWC_VcodProxi.Pp_BasSvrAppl_stEOLNode46Pres <-> outer port Pp_BasSvrAppl_stEOLNode46Pres
    delegate CPT_SWC_VcodProxi.Pp_BasSvrAppl_stEOLNode91Pres <-> outer port Pp_BasSvrAppl_stEOLNode91Pres
    delegate CPT_SWC_VcodProxi.Pp_BasSvrAppl_stEOLNode90Pres <-> outer port Pp_BasSvrAppl_stEOLNode90Pres
    delegate CPT_SWC_VcodProxi.Pp_BasSvrAppl_stEOLNode93Pres <-> outer port Pp_BasSvrAppl_stEOLNode93Pres
    delegate CPT_SWC_VcodProxi.Pp_BasSvrAppl_stCANNode2Pres <-> outer port Pp_BasSvrAppl_stCANNode2Pres
    delegate CPT_SWC_VcodProxi.Pp_BasSvrAppl_stCANNode13Pres <-> outer port Pp_BasSvrAppl_stCANNode13Pres
    delegate CPT_SWC_VcodProxi.Pp_BasSvrAppl_stFuelType <-> outer port Pp_BasSvrAppl_stFuelType
    delegate CPT_SWC_VcodProxi.Pp_BasSvrAppl_stEOLNode120Pres <-> outer port Pp_BasSvrAppl_stEOLNode120Pres
    delegate CPT_SWC_VcodProxi.Pp_BasSvrAppl_stKeylsGo <-> outer port Pp_BasSvrAppl_stKeylsGo
    delegate CPT_SWC_VcodProxi.Pp_BasSvrAppl_stTHRat <-> outer port Pp_BasSvrAppl_stTHRat
    delegate CPT_SWC_VcodProxi.Pp_BasSvrAppl_stDrvModes <-> outer port Pp_BasSvrAppl_stDrvModes
    delegate CPT_SWC_VcodProxi.Pp_DcmDspUDS_stTrlrHitchAssiPres <-> outer port Pp_DcmDspUDS_stTrlrHitchAssiPres
    delegate CPT_SWC_VcodProxi.Pp_BasSvrAppl_stEOLNode124Pres <-> outer port Pp_BasSvrAppl_stEOLNode124Pres
    delegate CPT_SWC_VcodProxi.Pp_BasSvrAppl_stSAMPres <-> outer port Pp_BasSvrAppl_stSAMPres
    delegate CPT_SWC_VcodProxi.Pp_BasSvrAppl_stEOLNode83Pres <-> outer port Pp_BasSvrAppl_stEOLNode83Pres
    delegate CPT_SWC_VcodProxi.Pp_BasSvrAppl_stAdvdDrvrProgBtn <-> outer port Pp_BasSvrAppl_stAdvdDrvrProgBtn
    delegate CPT_SWC_VcodProxi.Pp_BasSvrAppl_stProxiConfigCode <-> outer port Pp_BasSvrAppl_stProxiConfigCode
    delegate CPT_SWC_VcodProxi.Pp_BasSvrAppl_stEOLNode6Pres <-> outer port Pp_BasSvrAppl_stEOLNode6Pres
    delegate CPT_SWC_VcodProxi.Pp_BasSvrAppl_stEOLNode0Pres <-> outer port Pp_BasSvrAppl_stEOLNode0Pres
    delegate CPT_SWC_VcodProxi.Pp_BasSvrAppl_stEOLNode2Pres <-> outer port Pp_BasSvrAppl_stEOLNode2Pres
    delegate CPT_SWC_VcodProxi.Pp_BasSvrAppl_stTrrnSelMode <-> outer port Pp_BasSvrAppl_stTrrnSelMode
    delegate CPT_SWC_VcodProxi.Pp_BasSvrAppl_stHybridType <-> outer port Pp_BasSvrAppl_stHybridType
    delegate CPT_SWC_VcodProxi.Pp_BasSvrAppl_stEOLNode97Pres <-> outer port Pp_BasSvrAppl_stEOLNode97Pres
    delegate CPT_SWC_VcodProxi.Pp_BasSvrAppl_stEOLNode61Pres <-> outer port Pp_BasSvrAppl_stEOLNode61Pres
    delegate CPT_SWC_VcodProxi.Pp_DcmDspUDS_ratSpdMtrTolr <-> outer port Pp_DcmDspUDS_ratSpdMtrTolr
    delegate CPT_SWC_VcodProxi.Pp_BasSvrAppl_AutonomyLvl <-> outer port Pp_BasSvrAppl_AutonomyLvl
    delegate CPT_SWC_VcodProxi.Pp_DcmDspUDS_stDrvTrnVar <-> outer port Pp_DcmDspUDS_stDrvTrnVar
    delegate CPT_SWC_VcodProxi.Pp_BasSvrAppl_stGearShiftIdctr <-> outer port Pp_BasSvrAppl_stGearShiftIdctr
    delegate CPT_SWC_VcodProxi.Pp_BasSvrAppl_stCANNode10Pres <-> outer port Pp_BasSvrAppl_stCANNode10Pres
    delegate CPT_SWC_VcodProxi.Pp_BasSvrAppl_stClimateTyp <-> outer port Pp_BasSvrAppl_stClimateTyp
    delegate CPT_SWC_VcodProxi.Pp_DcmDspUDS_rTCaseLow <-> outer port Pp_DcmDspUDS_rTCaseLow
    delegate CPT_SWC_VcodProxi.Pp_BasSvrAppl_stEOLNode18Pres <-> outer port Pp_BasSvrAppl_stEOLNode18Pres
    delegate CPT_SWC_VcodProxi.Pp_BasSvrAppl_stAxlRat <-> outer port Pp_BasSvrAppl_stAxlRat
    delegate CPT_SWC_VcodProxi.Pp_BasSvrAppl_stEOLNode11Pres <-> outer port Pp_BasSvrAppl_stEOLNode11Pres
    delegate CPT_SWC_VcodProxi.Pp_BasSvrAppl_stCANNode57Pres <-> outer port Pp_BasSvrAppl_stCANNode57Pres
    delegate CPT_SWC_VcodProxi.Pp_BasSvrAppl_stEOLNode22Pres <-> outer port Pp_BasSvrAppl_stEOLNode22Pres
    delegate CPT_SWC_VcodProxi.Pp_BasSvrAppl_stEOLNode60Pres <-> outer port Pp_BasSvrAppl_stEOLNode60Pres
    delegate CPT_SWC_VcodProxi.Pp_DcmDspUDS_stLLimPres <-> outer port Pp_DcmDspUDS_stLLimPres
    delegate CPT_SWC_VcodProxi.Pp_BasSvrAppl_stEOLNode62Pres <-> outer port Pp_BasSvrAppl_stEOLNode62Pres
    delegate CPT_SWC_VcodProxi.Pp_BasSvrAppl_stEOLNode65Pres <-> outer port Pp_BasSvrAppl_stEOLNode65Pres
    delegate CPT_SWC_VcodProxi.Pp_BasSvrApl_stCarShpConf <-> outer port Pp_BasSvrApl_stCarShpConf
    delegate CPT_SWC_VcodProxi.Pp_BasSvrAppl_stEOLNode23Pres <-> outer port Pp_BasSvrAppl_stEOLNode23Pres
    delegate CPT_SWC_VcodProxi.Pp_BasSvrAppl_stPrkBrkSysVar <-> outer port Pp_BasSvrAppl_stPrkBrkSysVar
    delegate CPT_SWC_VcodProxi.Pp_BasSvrAppl_stEOLNode78Pres <-> outer port Pp_BasSvrAppl_stEOLNode78Pres
    delegate CPT_SWC_VcodProxi.Pp_BasSvrAppl_stEOLNode50Pres <-> outer port Pp_BasSvrAppl_stEOLNode50Pres
    delegate CPT_SWC_VcodProxi.Pp_DcmDspUDS_stMdlYr <-> outer port Pp_DcmDspUDS_stMdlYr
    delegate CPT_SWC_VcodProxi.Pp_BasSvrAppl_stEOLNode7Pres <-> outer port Pp_BasSvrAppl_stEOLNode7Pres
    delegate CPT_SWC_VcodProxi.Pp_BasSvrAppl_stEOLNode35Pres <-> outer port Pp_BasSvrAppl_stEOLNode35Pres
    delegate CPT_IoSigPwmInp_SwSStellantisCmpstn.VeDIOR_b_OilLvlSnsr_PWM_Inp_TO_Sts <-> outer port VeDIOR_b_OilLvlSnsr_PWM_Inp_TO_Sts
    delegate CPT_IoSigPwmInp_SwSStellantisCmpstn.KeCFGR_b_ElecPhsrDiag_ChEquid <-> outer port KeCFGR_b_ElecPhsrDiag_ChEquid
    delegate CPT_IoSigPwmInp_SwSStellantisCmpstn.VeDIOR_h_ElecPhsrDiag_PwmInp <-> outer port VeDIOR_h_ElecPhsrDiag_PwmInp
    delegate CPT_IoSigPwmInp_SwSStellantisCmpstn.VeDIOR_b_ElecPhsrDiag_PWM_Inp_TO_Sts <-> outer port VeDIOR_b_ElecPhsrDiag_PWM_Inp_TO_Sts
    delegate CPT_IoSigPwmInp_SwSStellantisCmpstn.VeDIOR_Pct_ElecPhsrDiag_PWM_Inp_DC <-> outer port VeDIOR_Pct_ElecPhsrDiag_PWM_Inp_DC
    delegate CPT_IoSigPwmInp_SwSStellantisCmpstn.VeDIOR_Pct_OilLvlSnsr_PWM_Inp_DC <-> outer port VeDIOR_Pct_OilLvlSnsr_PWM_Inp_DC
    delegate CPT_IoSigPwmInp_SwSStellantisCmpstn.VeDIOR_h_OilLvlSnsr_PwmInp <-> outer port VeDIOR_h_OilLvlSnsr_PwmInp
    delegate CPT_Cdd_Composition.KeCFGR_b_SwKnkCddCh2Equid <-> outer port KeCFGR_b_SwKnkCddCh2Equid
    delegate CPT_Cdd_Composition.KeCFGR_b_SwKnkCddCh3Equid <-> outer port KeCFGR_b_SwKnkCddCh3Equid
    delegate CPT_Cdd_Composition.KeCFGR_b_SwKnkCddCh1Equid <-> outer port KeCFGR_b_SwKnkCddCh1Equid
    delegate CPT_IoSigDioOutp_SwSStellantisCmpstn.KeCFGR_b_DMTLLkPmp_ChEquid <-> outer port KeCFGR_b_DMTLLkPmp_ChEquid
    delegate CPT_IoSigDioOutp_SwSStellantisCmpstn.KeCFGR_b_VapBlockingVlv_ChEquid <-> outer port KeCFGR_b_VapBlockingVlv_ChEquid
    delegate CPT_IoSigPwmInp_SwSStellantisCmpstn.KeCFGR_b_FPCMFb1_ChEquid <-> outer port KeCFGR_b_FPCMFb1_ChEquid
    delegate CPT_IoSigDioOutp_SwSStellantisCmpstn.KeCFGR_b_AC_CluRly_ChEquid <-> outer port KeCFGR_b_AC_CluRly_ChEquid
    delegate CPT_IoSigDioOutp_SwSStellantisCmpstn.KeCFGR_b_SrgSoln1_ChEquid <-> outer port KeCFGR_b_SrgSoln1_ChEquid
    delegate CPT_IoSigDioOutp_SwSStellantisCmpstn.KeCFGR_b_SwilEngMnt2_ChEquid <-> outer port KeCFGR_b_SwilEngMnt2_ChEquid
    delegate CPT_IoSigDioOutp_SwSStellantisCmpstn.KeCFGR_b_LoPresFuPmpRly_ChEquid <-> outer port KeCFGR_b_LoPresFuPmpRly_ChEquid
    delegate CPT_IoSigDioOutp_SwSStellantisCmpstn.KeCFGR_b_StrtrRly_ChEquid <-> outer port KeCFGR_b_StrtrRly_ChEquid
    delegate CPT_IoSigDioOutp_SwSStellantisCmpstn.KeCFGR_b_OBD_PurgVentVlv_ChEquid <-> outer port KeCFGR_b_OBD_PurgVentVlv_ChEquid
    delegate CPT_IoSigDioOutp_SwSStellantisCmpstn.KeCFGR_b_SwilEngMnt1_ChEquid <-> outer port KeCFGR_b_SwilEngMnt1_ChEquid
    delegate CPT_IoSigDioOutp_SwSStellantisCmpstn.KeCFGR_b_InrushCircRly_ChEquid <-> outer port KeCFGR_b_InrushCircRly_ChEquid
    delegate CPT_IoSigPwmInp_SwSStellantisCmpstn.KeCFGR_b_OilLvlSnsr_ChEquid <-> outer port KeCFGR_b_OilLvlSnsr_ChEquid
    connect CPT_rbf_SftyHw_ShtOffPahPwrStg.PP_rbf_SftyHw_ShtOffPahPwrStg -> CPT_rbf_SftyHw_ErrMngtModl.RP_GetShtOffPathState_client1
    connect CPT_rbf_SftyHw_ShtOffPahPwrStg.PP_rbf_SftyHw_ShtOffPahPwrStg -> CPT_rbf_SftyHw_ErrMngtModl.RP_GetShtOffPathState_client2
    delegate CPT_IoSigHbrdg_SwSStellantisCmpstn.VeDIOR_b_Hbrdg_ETC_Motor_DiagFltOutp <-> outer port VeDIOR_b_Hbrdg_ETC_Motor_DiagFltOutp
    delegate CPT_IoSigDioOutp_SwSStellantisCmpstn.VeDIOR_OilShutOffVlv_HwDiagFltCircDtctd <-> outer port VeDIOR_OilShutOffVlv_HwDiagFltCircDtctd
    delegate CPT_IoSigDioOutp_SwSStellantisCmpstn.VeDIOR_e_SecdAirShutOffSoln1IndDiagInfo <-> outer port VeDIOR_e_SecdAirShutOffSoln1IndDiagInfo
    delegate CPT_IoSigDioOutp_SwSStellantisCmpstn.VeDIOR_e_VapBlockingVlvIndDiagInfo <-> outer port VeDIOR_e_VapBlockingVlvIndDiagInfo
    delegate CPT_IoSigAdc_SwSStellantisCmpstn.VeADCR_U_FiveVoltSns <-> outer port VeADCR_U_FiveVoltSns
    delegate CPT_IoSigDioOutp_SwSStellantisCmpstn.KeCFGR_b_ElectcVacPmpRly_ChEquid <-> outer port KeCFGR_b_ElectcVacPmpRly_ChEquid
    delegate CPT_IoSigDioOutp_SwSStellantisCmpstn.KeCFGR_b_OilShutOffVlv_ChEquid <-> outer port KeCFGR_b_OilShutOffVlv_ChEquid
    delegate CPT_IoSigDioOutp_SwSStellantisCmpstn.SetDIOR_b_SecdAirPmpRlyOutpSt <-> outer port SetDIOR_b_SecdAirPmpRlyOutpSt
    delegate CPT_IoSigDioOutp_SwSStellantisCmpstn.VeDIOR_MakeUpAirVlv_HwDiagFltCircDtctd <-> outer port VeDIOR_MakeUpAirVlv_HwDiagFltCircDtctd
    delegate CPT_IoSigDioOutp_SwSStellantisCmpstn.VeDIOR_VapBlockingVlv_HwDiagCmn <-> outer port VeDIOR_VapBlockingVlv_HwDiagCmn
    delegate CPT_IoSigDioOutp_SwSStellantisCmpstn.VeDIOR_SecdAirPmpRly_HwDiagFltOutp <-> outer port VeDIOR_SecdAirPmpRly_HwDiagFltOutp
    delegate CPT_IoSigDioOutp_SwSStellantisCmpstn.KeCFGR_b_SecdAirShutOffSoln1_ChEquid <-> outer port KeCFGR_b_SecdAirShutOffSoln1_ChEquid
    delegate CPT_IoSigAdc_SwSStellantisCmpstn.FiveVoltOutp <-> outer port FiveVoltOutp
    delegate CPT_IoSigAdc_SwSStellantisCmpstn.VeADCR_U_FiveVoltAux <-> outer port VeADCR_U_FiveVoltAux
    delegate CPT_IoSigHbrdg_SwSStellantisCmpstn.VeDIOR_b_Hbrdg_Wg1_DiagFltOutp <-> outer port VeDIOR_b_Hbrdg_Wg1_DiagFltOutp
    delegate CPT_IoSigAdc_SwSStellantisCmpstn.KeCFGR_b_FiveVoltOutpAdcInpEquid <-> outer port KeCFGR_b_FiveVoltOutpAdcInpEquid
    delegate CPT_IoSigDioOutp_SwSStellantisCmpstn.SetDIOR_b_SecdAirShutOffSoln1OutpSt <-> outer port SetDIOR_b_SecdAirShutOffSoln1OutpSt
    delegate CPT_IoSigDioInp_SwSStellantisCmpstn.VeDIOR_t_DynoFuDsblReqSwDigInpOffTi <-> outer port VeDIOR_t_DynoFuDsblReqSwDigInpOffTi
    delegate CPT_IoSigDioOutp_SwSStellantisCmpstn.VeDIOR_SecdAirPmpRly_HwDiagCmn <-> outer port VeDIOR_SecdAirPmpRly_HwDiagCmn
    delegate CPT_IoSigDioOutp_SwSStellantisCmpstn.VeDIOR_SecdAirPmpRly_HwDiagFltCircDtctd <-> outer port VeDIOR_SecdAirPmpRly_HwDiagFltCircDtctd
    delegate CPT_Cdd_Composition.GetDIOR_b_IgnRunStrtSwFiltdVal <-> outer port GetDIOR_b_IgnRunStrtSwFiltdVal
    delegate CPT_IoSigHbrdg_SwSStellantisCmpstn.VeDIOR_b_Hbrdg_Coold_EGR_DiagFltOutp <-> outer port VeDIOR_b_Hbrdg_Coold_EGR_DiagFltOutp
    delegate CPT_IoSigDioOutp_SwSStellantisCmpstn.VeDIOR_MakeUpAirVlv_HwDiagFltOutp <-> outer port VeDIOR_MakeUpAirVlv_HwDiagFltOutp
    delegate CPT_IoSigAdc_SwSStellantisCmpstn.KeCFGR_b_FiveVoltSnsAdcInpEquid <-> outer port KeCFGR_b_FiveVoltSnsAdcInpEquid
    delegate CPT_IoSigDioOutp_SwSStellantisCmpstn.VeDIOR_ElectcVacPmpRly_HwDiagCmn <-> outer port VeDIOR_ElectcVacPmpRly_HwDiagCmn
    delegate CPT_Cdd_Composition.VeFLVR_Pct_FuLvlSca <-> outer port VeFLVR_Pct_FuLvlSca
    delegate CPT_IoSigDioOutp_SwSStellantisCmpstn.VeDIOR_ElectcVacPmpRly_HwDiagFltCircDtctd <-> outer port VeDIOR_ElectcVacPmpRly_HwDiagFltCircDtctd
    delegate CPT_IoSigDioOutp_SwSStellantisCmpstn.VeDIOR_MakeUpAirVlv_HwDiagCmn <-> outer port VeDIOR_MakeUpAirVlv_HwDiagCmn
    delegate CPT_IoSigHbrdg_SwSStellantisCmpstn.VeDIOR_b_Hbrdg_ETC_Motor_DiagFltCircDftlDtctd <-> outer port VeDIOR_b_Hbrdg_ETC_Motor_DiagFltCircDftlDtctd
    delegate CPT_IoSigDioOutp_SwSStellantisCmpstn.SetDIOR_b_OilShutOffVlvOutpSt <-> outer port SetDIOR_b_OilShutOffVlvOutpSt
    delegate CPT_IoSigDioInp_SwSStellantisCmpstn.VeDIOR_t_StrtrRlyFbDigInpOffTi <-> outer port VeDIOR_t_StrtrRlyFbDigInpOffTi
    delegate CPT_IoSigHbrdg_SwSStellantisCmpstn.VeDIOR_b_Hbrdg_Wg1_DiagCmn <-> outer port VeDIOR_b_Hbrdg_Wg1_DiagCmn
    delegate CPT_IoSigPwmInp_SwSStellantisCmpstn.VeDIOR_t_OilLvlSnsr_PWM_Inp_PrdPW_Cohrnt <-> outer port VeDIOR_t_OilLvlSnsr_PWM_Inp_PrdPW_Cohrnt
    delegate CPT_IoSigHbrdg_SwSStellantisCmpstn.VeDIOR_b_Hbrdg_Coold_EGR_DiagFltCircDftlDtctd <-> outer port VeDIOR_b_Hbrdg_Coold_EGR_DiagFltCircDftlDtctd
    delegate CPT_IoSigIfAdapt_SwSStellantisCmpstn.VeSPLR_b_MdulIdVld <-> outer port VeSPLR_b_MdulIdVld
    delegate CPT_IoSigAdc_SwSStellantisCmpstn.VeADCR_U_FiveVoltOutp <-> outer port VeADCR_U_FiveVoltOutp
    delegate CPT_IoSigHbrdg_SwSStellantisCmpstn.VeDIOR_b_Hbrdg_ETC_Motor_DiagCmn <-> outer port VeDIOR_b_Hbrdg_ETC_Motor_DiagCmn
    delegate CPT_IoSigDioOutp_SwSStellantisCmpstn.KeCFGR_b_MakeUpAirVlv_ChEquid <-> outer port KeCFGR_b_MakeUpAirVlv_ChEquid
    delegate CPT_IoSigDioInp_SwSStellantisCmpstn.VeDIOR_t_NVLD_SwDigInpOffTi <-> outer port VeDIOR_t_NVLD_SwDigInpOffTi
    delegate CPT_IoSigDioOutp_SwSStellantisCmpstn.VeDIOR_VapBlockingVlv_HwDiagFltCircDtctd <-> outer port VeDIOR_VapBlockingVlv_HwDiagFltCircDtctd
    delegate CPT_Cdd_Composition.VeDMRR_g_EnblCondSts <-> outer port VeDMRR_g_EnblCondSts
    delegate CPT_IoSigHbrdg_SwSStellantisCmpstn.VeDIOR_b_Hbrdg_Coold_EGR_DiagCmn <-> outer port VeDIOR_b_Hbrdg_Coold_EGR_DiagCmn
    delegate CPT_IoSigDioOutp_SwSStellantisCmpstn.VeDIOR_SecdAirShutOffSoln1_HwDiagCmn <-> outer port VeDIOR_SecdAirShutOffSoln1_HwDiagCmn
    delegate CPT_IoSigDioOutp_SwSStellantisCmpstn.VeDIOR_ElectcVacPmpRly_HwDiagFltOutp <-> outer port VeDIOR_ElectcVacPmpRly_HwDiagFltOutp
    delegate CPT_IoSigAdc_SwSStellantisCmpstn.FiveVoltSns <-> outer port FiveVoltSns
    delegate CPT_Cdd_Composition.GetDMRR_g_EnblCondSts <-> outer port GetDMRR_g_EnblCondSts
    delegate CPT_Cdd_Composition.VeBATR_U_12VoltSysSw <-> outer port VeBATR_U_12VoltSysSw
    delegate CPT_IoSigPwmInp_SwSStellantisCmpstn.VeDIOR_t_ElecPhsrDiag_PWM_Inp_PrdPW_Cohrnt <-> outer port VeDIOR_t_ElecPhsrDiag_PWM_Inp_PrdPW_Cohrnt
    delegate CPT_IoSigHbrdg_SwSStellantisCmpstn.VeDIOR_b_Hbrdg_DP_DiagCmn <-> outer port VeDIOR_b_Hbrdg_DP_DiagCmn
    delegate CPT_IoSigDioOutp_SwSStellantisCmpstn.VeDIOR_OilShutOffVlv_HwDiagFltOutp <-> outer port VeDIOR_OilShutOffVlv_HwDiagFltOutp
    delegate CPT_IoSigAdc_SwSStellantisCmpstn.VeADCR_U_VarGeomTrbFb <-> outer port VeADCR_U_VarGeomTrbFb
    delegate CPT_IoSigPwmInp_SwSStellantisCmpstn.KeCFGR_b_AllGrPosnSnsr1_ChEquid <-> outer port KeCFGR_b_AllGrPosnSnsr1_ChEquid
    delegate CPT_IoSigAdc_SwSStellantisCmpstn.FiveVoltAux <-> outer port FiveVoltAux
    delegate CPT_IoSigPwmInp_SwSStellantisCmpstn.VeDIOR_t_FPCM_Fb1_PWM_Inp_PrdPW_Cohrnt <-> outer port VeDIOR_t_FPCM_Fb1_PWM_Inp_PrdPW_Cohrnt
    delegate CPT_IoSigDioOutp_SwSStellantisCmpstn.VeDIOR_e_OilShutOffVlvIndDiagInfo <-> outer port VeDIOR_e_OilShutOffVlvIndDiagInfo
    delegate CPT_Cdd_Composition.VeBATR_U_12VoltSysAct <-> outer port VeBATR_U_12VoltSysAct
    delegate CPT_IoSigDioOutp_SwSStellantisCmpstn.VeDIOR_e_SwilEngMnt2IndDiagInfo <-> outer port VeDIOR_e_SwilEngMnt2IndDiagInfo
    delegate CPT_IoSigDioOutp_SwSStellantisCmpstn.KeCFGR_b_RadrFanRlyHiSpd_ChEquid <-> outer port KeCFGR_b_RadrFanRlyHiSpd_ChEquid
    delegate CPT_IoSigAdc_SwSStellantisCmpstn.GetADCR_U_VarGeomTrbFb <-> outer port GetADCR_U_VarGeomTrbFb
    delegate CPT_IoSigDioInp_SwSStellantisCmpstn.VeDIOR_t_BrkSwDigInpOffTi <-> outer port VeDIOR_t_BrkSwDigInpOffTi
    delegate CPT_IoSigDioOutp_SwSStellantisCmpstn.SetDIOR_b_ElectcVacPmpRlyOutpSt <-> outer port SetDIOR_b_ElectcVacPmpRlyOutpSt
    delegate CPT_IoSigAdc_SwSStellantisCmpstn.KeCFGR_b_FiveVoltAuxAdcInpEquid <-> outer port KeCFGR_b_FiveVoltAuxAdcInpEquid
    delegate CPT_IoSigPwmInp_SwSStellantisCmpstn.VeDIOR_t_AllGrPosnSnsr1_PWM_Inp_PrdPW_Cohrnt <-> outer port VeDIOR_t_AllGrPosnSnsr1_PWM_Inp_PrdPW_Cohrnt
    delegate CPT_IoSigPwmInp_SwSStellantisCmpstn.KeCFGR_b_AllGrPosnSnsr2_ChEquid <-> outer port KeCFGR_b_AllGrPosnSnsr2_ChEquid
    delegate CPT_IoSigDioOutp_SwSStellantisCmpstn.KeCFGR_b_SecdAirPmpRly_ChEquid <-> outer port KeCFGR_b_SecdAirPmpRly_ChEquid
    delegate CPT_IoSigDioOutp_SwSStellantisCmpstn.VeDIOR_OilShutOffVlv_HwDiagCmn <-> outer port VeDIOR_OilShutOffVlv_HwDiagCmn
    delegate CPT_IoSigDioInp_SwSStellantisCmpstn.VeDIOR_t_IgnRunStrtSwDigInpOffTi <-> outer port VeDIOR_t_IgnRunStrtSwDigInpOffTi
    delegate CPT_IoSigDioOutp_SwSStellantisCmpstn.VeDIOR_e_ElectcVacPmpRlyIndDiagInfo <-> outer port VeDIOR_e_ElectcVacPmpRlyIndDiagInfo
    delegate CPT_IoSigDioOutp_SwSStellantisCmpstn.VeDIOR_SecdAirShutOffSoln1_HwDiagFltOutp <-> outer port VeDIOR_SecdAirShutOffSoln1_HwDiagFltOutp
    delegate CPT_IoSigIfAdapt_SwSStellantisCmpstn.CheckSPLR_b_BattBackedRAM_Init <-> outer port CheckSPLR_b_BattBackedRAM_Init
    delegate CPT_IoSigPwmInp_SwSStellantisCmpstn.VeDIOR_t_AllGrPosnSnsr2_PWM_Inp_PrdPW_Cohrnt <-> outer port VeDIOR_t_AllGrPosnSnsr2_PWM_Inp_PrdPW_Cohrnt
    delegate CPT_IoSigDioOutp_SwSStellantisCmpstn.VeDIOR_e_SecdAirPmpRlyIndDiagInfo <-> outer port VeDIOR_e_SecdAirPmpRlyIndDiagInfo
    delegate CPT_IoSigDioOutp_SwSStellantisCmpstn.VeDIOR_VapBlockingVlv_HwDiagFltOutp <-> outer port VeDIOR_VapBlockingVlv_HwDiagFltOutp
    delegate CPT_IoSigHbrdg_SwSStellantisCmpstn.VeDIOR_b_Hbrdg_Wg1_DiagFltCircDftlDtctd <-> outer port VeDIOR_b_Hbrdg_Wg1_DiagFltCircDftlDtctd
    delegate CPT_IoSigDioOutp_SwSStellantisCmpstn.SetDIOR_b_VapBlockingVlvOutpSt <-> outer port SetDIOR_b_VapBlockingVlvOutpSt
    delegate CPT_IoSigDioOutp_SwSStellantisCmpstn.VeDIOR_SecdAirShutOffSoln1_HwDiagFltCircDtctd <-> outer port VeDIOR_SecdAirShutOffSoln1_HwDiagFltCircDtctd
    delegate CPT_IoSigHbrdg_SwSStellantisCmpstn.VeDIOR_b_Hbrdg_DP_DiagFltOutp <-> outer port VeDIOR_b_Hbrdg_DP_DiagFltOutp
    delegate CPT_IoSigHbrdg_SwSStellantisCmpstn.VeDIOR_b_Hbrdg_DP_DiagFltCircDftlDtctd <-> outer port VeDIOR_b_Hbrdg_DP_DiagFltCircDftlDtctd
    delegate CPT_ComVeh.VeCANR_b_ShiftLvrLockReqPT_FD3 <-> outer port VeCANR_b_ShiftLvrLockReqPT_FD3
    delegate CPT_ComVeh.SendCANR_EngBrkStat_FD3 <-> outer port SendCANR_EngBrkStat_FD3
    delegate CPT_ComVeh.SendCANR_LoadOBD_FD3Vld <-> outer port SendCANR_LoadOBD_FD3Vld
    delegate CPT_ComVeh.VeCANR_e_SpSt_Pad1_FD3 <-> outer port VeCANR_e_SpSt_Pad1_FD3
    delegate CPT_ComVeh.VeCANR_y_CRC_IBS3DATA1_FD3 <-> outer port VeCANR_y_CRC_IBS3DATA1_FD3
    delegate CPT_ComVeh.SendCANR_COOLING_REQ_STATUS_FD3Vld <-> outer port SendCANR_COOLING_REQ_STATUS_FD3Vld
    delegate CPT_ComVeh.SendCANR_CompressorSts_FD16Vld <-> outer port SendCANR_CompressorSts_FD16Vld
    delegate CPT_ComVeh.VeCANR_b_OilChgRst_FD3TO <-> outer port VeCANR_b_OilChgRst_FD3TO
    delegate CPT_ComVeh.SendCANR_StrtRlyBCMFdbckFltFD3 <-> outer port SendCANR_StrtRlyBCMFdbckFltFD3
    delegate CPT_ComVeh.SendCANR_CC_SetSpdDspl_KPH_FD3Vld <-> outer port SendCANR_CC_SetSpdDspl_KPH_FD3Vld
    delegate CPT_ComVeh.SendCANR_CRC_ENG_HYBD_FD_3FD16Vld <-> outer port SendCANR_CRC_ENG_HYBD_FD_3FD16Vld
    delegate CPT_ComVeh.VeCANR_b_AWD_Status_PT_FD3TO <-> outer port VeCANR_b_AWD_Status_PT_FD3TO
    delegate CPT_ComVeh.VeCANR_b_New_Spd_Zone_Ind_FD3TO <-> outer port VeCANR_b_New_Spd_Zone_Ind_FD3TO
    delegate CPT_ComVeh.VeCANR_b_StopStartClimateInfFD3TO <-> outer port VeCANR_b_StopStartClimateInfFD3TO
    delegate CPT_ComVeh.SendCANR_EngCltTmp_FD3 <-> outer port SendCANR_EngCltTmp_FD3
    delegate CPT_ComVeh.VeCANR_b_FuelFltrRst_FD3TO <-> outer port VeCANR_b_FuelFltrRst_FD3TO
    delegate CPT_ComVeh.SendCANR_ECMWkSiteInvtrStsFD3Vld <-> outer port SendCANR_ECMWkSiteInvtrStsFD3Vld
    delegate CPT_ComVeh.SendCANR_IgnCntrFuelEngTrue_FD3 <-> outer port SendCANR_IgnCntrFuelEngTrue_FD3
    delegate CPT_ComVeh.SendCANR_PTO_RPM1_FD3Vld <-> outer port SendCANR_PTO_RPM1_FD3Vld
    delegate CPT_ComVeh.SendCANR_CldStrtDenominatorFD16 <-> outer port SendCANR_CldStrtDenominatorFD16
    delegate CPT_ComVeh.VeCANR_b_RawPVS1_PT_FD3TO <-> outer port VeCANR_b_RawPVS1_PT_FD3TO
    delegate CPT_ComVeh.VeCANR_b_PTO_IdleSpd1_FD3 <-> outer port VeCANR_b_PTO_IdleSpd1_FD3
    delegate CPT_ComVeh.VeCANR_e_ChkFuelLevelSts2_FD3 <-> outer port VeCANR_e_ChkFuelLevelSts2_FD3
    delegate CPT_ComVeh.SendCANR_Lv1CrsCtrlOff_FD3Vld <-> outer port SendCANR_Lv1CrsCtrlOff_FD3Vld
    delegate CPT_ComVeh.SendCANR_ECM_WARN_BTO_1_FD3Vld <-> outer port SendCANR_ECM_WARN_BTO_1_FD3Vld
    delegate CPT_ComVeh.VeCANR_b_TSRSts_FD3TO <-> outer port VeCANR_b_TSRSts_FD3TO
    delegate CPT_ComVeh.SendCANR_TerModeDesiredStat_FD3Vld <-> outer port SendCANR_TerModeDesiredStat_FD3Vld
    delegate CPT_ComVeh.VeCANR_M_DrvrRqdAxTrqBSM_FD3 <-> outer port VeCANR_M_DrvrRqdAxTrqBSM_FD3
    delegate CPT_ComVeh.SendCANR_CRC_ENGINE7_FD16Vld <-> outer port SendCANR_CRC_ENGINE7_FD16Vld
    delegate CPT_ComVeh.SendCANR_ECM_MSG_RQ_FD3 <-> outer port SendCANR_ECM_MSG_RQ_FD3
    delegate CPT_ComVeh.SendCANR_EngHalfCylSpdMinLimFD3 <-> outer port SendCANR_EngHalfCylSpdMinLimFD3
    delegate CPT_ComVeh.VeCANR_Pct_DRV_TEMP_DR_PSPCTFD3 <-> outer port VeCANR_Pct_DRV_TEMP_DR_PSPCTFD3
    delegate CPT_ComVeh.SendCANR_EngOffTmPT_FD3 <-> outer port SendCANR_EngOffTmPT_FD3
    delegate CPT_ComVeh.VeCANR_T_ElecClntHtrInletTemFD3 <-> outer port VeCANR_T_ElecClntHtrInletTemFD3
    delegate CPT_ComVeh.SendCANR_AtmPresrFailSts_W_FD3 <-> outer port SendCANR_AtmPresrFailSts_W_FD3
    delegate CPT_ComVeh.SendCANR_GF_Charge_FD3 <-> outer port SendCANR_GF_Charge_FD3
    delegate CPT_ComVeh.SendCANR_EngineOilOverfill_FD3 <-> outer port SendCANR_EngineOilOverfill_FD3
    delegate CPT_ComVeh.VeCANR_b_TotalAxleMaxRq_BSM_FD3 <-> outer port VeCANR_b_TotalAxleMaxRq_BSM_FD3
    delegate CPT_ComVeh.SendCANR_OilLifeSts_FD3Vld <-> outer port SendCANR_OilLifeSts_FD3Vld
    delegate CPT_ComVeh.VeCANR_e_GPF_T2_Status_FD3 <-> outer port VeCANR_e_GPF_T2_Status_FD3
    delegate CPT_ComVeh.SendCANR_DEF_LOW_FD3 <-> outer port SendCANR_DEF_LOW_FD3
    delegate CPT_ComVeh.SendCANR_CarbWarmUp_FD16Vld <-> outer port SendCANR_CarbWarmUp_FD16Vld
    delegate CPT_ComVeh.SendCANR_BoostVacGauge_FD3Vld <-> outer port SendCANR_BoostVacGauge_FD3Vld
    delegate CPT_ComVeh.SendCANR_BarPrsAbs_FD3Vld <-> outer port SendCANR_BarPrsAbs_FD3Vld
    delegate CPT_ComVeh.VeCANR_e_EVCU2_THA_Resp_FD3 <-> outer port VeCANR_e_EVCU2_THA_Resp_FD3
    delegate CPT_ComVeh.SendCANR_CRC_ENG_HYBD_FD_4FD16 <-> outer port SendCANR_CRC_ENG_HYBD_FD_4FD16
    delegate CPT_ComVeh.SendCANR_EngTqCapbltyMaxTqFD16Vld <-> outer port SendCANR_EngTqCapbltyMaxTqFD16Vld
    delegate CPT_ComVeh.VeCANR_y_MC_ADAS_FD_HMI_FD3 <-> outer port VeCANR_y_MC_ADAS_FD_HMI_FD3
    delegate CPT_ComVeh.VeCANR_b_PdlPosActual_PT_FD3TO <-> outer port VeCANR_b_PdlPosActual_PT_FD3TO
    delegate CPT_ComVeh.VeCANR_b_Blower_Speed_FD3TO <-> outer port VeCANR_b_Blower_Speed_FD3TO
    delegate CPT_ComVeh.SendCANR_AGS2Posn_FD3Vld <-> outer port SendCANR_AGS2Posn_FD3Vld
    delegate CPT_ComVeh.SendCANR_CoolLo_FD3Vld <-> outer port SendCANR_CoolLo_FD3Vld
    delegate CPT_ComVeh.VeCANR_y_Year4_TLM_FD3 <-> outer port VeCANR_y_Year4_TLM_FD3
    delegate CPT_ComVeh.SendCANR_MC_ENG_HYBD_FD_3FD16 <-> outer port SendCANR_MC_ENG_HYBD_FD_3FD16
    delegate CPT_ComVeh.VeCANR_e_TerrainMdInfcBtnBCMFD3 <-> outer port VeCANR_e_TerrainMdInfcBtnBCMFD3
    delegate CPT_ComVeh.SendCANR_LgsDiagStndCondMet_FD3 <-> outer port SendCANR_LgsDiagStndCondMet_FD3
    delegate CPT_ComVeh.VeCANR_b_HVBatChargePwrShortV <-> outer port VeCANR_b_HVBatChargePwrShortV
    delegate CPT_ComVeh.SendCANR_CldStrtDenominatorFD16Vld <-> outer port SendCANR_CldStrtDenominatorFD16Vld
    delegate CPT_ComVeh.VeCANR_b_MessageCounter_IPC1FD3TO <-> outer port VeCANR_b_MessageCounter_IPC1FD3TO
    delegate CPT_ComVeh.VeCANR_b_ExtrnlTempADVoltageFD3TO <-> outer port VeCANR_b_ExtrnlTempADVoltageFD3TO
    delegate CPT_ComVeh.SendCANR_OilPressureSts_FD3Vld <-> outer port SendCANR_OilPressureSts_FD3Vld
    delegate CPT_ComVeh.VeCANR_U_RL_Lvl_RawAD_Src_FD3 <-> outer port VeCANR_U_RL_Lvl_RawAD_Src_FD3
    delegate CPT_ComVeh.SendCANR_EB_Pwr_FD3 <-> outer port SendCANR_EB_Pwr_FD3
    delegate CPT_ComVeh.VeCANR_b_RawPVS2_PT_FD3TO <-> outer port VeCANR_b_RawPVS2_PT_FD3TO
    delegate CPT_ComVeh.SendCANR_RadFanReq_FD3Vld <-> outer port SendCANR_RadFanReq_FD3Vld
    delegate CPT_ComVeh.VeCANR_b_HVBatChargePwrInstantV <-> outer port VeCANR_b_HVBatChargePwrInstantV
    delegate CPT_ComVeh.VeCANR_T_GPF_T2_TEMP_FD3 <-> outer port VeCANR_T_GPF_T2_TEMP_FD3
    delegate CPT_ComVeh.SendCANR_OilLifeLeftRst_FD3 <-> outer port SendCANR_OilLifeLeftRst_FD3
    delegate CPT_ComVeh.SendCANR_PTO_Md_FD3Vld <-> outer port SendCANR_PTO_Md_FD3Vld
    delegate CPT_ComVeh.VeCANR_b_LTR_PumpFlowReq_FD3TO <-> outer port VeCANR_b_LTR_PumpFlowReq_FD3TO
    delegate CPT_ComVeh.VeCANR_b_WorksitInverterActvFD3 <-> outer port VeCANR_b_WorksitInverterActvFD3
    delegate CPT_ComVeh.VeCANR_y_Hour2_TLM_FD3 <-> outer port VeCANR_y_Hour2_TLM_FD3
    delegate CPT_ComVeh.SendCANR_PTO_AutoRsm_FD3Vld <-> outer port SendCANR_PTO_AutoRsm_FD3Vld
    delegate CPT_ComVeh.SendCANR_EngOffTmPTV_FD3Vld <-> outer port SendCANR_EngOffTmPTV_FD3Vld
    delegate CPT_ComVeh.VeCANR_b_CRC_IPC1_FD3TO <-> outer port VeCANR_b_CRC_IPC1_FD3TO
    delegate CPT_ComVeh.SendCANR_MaxEngSpdCap_FD16 <-> outer port SendCANR_MaxEngSpdCap_FD16
    delegate CPT_ComVeh.SendCANR_EngTqACCCapabilityFD16Vld <-> outer port SendCANR_EngTqACCCapabilityFD16Vld
    delegate CPT_ComVeh.SendCANR_RemainDistUnt_FD3Vld <-> outer port SendCANR_RemainDistUnt_FD3Vld
    delegate CPT_ComVeh.VeCANR_b_Not_OK_To_Race_FD3TO <-> outer port VeCANR_b_Not_OK_To_Race_FD3TO
    delegate CPT_ComVeh.VeCANR_b_MessageCounter_BCM4FD3TO <-> outer port VeCANR_b_MessageCounter_BCM4FD3TO
    delegate CPT_ComVeh.VeCANR_v_Set_Speed_KPH_FD3 <-> outer port VeCANR_v_Set_Speed_KPH_FD3
    delegate CPT_ComVeh.SendCANR_SRV_CCV_FLTR_FD3Vld <-> outer port SendCANR_SRV_CCV_FLTR_FD3Vld
    delegate CPT_ComVeh.SendCANR_AGSposn_FD3Vld <-> outer port SendCANR_AGSposn_FD3Vld
    delegate CPT_ComVeh.VeCANR_Pct_IBS3_SOC_FD3 <-> outer port VeCANR_Pct_IBS3_SOC_FD3
    delegate CPT_ComVeh.SendCANR_ECM_AirflowRequest_FD3 <-> outer port SendCANR_ECM_AirflowRequest_FD3
    delegate CPT_ComVeh.SendCANR_Adblue_FL_LVL_FD3 <-> outer port SendCANR_Adblue_FL_LVL_FD3
    delegate CPT_ComVeh.VeCANR_b_AM_ECM_Trace_FD3TO <-> outer port VeCANR_b_AM_ECM_Trace_FD3TO
    delegate CPT_ComVeh.SendCANR_EngOffTmPTV_FD16 <-> outer port SendCANR_EngOffTmPTV_FD16
    delegate CPT_ComVeh.VeCANR_b_HVBatterySOCV_FD3 <-> outer port VeCANR_b_HVBatterySOCV_FD3
    delegate CPT_ComVeh.SendCANR_TerModeDesiredStatFD16Vld <-> outer port SendCANR_TerModeDesiredStatFD16Vld
    delegate CPT_ComVeh.SendCANR_SpeedLimitSts_FD3 <-> outer port SendCANR_SpeedLimitSts_FD3
    delegate CPT_ComVeh.SendCANR_EngineOperatingModeFD3 <-> outer port SendCANR_EngineOperatingModeFD3
    delegate CPT_ComVeh.VeCANR_b_HVBatterySOC_FD3TO <-> outer port VeCANR_b_HVBatterySOC_FD3TO
    delegate CPT_ComVeh.SendCANR_LoadOBD_FD3 <-> outer port SendCANR_LoadOBD_FD3
    delegate CPT_ComVeh.SendCANR_SpeedLimitSts_FD3Vld <-> outer port SendCANR_SpeedLimitSts_FD3Vld
    delegate CPT_ComVeh.SendCANR_EngTqCpbtRefEngSpdFD16Vld <-> outer port SendCANR_EngTqCpbtRefEngSpdFD16Vld
    delegate CPT_ComVeh.VeCANR_b_DRV_TEMP_DR_PSPCTFD3TO <-> outer port VeCANR_b_DRV_TEMP_DR_PSPCTFD3TO
    delegate CPT_ComVeh.SendCANR_PTO_Sts_FD3 <-> outer port SendCANR_PTO_Sts_FD3
    delegate CPT_ComVeh.VeCANR_b_SPMControlSts_FD3TO <-> outer port VeCANR_b_SPMControlSts_FD3TO
    delegate CPT_ComVeh.VeCANR_b_TransWarnings_PT_FD3TO <-> outer port VeCANR_b_TransWarnings_PT_FD3TO
    delegate CPT_ComVeh.SendCANR_EngOffTmPTV_FD3 <-> outer port SendCANR_EngOffTmPTV_FD3
    delegate CPT_ComVeh.SendCANR_EngCltTmp_FD3Vld <-> outer port SendCANR_EngCltTmp_FD3Vld
    delegate CPT_ComVeh.VeCANR_b_TransFailSts_PT_FD3 <-> outer port VeCANR_b_TransFailSts_PT_FD3
    delegate CPT_ComVeh.VeCANR_b_PTO_IdleSpd1_FD3TO <-> outer port VeCANR_b_PTO_IdleSpd1_FD3TO
    delegate CPT_ComVeh.VeCANR_b_HVBatChargePwrLongV_TO <-> outer port VeCANR_b_HVBatChargePwrLongV_TO
    delegate CPT_ComVeh.SendCANR_EngHalfCylSpdMaxLimFD3 <-> outer port SendCANR_EngHalfCylSpdMaxLimFD3
    delegate CPT_ComVeh.SendCANR_CARB_PERM_FD3Vld <-> outer port SendCANR_CARB_PERM_FD3Vld
    delegate CPT_ComVeh.SendCANR_Trns_DrvMdReq_ECM_FD3Vld <-> outer port SendCANR_Trns_DrvMdReq_ECM_FD3Vld
    delegate CPT_ComVeh.SendCANR_CompressorSts_FD16 <-> outer port SendCANR_CompressorSts_FD16
    delegate CPT_ComVeh.VeCANR_b_Warn_BTO_PT_FD3TO <-> outer port VeCANR_b_Warn_BTO_PT_FD3TO
    delegate CPT_ComVeh.VeCANR_e_CFG_Manual_DPF_FD3 <-> outer port VeCANR_e_CFG_Manual_DPF_FD3
    delegate CPT_ComVeh.VeCANR_b_MsgCtr_PT_SYS_FD_1_FD3TO <-> outer port VeCANR_b_MsgCtr_PT_SYS_FD_1_FD3TO
    delegate CPT_ComVeh.SendCANR_HoursOilLifeRst_FD3 <-> outer port SendCANR_HoursOilLifeRst_FD3
    delegate CPT_ComVeh.VeCANR_b_HAS_OnOffSts_FD3TO <-> outer port VeCANR_b_HAS_OnOffSts_FD3TO
    delegate CPT_ComVeh.SendCANR_PrcntCplt_FD3 <-> outer port SendCANR_PrcntCplt_FD3
    delegate CPT_ComVeh.SendCANR_HighPresrFuelSysFlrFD3Vld <-> outer port SendCANR_HighPresrFuelSysFlrFD3Vld
    delegate CPT_ComVeh.SendCANR_StrerPrctnTime_FD3 <-> outer port SendCANR_StrerPrctnTime_FD3
    delegate CPT_ComVeh.SendCANR_CRC_ENG_HYBD_FD_3FD16 <-> outer port SendCANR_CRC_ENG_HYBD_FD_3FD16
    delegate CPT_ComVeh.SendCANR_EngTqCpbtMaxOffTqFD16Vld <-> outer port SendCANR_EngTqCpbtMaxOffTqFD16Vld
    delegate CPT_ComVeh.SendCANR_HOOD_AJAR_STATUS_FD3 <-> outer port SendCANR_HOOD_AJAR_STATUS_FD3
    delegate CPT_ComVeh.SendCANR_TerrainHMIRq_ECM_FD16 <-> outer port SendCANR_TerrainHMIRq_ECM_FD16
    delegate CPT_ComVeh.SendCANR_BarPrsAbsV_FD3Vld <-> outer port SendCANR_BarPrsAbsV_FD3Vld
    delegate CPT_ComVeh.SendCANR_StartRlyECMFbFaultFD16Vld <-> outer port SendCANR_StartRlyECMFbFaultFD16Vld
    delegate CPT_ComVeh.SendCANR_GearShiftIndicationFD3 <-> outer port SendCANR_GearShiftIndicationFD3
    delegate CPT_ComVeh.VeCANR_e_TerrainSwStat_FD3 <-> outer port VeCANR_e_TerrainSwStat_FD3
    delegate CPT_ComVeh.VeCANR_b_ESS_RqShftPark_PT_FD3 <-> outer port VeCANR_b_ESS_RqShftPark_PT_FD3
    delegate CPT_ComVeh.VeCANR_b_TotalOdometer_FD3TO <-> outer port VeCANR_b_TotalOdometer_FD3TO
    delegate CPT_ComVeh.SendCANR_OilPressureSts_FD3 <-> outer port SendCANR_OilPressureSts_FD3
    delegate CPT_ComVeh.SendCANR_CRC_ENGINE8_FD3 <-> outer port SendCANR_CRC_ENGINE8_FD3
    delegate CPT_ComVeh.SendCANR_OIL_TEMP_IND_RQ_FD3 <-> outer port SendCANR_OIL_TEMP_IND_RQ_FD3
    delegate CPT_ComVeh.VeCANR_b_HeaterCoreInletTempFD3TO <-> outer port VeCANR_b_HeaterCoreInletTempFD3TO
    delegate CPT_ComVeh.VeCANR_y_CRC_Hyb_Therm_Cmd_FD16 <-> outer port VeCANR_y_CRC_Hyb_Therm_Cmd_FD16
    delegate CPT_ComVeh.SendCANR_PTORemoteRPMMethod_FD3Vld <-> outer port SendCANR_PTORemoteRPMMethod_FD3Vld
    delegate CPT_ComVeh.VeCANR_b_Minute2_TLM_FD3TO <-> outer port VeCANR_b_Minute2_TLM_FD3TO
    delegate CPT_ComVeh.VeCANR_U_Battery_Volt_1_FD3 <-> outer port VeCANR_U_Battery_Volt_1_FD3
    delegate CPT_ComVeh.VeCANR_T_ExternalTempC_FD3 <-> outer port VeCANR_T_ExternalTempC_FD3
    delegate CPT_ComVeh.SendCANR_OilLifeLeftRst_FD3Vld <-> outer port SendCANR_OilLifeLeftRst_FD3Vld
    delegate CPT_ComVeh.SendCANR_OAT_PT_EstV_FD3Vld <-> outer port SendCANR_OAT_PT_EstV_FD3Vld
    delegate CPT_ComVeh.SendCANR_IgnCntrTrue_FD3Vld <-> outer port SendCANR_IgnCntrTrue_FD3Vld
    delegate CPT_ComVeh.VeCANR_b_CRC_IBS3DATA1_FD3TO <-> outer port VeCANR_b_CRC_IBS3DATA1_FD3TO
    delegate CPT_ComVeh.SendCANR_CatHtgStateActive_FD3Vld <-> outer port SendCANR_CatHtgStateActive_FD3Vld
    delegate CPT_ComVeh.VeCANR_e_EPS_Warn_Disp_Rq_FD3 <-> outer port VeCANR_e_EPS_Warn_Disp_Rq_FD3
    delegate CPT_ComVeh.SendCANR_CoolVlvPos_FD3 <-> outer port SendCANR_CoolVlvPos_FD3
    delegate CPT_ComVeh.SendCANR_CoolVlvPos_FD3Vld <-> outer port SendCANR_CoolVlvPos_FD3Vld
    delegate CPT_ComVeh.SendCANR_HP_MODE_STS_FD3 <-> outer port SendCANR_HP_MODE_STS_FD3
    delegate CPT_ComVeh.SendCANR_EngCltTmpV_FD16 <-> outer port SendCANR_EngCltTmpV_FD16
    delegate CPT_ComVeh.SendCANR_MC_ENG_HYBD_FD_4FD16 <-> outer port SendCANR_MC_ENG_HYBD_FD_4FD16
    delegate CPT_ComVeh.SendCANR_ECM_WARN_FD3Vld <-> outer port SendCANR_ECM_WARN_FD3Vld
    delegate CPT_ComVeh.SendCANR_StrtRlyBCMFdbckFltFD3Vld <-> outer port SendCANR_StrtRlyBCMFdbckFltFD3Vld
    delegate CPT_ComVeh.VeCANR_Pct_GasPdlPsnPT_FD3 <-> outer port VeCANR_Pct_GasPdlPsnPT_FD3
    delegate CPT_ComVeh.VeCANR_b_TotalAxle_Rq_BSM_FD3TO <-> outer port VeCANR_b_TotalAxle_Rq_BSM_FD3TO
    delegate CPT_ComVeh.SendCANR_ECM_FOTA_Conflict_FD3 <-> outer port SendCANR_ECM_FOTA_Conflict_FD3
    delegate CPT_ComVeh.SendCANR_DistOilLifeRst_FD3 <-> outer port SendCANR_DistOilLifeRst_FD3
    delegate CPT_ComVeh.SendCANR_VehicleSetSpeed_W_FD3 <-> outer port SendCANR_VehicleSetSpeed_W_FD3
    delegate CPT_ComVeh.VeCANR_y_MC_IBS3DATA1_FD3 <-> outer port VeCANR_y_MC_IBS3DATA1_FD3
    delegate CPT_ComVeh.VeCANR_b_Launch_SftBtnstatusFD3 <-> outer port VeCANR_b_Launch_SftBtnstatusFD3
    delegate CPT_ComVeh.SendCANR_LgsDgCldStCndFltPrFD3 <-> outer port SendCANR_LgsDgCldStCndFltPrFD3
    delegate CPT_ComVeh.SendCANR_EngTqCpbtFrmCntrFD16Vld <-> outer port SendCANR_EngTqCpbtFrmCntrFD16Vld
    delegate CPT_ComVeh.SendCANR_EB_ACC_AVLBL_FD3 <-> outer port SendCANR_EB_ACC_AVLBL_FD3
    delegate CPT_ComVeh.VeCANR_b_CRC_BCM4_FD3TO <-> outer port VeCANR_b_CRC_BCM4_FD3TO
    delegate CPT_ComVeh.SendCANR_EngMaxRPM_W_FD3 <-> outer port SendCANR_EngMaxRPM_W_FD3
    delegate CPT_ComVeh.VeCANR_b_PSI_Gr4_RPM_SET_FD3TO <-> outer port VeCANR_b_PSI_Gr4_RPM_SET_FD3TO
    delegate CPT_ComVeh.SendCANR_ECM_TRSC_Resp_FD3Vld <-> outer port SendCANR_ECM_TRSC_Resp_FD3Vld
    delegate CPT_ComVeh.SendCANR_TerModIntrfcBtnECM_FD3Vld <-> outer port SendCANR_TerModIntrfcBtnECM_FD3Vld
    delegate CPT_ComVeh.SendCANR_LgsDiagStdCdFltPrs_FD3 <-> outer port SendCANR_LgsDiagStdCdFltPrs_FD3
    delegate CPT_ComVeh.SendCANR_InputsGDFail_FD16Vld <-> outer port SendCANR_InputsGDFail_FD16Vld
    delegate CPT_ComVeh.VeCANR_b_DisplayedSpdLimSts_FD3TO <-> outer port VeCANR_b_DisplayedSpdLimSts_FD3TO
    delegate CPT_ComVeh.SendCANR_EB_Stat3_FD3Vld <-> outer port SendCANR_EB_Stat3_FD3Vld
    delegate CPT_ComVeh.SendCANR_RapidCbnWrmupStat_FD3 <-> outer port SendCANR_RapidCbnWrmupStat_FD3
    delegate CPT_ComVeh.VeCANR_b_HVBattRealTimeClkVFD3 <-> outer port VeCANR_b_HVBattRealTimeClkVFD3
    delegate CPT_ComVeh.SendCANR_EngMaxRPM_W_FD3Vld <-> outer port SendCANR_EngMaxRPM_W_FD3Vld
    delegate CPT_ComVeh.VeCANR_b_CODE_CLR_BPCM_FD3 <-> outer port VeCANR_b_CODE_CLR_BPCM_FD3
    delegate CPT_ComVeh.SendCANR_LTR_TARGET_TEMP_FD3 <-> outer port SendCANR_LTR_TARGET_TEMP_FD3
    delegate CPT_ComVeh.SendCANR_PTO_Incab_FD3 <-> outer port SendCANR_PTO_Incab_FD3
    delegate CPT_ComVeh.SendCANR_AtmPressure_W_FD3 <-> outer port SendCANR_AtmPressure_W_FD3
    delegate CPT_ComVeh.VeCANR_b_Year3_TLM_FD3TO <-> outer port VeCANR_b_Year3_TLM_FD3TO
    delegate CPT_ComVeh.SendCANR_CRC_ENGINE7_FD3Vld <-> outer port SendCANR_CRC_ENGINE7_FD3Vld
    delegate CPT_ComVeh.SendCANR_TransWarmUpMin_RPMFD16Vld <-> outer port SendCANR_TransWarmUpMin_RPMFD16Vld
    delegate CPT_ComVeh.VeCANR_b_IdleShutDown_Dsbl_FD3TO <-> outer port VeCANR_b_IdleShutDown_Dsbl_FD3TO
    delegate CPT_ComVeh.SendCANR_MC_OBDCONTENTFRAMEFD16Vld <-> outer port SendCANR_MC_OBDCONTENTFRAMEFD16Vld
    delegate CPT_ComVeh.SendCANR_PTO_Acc_Intlk_FD3Vld <-> outer port SendCANR_PTO_Acc_Intlk_FD3Vld
    delegate CPT_ComVeh.SendCANR_ENGINE_RESET_FD3Vld <-> outer port SendCANR_ENGINE_RESET_FD3Vld
    delegate CPT_ComVeh.SendCANR_EngIntAirTmpV_FD3Vld <-> outer port SendCANR_EngIntAirTmpV_FD3Vld
    delegate CPT_ComVeh.SendCANR_ThrmlMngmtActive_WFD16Vld <-> outer port SendCANR_ThrmlMngmtActive_WFD16Vld
    delegate CPT_ComVeh.VeCANR_b_IdleShutDown_Dsbl_FD3 <-> outer port VeCANR_b_IdleShutDown_Dsbl_FD3
    delegate CPT_ComVeh.VeCANR_n_PSI_Gr2_RPM_SET_FD3 <-> outer port VeCANR_n_PSI_Gr2_RPM_SET_FD3
    delegate CPT_ComVeh.SendCANR_ECM_WARN_BTO_1_FD3 <-> outer port SendCANR_ECM_WARN_BTO_1_FD3
    delegate CPT_ComVeh.SendCANR_EngineOilLevel_FD3 <-> outer port SendCANR_EngineOilLevel_FD3
    delegate CPT_ComVeh.VeCANR_b_EPS_Warn_Disp_Rq_FD3TO <-> outer port VeCANR_b_EPS_Warn_Disp_Rq_FD3TO
    delegate CPT_ComVeh.SendCANR_RawTPS1_FD3 <-> outer port SendCANR_RawTPS1_FD3
    delegate CPT_ComVeh.VeCANR_b_IMPACTConfirm_FD3TO <-> outer port VeCANR_b_IMPACTConfirm_FD3TO
    delegate CPT_ComVeh.VeCANR_b_HVBatChargePwrInstantV_TO <-> outer port VeCANR_b_HVBatChargePwrInstantV_TO
    delegate CPT_ComVeh.VeCANR_b_CrankEnable_PT_FD3 <-> outer port VeCANR_b_CrankEnable_PT_FD3
    delegate CPT_ComVeh.VeCANR_y_CRC_IPC1_FD3 <-> outer port VeCANR_y_CRC_IPC1_FD3
    delegate CPT_ComVeh.VeCANR_b_IMPACTConfirm_FD3 <-> outer port VeCANR_b_IMPACTConfirm_FD3
    delegate CPT_ComVeh.SendCANR_EngineOilOverfill_FD3Vld <-> outer port SendCANR_EngineOilOverfill_FD3Vld
    delegate CPT_ComVeh.SendCANR_CRC_OBDCONTENTFRAMEFD3Vld <-> outer port SendCANR_CRC_OBDCONTENTFRAMEFD3Vld
    delegate CPT_ComVeh.SendCANR_RadFanReq_FD3 <-> outer port SendCANR_RadFanReq_FD3
    delegate CPT_ComVeh.VeCANR_b_GearEngaged_PT_FD3TO <-> outer port VeCANR_b_GearEngaged_PT_FD3TO
    delegate CPT_ComVeh.VeCANR_b_GPF_T2_TEMP_FD3TO <-> outer port VeCANR_b_GPF_T2_TEMP_FD3TO
    delegate CPT_ComVeh.VeCANR_b_PSI_Gr3_RPM_SET_FD3TO <-> outer port VeCANR_b_PSI_Gr3_RPM_SET_FD3TO
    delegate CPT_ComVeh.VeCANR_b_Day1_TLM_FD3TO <-> outer port VeCANR_b_Day1_TLM_FD3TO
    delegate CPT_ComVeh.SendCANR_VehicleSetSpeed_W_FD16Vld <-> outer port SendCANR_VehicleSetSpeed_W_FD16Vld
    delegate CPT_ComVeh.SendCANR_EngTqCpbtMinRunTqFD16 <-> outer port SendCANR_EngTqCpbtMinRunTqFD16
    delegate CPT_ComVeh.VeCANR_b_Right_Button_BCM_FD3TO <-> outer port VeCANR_b_Right_Button_BCM_FD3TO
    delegate CPT_ComVeh.VeCANR_b_ShiftLvrLockReqPT_FD3TO <-> outer port VeCANR_b_ShiftLvrLockReqPT_FD3TO
    delegate CPT_ComVeh.VeCANR_b_IMPACTCommand_FD3 <-> outer port VeCANR_b_IMPACTCommand_FD3
    delegate CPT_ComVeh.SendCANR_Trns_DrvMdReq_ECM_FD3 <-> outer port SendCANR_Trns_DrvMdReq_ECM_FD3
    delegate CPT_ComVeh.VeCANR_e_VehSpdOverriddenPT_FD3 <-> outer port VeCANR_e_VehSpdOverriddenPT_FD3
    delegate CPT_ComVeh.SendCANR_ThrmlMngmtActive_WFD16 <-> outer port SendCANR_ThrmlMngmtActive_WFD16
    delegate CPT_ComVeh.SendCANR_CRC_ENGINE6_FD3Vld <-> outer port SendCANR_CRC_ENGINE6_FD3Vld
    delegate CPT_ComVeh.SendCANR_PSI_EnableSts_FD3Vld <-> outer port SendCANR_PSI_EnableSts_FD3Vld
    delegate CPT_ComVeh.SendCANR_EngTqCpbtMaxOffTqFD16 <-> outer port SendCANR_EngTqCpbtMaxOffTqFD16
    delegate CPT_ComVeh.SendCANR_EngTqCpbtEngOpMd_FD3 <-> outer port SendCANR_EngTqCpbtEngOpMd_FD3
    delegate CPT_ComVeh.SendCANR_RawPVS1_FD3 <-> outer port SendCANR_RawPVS1_FD3
    delegate CPT_ComVeh.SendCANR_EngineWaterTemp_FD3 <-> outer port SendCANR_EngineWaterTemp_FD3
    delegate CPT_ComVeh.SendCANR_CRC_OBDCNTNFRAMEFD16Vld <-> outer port SendCANR_CRC_OBDCNTNFRAMEFD16Vld
    delegate CPT_ComVeh.SendCANR_ThrottlePosition_FD3 <-> outer port SendCANR_ThrottlePosition_FD3
    delegate CPT_ComVeh.VeCANR_y_MC_DRIVETRAIN3_FD3 <-> outer port VeCANR_y_MC_DRIVETRAIN3_FD3
    delegate CPT_ComVeh.VeCANR_e_TerrainModeStat_PT_FD3 <-> outer port VeCANR_e_TerrainModeStat_PT_FD3
    delegate CPT_ComVeh.VeCANR_b_Command_15Sts_FD3TO <-> outer port VeCANR_b_Command_15Sts_FD3TO
    delegate CPT_ComVeh.SendCANR_RawTPS2_FD3 <-> outer port SendCANR_RawTPS2_FD3
    delegate CPT_ComVeh.SendCANR_EB_ACC_AVLBL_FD3Vld <-> outer port SendCANR_EB_ACC_AVLBL_FD3Vld
    delegate CPT_ComVeh.SendCANR_CC_SetSpdDspl_KPH_FD3 <-> outer port SendCANR_CC_SetSpdDspl_KPH_FD3
    delegate CPT_ComVeh.SendCANR_CarbWarmUp_FD3 <-> outer port SendCANR_CarbWarmUp_FD3
    delegate CPT_ComVeh.SendCANR_PTWkSiteInvtrStsECMFD3Vld <-> outer port SendCANR_PTWkSiteInvtrStsECMFD3Vld
    delegate CPT_ComVeh.SendCANR_Terrain_HMI_Rq_ECM_FD3 <-> outer port SendCANR_Terrain_HMI_Rq_ECM_FD3
    delegate CPT_ComVeh.SendCANR_SpStSwStat_FD16 <-> outer port SendCANR_SpStSwStat_FD16
    delegate CPT_ComVeh.SendCANR_BrkSw2Stat_FD3Vld <-> outer port SendCANR_BrkSw2Stat_FD3Vld
    delegate CPT_ComVeh.SendCANR_ECMWkSiteInvtrStsFD3 <-> outer port SendCANR_ECMWkSiteInvtrStsFD3
    delegate CPT_ComVeh.VeCANR_U_FUEL_VOLT2_FD3 <-> outer port VeCANR_U_FUEL_VOLT2_FD3
    delegate CPT_ComVeh.VeCANR_b_GlobDrvMdRq_BCM_FD3TO <-> outer port VeCANR_b_GlobDrvMdRq_BCM_FD3TO
    delegate CPT_ComVeh.VeCANR_b_CRC_ADAS_FD_HMI_FD3TO <-> outer port VeCANR_b_CRC_ADAS_FD_HMI_FD3TO
    delegate CPT_ComVeh.VeCANR_b_PowerShot_BCM_FD3TO <-> outer port VeCANR_b_PowerShot_BCM_FD3TO
    delegate CPT_ComVeh.SendCANR_CRC_ENGINE7_FD3 <-> outer port SendCANR_CRC_ENGINE7_FD3
    delegate CPT_ComVeh.SendCANR_OIL_TEMP_CHM_RQ_FD3 <-> outer port SendCANR_OIL_TEMP_CHM_RQ_FD3
    delegate CPT_ComVeh.VeCANR_b_TerrainModeStat_PT_FD3TO <-> outer port VeCANR_b_TerrainModeStat_PT_FD3TO
    delegate CPT_ComVeh.VeCANR_y_CRC_PT_SYSTEM_FD_1_FD3 <-> outer port VeCANR_y_CRC_PT_SYSTEM_FD_1_FD3
    delegate CPT_ComVeh.VeCANR_n_PSI_Gr1_RPM_SET_FD3 <-> outer port VeCANR_n_PSI_Gr1_RPM_SET_FD3
    delegate CPT_ComVeh.VeCANR_phi_LwsAngle_SCCM_FD3 <-> outer port VeCANR_phi_LwsAngle_SCCM_FD3
    delegate CPT_ComVeh.SendCANR_LgsDgCldStCndFltPrFD3Vld <-> outer port SendCANR_LgsDgCldStCndFltPrFD3Vld
    delegate CPT_ComVeh.SendCANR_RefuelEvent_FD3Vld <-> outer port SendCANR_RefuelEvent_FD3Vld
    delegate CPT_ComVeh.SendCANR_ECM_Thrml_AADReq_FD3 <-> outer port SendCANR_ECM_Thrml_AADReq_FD3
    delegate CPT_ComVeh.SendCANR_Inp_ICC_Fail_FD16Vld <-> outer port SendCANR_Inp_ICC_Fail_FD16Vld
    delegate CPT_ComVeh.SendCANR_CRC_ENGINE8_FD3Vld <-> outer port SendCANR_CRC_ENGINE8_FD3Vld
    delegate CPT_ComVeh.SendCANR_PTO_RPM3_FD3Vld <-> outer port SendCANR_PTO_RPM3_FD3Vld
    delegate CPT_ComVeh.SendCANR_AtmrcPressure_W_FD16 <-> outer port SendCANR_AtmrcPressure_W_FD16
    delegate CPT_ComVeh.VeCANR_b_MsgCtr_BRAKE_FD_6_FD3TO <-> outer port VeCANR_b_MsgCtr_BRAKE_FD_6_FD3TO
    delegate CPT_ComVeh.SendCANR_TrnsDrvMdCfgStsECMFD3 <-> outer port SendCANR_TrnsDrvMdCfgStsECMFD3
    delegate CPT_ComVeh.SendCANR_EngineOperatingModeFD3Vld <-> outer port SendCANR_EngineOperatingModeFD3Vld
    delegate CPT_ComVeh.SendCANR_ECM_WARN_BTO_FD3Vld <-> outer port SendCANR_ECM_WARN_BTO_FD3Vld
    delegate CPT_ComVeh.SendCANR_AtmPresrFailSts_W_FD3Vld <-> outer port SendCANR_AtmPresrFailSts_W_FD3Vld
    delegate CPT_ComVeh.VeCANR_b_Sport_Request_FD3TO <-> outer port VeCANR_b_Sport_Request_FD3TO
    delegate CPT_ComVeh.VeCANR_b_ElecClntHtrInletTemFD3TO <-> outer port VeCANR_b_ElecClntHtrInletTemFD3TO
    delegate CPT_ComVeh.VeCANR_b_AtmPressure_PT_FD3TO <-> outer port VeCANR_b_AtmPressure_PT_FD3TO
    delegate CPT_ComVeh.SendCANR_FuelMM_Sts_FD3Vld <-> outer port SendCANR_FuelMM_Sts_FD3Vld
    delegate CPT_ComVeh.SendCANR_PreHtlmpEVICOnRq_FD3Vld <-> outer port SendCANR_PreHtlmpEVICOnRq_FD3Vld
    delegate CPT_ComVeh.SendCANR_RefuelIndication_FD3Vld <-> outer port SendCANR_RefuelIndication_FD3Vld
    delegate CPT_ComVeh.SendCANR_PTO_Acc_Intlk_FD3 <-> outer port SendCANR_PTO_Acc_Intlk_FD3
    delegate CPT_ComVeh.SendCANR_WtrFuelIndLmpOnRq_FD3 <-> outer port SendCANR_WtrFuelIndLmpOnRq_FD3
    delegate CPT_ComVeh.VeCANR_b_Day2_TLM_FD3TO <-> outer port VeCANR_b_Day2_TLM_FD3TO
    delegate CPT_ComVeh.VeCANR_b_GasPdlPsnPT_FD3TO <-> outer port VeCANR_b_GasPdlPsnPT_FD3TO
    delegate CPT_ComVeh.VeCANR_e_FOTA_Status_FD3 <-> outer port VeCANR_e_FOTA_Status_FD3
    delegate CPT_ComVeh.VeCANR_e_TSRSts_FD3 <-> outer port VeCANR_e_TSRSts_FD3
    delegate CPT_ComVeh.VeCANR_b_HTAuxPmpMontrngRPM_FD3TO <-> outer port VeCANR_b_HTAuxPmpMontrngRPM_FD3TO
    delegate CPT_ComVeh.SendCANR_CatHtgStateActive_FD3 <-> outer port SendCANR_CatHtgStateActive_FD3
    delegate CPT_ComVeh.SendCANR_AccelPdlPosn_OBD_FD3Vld <-> outer port SendCANR_AccelPdlPosn_OBD_FD3Vld
    delegate CPT_ComVeh.SendCANR_InputsGDFail_FD3 <-> outer port SendCANR_InputsGDFail_FD3
    delegate CPT_ComVeh.SendCANR_AM_ECM_Prsnt_FD3Vld <-> outer port SendCANR_AM_ECM_Prsnt_FD3Vld
    delegate CPT_ComVeh.SendCANR_CRC_ENGINE6_FD3 <-> outer port SendCANR_CRC_ENGINE6_FD3
    delegate CPT_ComVeh.VeCANR_b_GlobDrvMdRq_FD3TO <-> outer port VeCANR_b_GlobDrvMdRq_FD3TO
    delegate CPT_ComVeh.SendCANR_PSI_Max_RPM_FD3Vld <-> outer port SendCANR_PSI_Max_RPM_FD3Vld
    delegate CPT_ComVeh.SendCANR_TerrainModeStat_ECMFD3 <-> outer port SendCANR_TerrainModeStat_ECMFD3
    delegate CPT_ComVeh.SendCANR_EngTqCpbtEngOpMd_FD3Vld <-> outer port SendCANR_EngTqCpbtEngOpMd_FD3Vld
    delegate CPT_ComVeh.SendCANR_PrcntCplt_FD3Vld <-> outer port SendCANR_PrcntCplt_FD3Vld
    delegate CPT_ComVeh.SendCANR_PECP_PumpFlowReq_FD3Vld <-> outer port SendCANR_PECP_PumpFlowReq_FD3Vld
    delegate CPT_ComVeh.VeCANR_b_CFG_Manual_DPF_FD3TO <-> outer port VeCANR_b_CFG_Manual_DPF_FD3TO
    delegate CPT_ComVeh.VeCANR_b_HVBatChargePwrShortV_TO <-> outer port VeCANR_b_HVBatChargePwrShortV_TO
    delegate CPT_ComVeh.SendCANR_MC_ENG1FD16 <-> outer port SendCANR_MC_ENG1FD16
    delegate CPT_ComVeh.SendCANR_TransWarmUpReq_FD3Vld <-> outer port SendCANR_TransWarmUpReq_FD3Vld
    delegate CPT_ComVeh.VeCANR_b_VehSpdOverriddenPT_FD3TO <-> outer port VeCANR_b_VehSpdOverriddenPT_FD3TO
    delegate CPT_ComVeh.SendCANR_ThrmlMngmtActvW_FD3Vld <-> outer port SendCANR_ThrmlMngmtActvW_FD3Vld
    delegate CPT_ComVeh.SendCANR_ECM_HMI_Timer_RQ_FD3 <-> outer port SendCANR_ECM_HMI_Timer_RQ_FD3
    delegate CPT_ComVeh.VeCANR_b_HVAC_CLNT_FLW_MIN_FD3TO <-> outer port VeCANR_b_HVAC_CLNT_FLW_MIN_FD3TO
    delegate CPT_ComVeh.VeCANR_b_Month2_TLM_FD3TO <-> outer port VeCANR_b_Month2_TLM_FD3TO
    delegate CPT_ComVeh.SendCANR_Inp_ICC_Fail_FD3Vld <-> outer port SendCANR_Inp_ICC_Fail_FD3Vld
    delegate CPT_ComVeh.VeCANR_b_R_SHFT_LOCK_PT_FD3 <-> outer port VeCANR_b_R_SHFT_LOCK_PT_FD3
    delegate CPT_ComVeh.VeCANR_b_IBS3_Error_InternalFD3 <-> outer port VeCANR_b_IBS3_Error_InternalFD3
    delegate CPT_ComVeh.VeCANR_b_ParkingSts_PT_FD3 <-> outer port VeCANR_b_ParkingSts_PT_FD3
    delegate CPT_ComVeh.VeCANR_b_TotalAxleMaxRq_BSM_FD3TO <-> outer port VeCANR_b_TotalAxleMaxRq_BSM_FD3TO
    delegate CPT_ComVeh.SendCANR_ECM_HoodAjar_FD3Vld <-> outer port SendCANR_ECM_HoodAjar_FD3Vld
    delegate CPT_ComVeh.VeCANR_b_DriverPowerReq_PT_FD3TO <-> outer port VeCANR_b_DriverPowerReq_PT_FD3TO
    delegate CPT_ComVeh.SendCANR_PTO_HornRq_FD3Vld <-> outer port SendCANR_PTO_HornRq_FD3Vld
    delegate CPT_ComVeh.VeCANR_b_CODE_CLR_BPCM_FD3TO <-> outer port VeCANR_b_CODE_CLR_BPCM_FD3TO
    delegate CPT_ComVeh.SendCANR_AfterRunReq_FD3 <-> outer port SendCANR_AfterRunReq_FD3
    delegate CPT_ComVeh.SendCANR_PTOParkBrkRequired_FD3Vld <-> outer port SendCANR_PTOParkBrkRequired_FD3Vld
    delegate CPT_ComVeh.VeCANR_P_HVBatChargePwrInstant <-> outer port VeCANR_P_HVBatChargePwrInstant
    delegate CPT_ComVeh.VeCANR_b_CRC_DRIVETRAIN3_FD3TO <-> outer port VeCANR_b_CRC_DRIVETRAIN3_FD3TO
    delegate CPT_ComVeh.SendCANR_EngTqCpbtRefEngSpdFD16 <-> outer port SendCANR_EngTqCpbtRefEngSpdFD16
    delegate CPT_ComVeh.SendCANR_IgnCntrTrue_FD3 <-> outer port SendCANR_IgnCntrTrue_FD3
    delegate CPT_ComVeh.SendCANR_CRC_ENGINE8_FD16 <-> outer port SendCANR_CRC_ENGINE8_FD16
    delegate CPT_ComVeh.SendCANR_ECM_AirflowRequest_FD3Vld <-> outer port SendCANR_ECM_AirflowRequest_FD3Vld
    delegate CPT_ComVeh.SendCANR_FuelConsumption_GAGFD3 <-> outer port SendCANR_FuelConsumption_GAGFD3
